VERSION ""

NS_ :

BS_:

BU_:  Battery  Charger  Host

BO_ 2566862841 BATT_diagnosticVBricksD_3: 4 Battery
 SG_ BATT_vBrick14_3 : 16|16@1+ (7.6e-05,0) [0|4.98066] "V" Host
 SG_ BATT_vBrick13_3 : 0|16@1+ (7.6e-05,0) [0|4.98066] "V" Host

BO_ 2566862842 BATT_diagnosticVBricksD_4: 4 Battery
 SG_ BATT_vBrick14_4 : 16|16@1+ (7.6e-05,0) [0|4.98066] "V" Host
 SG_ BATT_vBrick13_4 : 0|16@1+ (7.6e-05,0) [0|4.98066] "V" Host

BO_ 2566862843 BATT_diagnosticVBricksD_5: 4 Battery
 SG_ BATT_vBrick14_5 : 16|16@1+ (7.6e-05,0) [0|4.98066] "V" Host
 SG_ BATT_vBrick13_5 : 0|16@1+ (7.6e-05,0) [0|4.98066] "V" Host

BO_ 2566862844 BATT_diagnosticVBricksD_6: 4 Battery
 SG_ BATT_vBrick14_6 : 16|16@1+ (7.6e-05,0) [0|4.98066] "V" Host
 SG_ BATT_vBrick13_6 : 0|16@1+ (7.6e-05,0) [0|4.98066] "V" Host

BO_ 2566862845 BATT_diagnosticVBricksD_7: 4 Battery
 SG_ BATT_vBrick14_7 : 16|16@1+ (7.6e-05,0) [0|4.98066] "V" Host
 SG_ BATT_vBrick13_7 : 0|16@1+ (7.6e-05,0) [0|4.98066] "V" Host

BO_ 2566862846 BATT_diagnosticVBricksD_8: 4 Battery
 SG_ BATT_vBrick14_8 : 16|16@1+ (7.6e-05,0) [0|4.98066] "V" Host
 SG_ BATT_vBrick13_8 : 0|16@1+ (7.6e-05,0) [0|4.98066] "V" Host

BO_ 2566862847 BATT_diagnosticVBricksD_9: 4 Battery
 SG_ BATT_vBrick14_9 : 16|16@1+ (7.6e-05,0) [0|4.98066] "V" Host
 SG_ BATT_vBrick13_9 : 0|16@1+ (7.6e-05,0) [0|4.98066] "V" Host

BO_ 2566863094 BATT_diagnosticResBricksD_0: 4 Battery
 SG_ BATT_resBrick14_0 : 16|16@1+ (0.01,0) [0|655.35] "mOhms" Host
 SG_ BATT_resBrick13_0 : 0|16@1+ (0.01,0) [0|655.35] "mOhms" Host

BO_ 2566863095 BATT_diagnosticResBricksD_1: 4 Battery
 SG_ BATT_resBrick14_1 : 16|16@1+ (0.01,0) [0|655.35] "mOhms" Host
 SG_ BATT_resBrick13_1 : 0|16@1+ (0.01,0) [0|655.35] "mOhms" Host

BO_ 2566863096 BATT_diagnosticResBricksD_2: 4 Battery
 SG_ BATT_resBrick14_2 : 16|16@1+ (0.01,0) [0|655.35] "mOhms" Host
 SG_ BATT_resBrick13_2 : 0|16@1+ (0.01,0) [0|655.35] "mOhms" Host

BO_ 2566863097 BATT_diagnosticResBricksD_3: 4 Battery
 SG_ BATT_resBrick14_3 : 16|16@1+ (0.01,0) [0|655.35] "mOhms" Host
 SG_ BATT_resBrick13_3 : 0|16@1+ (0.01,0) [0|655.35] "mOhms" Host

BO_ 2566863098 BATT_diagnosticResBricksD_4: 4 Battery
 SG_ BATT_resBrick14_4 : 16|16@1+ (0.01,0) [0|655.35] "mOhms" Host
 SG_ BATT_resBrick13_4 : 0|16@1+ (0.01,0) [0|655.35] "mOhms" Host

BO_ 2566863099 BATT_diagnosticResBricksD_5: 4 Battery
 SG_ BATT_resBrick14_5 : 16|16@1+ (0.01,0) [0|655.35] "mOhms" Host
 SG_ BATT_resBrick13_5 : 0|16@1+ (0.01,0) [0|655.35] "mOhms" Host

BO_ 2566863100 BATT_diagnosticResBricksD_6: 4 Battery
 SG_ BATT_resBrick14_6 : 16|16@1+ (0.01,0) [0|655.35] "mOhms" Host
 SG_ BATT_resBrick13_6 : 0|16@1+ (0.01,0) [0|655.35] "mOhms" Host

BO_ 2566863101 BATT_diagnosticResBricksD_7: 4 Battery
 SG_ BATT_resBrick14_7 : 16|16@1+ (0.01,0) [0|655.35] "mOhms" Host
 SG_ BATT_resBrick13_7 : 0|16@1+ (0.01,0) [0|655.35] "mOhms" Host

BO_ 2566863102 BATT_diagnosticResBricksD_8: 4 Battery
 SG_ BATT_resBrick14_8 : 16|16@1+ (0.01,0) [0|655.35] "mOhms" Host
 SG_ BATT_resBrick13_8 : 0|16@1+ (0.01,0) [0|655.35] "mOhms" Host

BO_ 2566863103 BATT_diagnosticResBricksD_9: 4 Battery
 SG_ BATT_resBrick14_9 : 16|16@1+ (0.01,0) [0|655.35] "mOhms" Host
 SG_ BATT_resBrick13_9 : 0|16@1+ (0.01,0) [0|655.35] "mOhms" Host

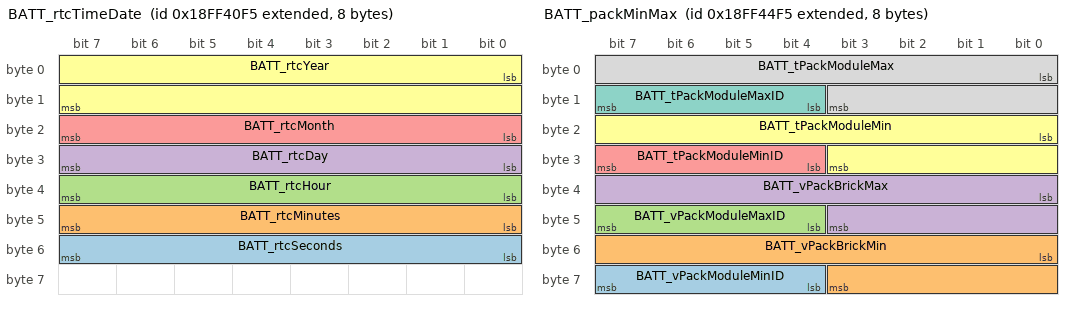
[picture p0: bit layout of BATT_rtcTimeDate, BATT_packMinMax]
BO_ 2566865141 BATT_rtcTimeDate: 8 Battery
 SG_ BATT_rtcSeconds : 48|8@1+ (1,0) [0|59] "" Host
 SG_ BATT_rtcMinutes : 40|8@1+ (1,0) [0|59] "" Host
 SG_ BATT_rtcHour : 32|8@1+ (1,0) [0|23] "" Host
 SG_ BATT_rtcDay : 24|8@1+ (1,0) [1|31] "" Host
 SG_ BATT_rtcMonth : 16|8@1+ (1,0) [1|12] "" Host
 SG_ BATT_rtcYear : 0|16@1+ (1,0) [2016|2099] "" Host

BO_ 2566865397 BATT_packHvStatus: 8 Battery
 SG_ BATT_iPackFiltered : 48|16@1- (0.05,0) [-1638.4|1638.35] "A" Host
 SG_ BATT_vPack : 32|16@1+ (0.01,0) [0|70] "V" Host
 SG_ BATT_vPackLoad : 0|16@1+ (0.01,0) [0|70] "V" Host
 SG_ BATT_iPack : 16|16@1- (0.04,0) [-1310.72|1310.68] "A" Host

BO_ 2566866165 BATT_packMinMax: 8 Battery
 SG_ BATT_vPackModuleMinID : 60|4@1+ (1,0) [0|10] "" Host
 SG_ BATT_vPackBrickMin : 48|12@1+ (0.002,0) [0|4.98066] "V" Host
 SG_ BATT_vPackModuleMaxID : 44|4@1+ (1,0) [0|10] "" Host
 SG_ BATT_vPackBrickMax : 32|12@1+ (0.002,0) [0|4.98066] "V" Host
 SG_ BATT_tPackModuleMinID : 28|4@1+ (1,0) [0|10] "" Host
 SG_ BATT_tPackModuleMin : 16|12@1- (0.1,0) [-40|125] "deg C" Host
 SG_ BATT_tPackModuleMaxID : 12|4@1+ (1,0) [0|10] "" Host
 SG_ BATT_tPackModuleMax : 0|12@1- (0.1,0) [-40|125] "deg C" Host

BO_ 2566866422 BATT_modSOC_0: 7 Battery
 SG_ BATT_sohcMod_0 : 0|16@1+ (0.01,0) [0|100] "%" Battery,Host
 SG_ BATT_socMod_0 : 16|16@1+ (0.01,0) [0|102.3] "%" Battery,Host
 SG_ BATT_socLimiting_0 : 32|16@1+ (0.01,0) [0|102.3] "%" Battery,Host
 SG_ BATT_idSOCLimiting_0 : 48|4@1+ (1,0) [0|14] "" Battery,Host

BO_ 2566866423 BATT_modSOC_1: 7 Battery
 SG_ BATT_sohcMod_1 : 0|16@1+ (0.01,0) [0|100] "%" Battery,Host
 SG_ BATT_socMod_1 : 16|16@1+ (0.01,0) [0|102.3] "%" Battery,Host
 SG_ BATT_socLimiting_1 : 32|16@1+ (0.01,0) [0|102.3] "%" Battery,Host
 SG_ BATT_idSOCLimiting_1 : 48|4@1+ (1,0) [0|14] "" Battery,Host

BO_ 2566866424 BATT_modSOC_2: 7 Battery
 SG_ BATT_sohcMod_2 : 0|16@1+ (0.01,0) [0|100] "%" Battery,Host
 SG_ BATT_socMod_2 : 16|16@1+ (0.01,0) [0|102.3] "%" Battery,Host
 SG_ BATT_socLimiting_2 : 32|16@1+ (0.01,0) [0|102.3] "%" Battery,Host
 SG_ BATT_idSOCLimiting_2 : 48|4@1+ (1,0) [0|14] "" Battery,Host

BO_ 2566866425 BATT_modSOC_3: 7 Battery
 SG_ BATT_sohcMod_3 : 0|16@1+ (0.01,0) [0|100] "%" Battery,Host
 SG_ BATT_socMod_3 : 16|16@1+ (0.01,0) [0|102.3] "%" Battery,Host
 SG_ BATT_socLimiting_3 : 32|16@1+ (0.01,0) [0|102.3] "%" Battery,Host
 SG_ BATT_idSOCLimiting_3 : 48|4@1+ (1,0) [0|14] "" Battery,Host

BO_ 2566866426 BATT_modSOC_4: 7 Battery
 SG_ BATT_sohcMod_4 : 0|16@1+ (0.01,0) [0|100] "%" Battery,Host
 SG_ BATT_socMod_4 : 16|16@1+ (0.01,0) [0|102.3] "%" Battery,Host
 SG_ BATT_socLimiting_4 : 32|16@1+ (0.01,0) [0|102.3] "%" Battery,Host
 SG_ BATT_idSOCLimiting_4 : 48|4@1+ (1,0) [0|14] "" Battery,Host

BO_ 2566866427 BATT_modSOC_5: 7 Battery
 SG_ BATT_sohcMod_5 : 0|16@1+ (0.01,0) [0|100] "%" Battery,Host
 SG_ BATT_socMod_5 : 16|16@1+ (0.01,0) [0|102.3] "%" Battery,Host
 SG_ BATT_socLimiting_5 : 32|16@1+ (0.01,0) [0|102.3] "%" Battery,Host
 SG_ BATT_idSOCLimiting_5 : 48|4@1+ (1,0) [0|14] "" Battery,Host

BO_ 2566866428 BATT_modSOC_6: 7 Battery
 SG_ BATT_sohcMod_6 : 0|16@1+ (0.01,0) [0|100] "%" Battery,Host
 SG_ BATT_socMod_6 : 16|16@1+ (0.01,0) [0|102.3] "%" Battery,Host
 SG_ BATT_socLimiting_6 : 32|16@1+ (0.01,0) [0|102.3] "%" Battery,Host
 SG_ BATT_idSOCLimiting_6 : 48|4@1+ (1,0) [0|14] "" Battery,Host

BO_ 2566866429 BATT_modSOC_7: 7 Battery
 SG_ BATT_sohcMod_7 : 0|16@1+ (0.01,0) [0|100] "%" Battery,Host
 SG_ BATT_socMod_7 : 16|16@1+ (0.01,0) [0|102.3] "%" Battery,Host
 SG_ BATT_socLimiting_7 : 32|16@1+ (0.01,0) [0|102.3] "%" Battery,Host
 SG_ BATT_idSOCLimiting_7 : 48|4@1+ (1,0) [0|14] "" Battery,Host

BO_ 2566866430 BATT_modSOC_8: 7 Battery
 SG_ BATT_sohcMod_8 : 0|16@1+ (0.01,0) [0|100] "%" Battery,Host
 SG_ BATT_socMod_8 : 16|16@1+ (0.01,0) [0|102.3] "%" Battery,Host
 SG_ BATT_socLimiting_8 : 32|16@1+ (0.01,0) [0|102.3] "%" Battery,Host
 SG_ BATT_idSOCLimiting_8 : 48|4@1+ (1,0) [0|14] "" Battery,Host

BO_ 2566866431 BATT_modSOC_9: 7 Battery
 SG_ BATT_sohcMod_9 : 0|16@1+ (0.01,0) [0|100] "%" Battery,Host
 SG_ BATT_socMod_9 : 16|16@1+ (0.01,0) [0|102.3] "%" Battery,Host
 SG_ BATT_socLimiting_9 : 32|16@1+ (0.01,0) [0|102.3] "%" Battery,Host
 SG_ BATT_idSOCLimiting_9 : 48|4@1+ (1,0) [0|14] "" Battery,Host

BO_ 2566866677 BATT_packSOC: 4 Battery
 SG_ BATT_packUserSOC : 0|16@1+ (0.1,0) [0|102.3] "%" Host
 SG_ BATT_packSOC : 16|16@1+ (0.1,0) [0|102.3] "%" Host

BO_ 2566866678 BATT_diagnosticSleepWake_0: 8 Battery
 SG_ BATT_timeSleepCycle_0 : 32|32@1+ (1,0) [0|4294967295] "seconds" Host
 SG_ BATT_timeWakeCycle_0 : 0|32@1+ (1,0) [0|4294967295] "seconds" Host

BO_ 2566866679 BATT_diagnosticSleepWake_1: 8 Battery
 SG_ BATT_timeSleepCycle_1 : 32|32@1+ (1,0) [0|4294967295] "seconds" Host
 SG_ BATT_timeWakeCycle_1 : 0|32@1+ (1,0) [0|4294967295] "seconds" Host

BO_ 2566866680 BATT_diagnosticSleepWake_2: 8 Battery
 SG_ BATT_timeSleepCycle_2 : 32|32@1+ (1,0) [0|4294967295] "seconds" Host
 SG_ BATT_timeWakeCycle_2 : 0|32@1+ (1,0) [0|4294967295] "seconds" Host

BO_ 2566866681 BATT_diagnosticSleepWake_3: 8 Battery
 SG_ BATT_timeSleepCycle_3 : 32|32@1+ (1,0) [0|4294967295] "seconds" Host
 SG_ BATT_timeWakeCycle_3 : 0|32@1+ (1,0) [0|4294967295] "seconds" Host

BO_ 2566866682 BATT_diagnosticSleepWake_4: 8 Battery
 SG_ BATT_timeSleepCycle_4 : 32|32@1+ (1,0) [0|4294967295] "seconds" Host
 SG_ BATT_timeWakeCycle_4 : 0|32@1+ (1,0) [0|4294967295] "seconds" Host

BO_ 2566866683 BATT_diagnosticSleepWake_5: 8 Battery
 SG_ BATT_timeSleepCycle_5 : 32|32@1+ (1,0) [0|4294967295] "seconds" Host
 SG_ BATT_timeWakeCycle_5 : 0|32@1+ (1,0) [0|4294967295] "seconds" Host

BO_ 2566866684 BATT_diagnosticSleepWake_6: 8 Battery
 SG_ BATT_timeSleepCycle_6 : 32|32@1+ (1,0) [0|4294967295] "seconds" Host
 SG_ BATT_timeWakeCycle_6 : 0|32@1+ (1,0) [0|4294967295] "seconds" Host

BO_ 2566866685 BATT_diagnosticSleepWake_7: 8 Battery
 SG_ BATT_timeSleepCycle_7 : 32|32@1+ (1,0) [0|4294967295] "seconds" Host
 SG_ BATT_timeWakeCycle_7 : 0|32@1+ (1,0) [0|4294967295] "seconds" Host

BO_ 2566866686 BATT_diagnosticSleepWake_8: 8 Battery
 SG_ BATT_timeSleepCycle_8 : 32|32@1+ (1,0) [0|4294967295] "seconds" Host
 SG_ BATT_timeWakeCycle_8 : 0|32@1+ (1,0) [0|4294967295] "seconds" Host

BO_ 2566866687 BATT_diagnosticSleepWake_9: 8 Battery
 SG_ BATT_timeSleepCycle_9 : 32|32@1+ (1,0) [0|4294967295] "seconds" Host
 SG_ BATT_timeWakeCycle_9 : 0|32@1+ (1,0) [0|4294967295] "seconds" Host

BO_ 2566867189 BATT_packDchLimits: 8 Battery
 SG_ BATT_vBusMin : 48|16@1+ (0.005,0) [0|70] "V" Host
 SG_ BATT_iPackDchLimit30s : 16|16@1- (0.2,0) [-6553.6|6553.4] "A" Host
 SG_ BATT_iPackDchLimit10s : 0|16@1- (0.2,0) [-6553.6|6553.4] "A" Host
 SG_ BATT_iPackDchLimitCont : 32|16@1- (0.2,0) [-6553.6|6553.4] "A" Host

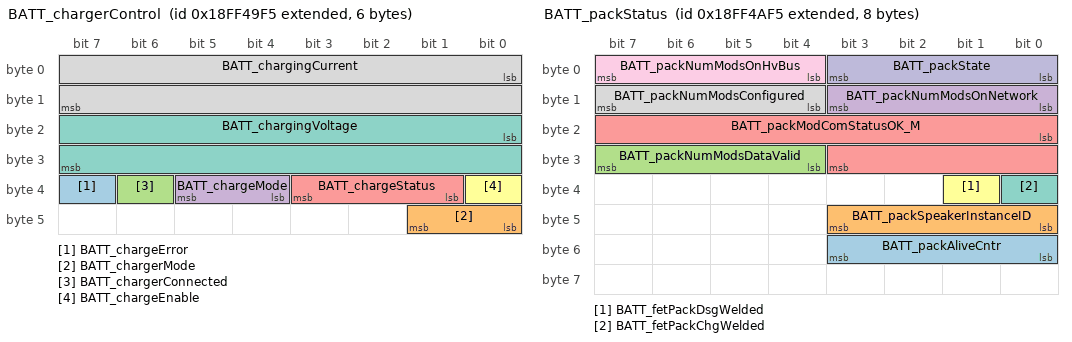
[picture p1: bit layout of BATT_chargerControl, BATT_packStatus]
BO_ 2566867445 BATT_chargerControl: 6 Battery
 SG_ BATT_chargeError : 39|1@1+ (1,0) [0|1] "" Battery,Host
 SG_ BATT_chargerMode : 40|2@1+ (1,0) [0|3] "" Host
 SG_ BATT_chargerConnected : 38|1@1+ (1,0) [0|1] "" Battery,Host
 SG_ BATT_chargeMode : 36|2@1+ (1,0) [0|3] "" Host
 SG_ BATT_chargeStatus : 33|3@1+ (1,0) [0|4] "" Charger,Host
 SG_ BATT_chargeEnable : 32|1@1+ (1,0) [0|1] "" Charger,Host
 SG_ BATT_chargingVoltage : 16|16@1+ (0.005,0) [0|70] "V" Charger,Host
 SG_ BATT_chargingCurrent : 0|16@1+ (0.01,0) [0|84] "A" Charger,Host

BO_ 2566867701 BATT_packStatus: 8 Battery
 SG_ BATT_packAliveCntr : 48|4@1+ (1,0) [0|15] "" Host
 SG_ BATT_packSpeakerInstanceID : 40|4@1+ (1,0) [0|15] "" Host
 SG_ BATT_packNumModsDataValid : 28|4@1+ (1,0) [0|15] "" Host
 SG_ BATT_packNumModsOnNetwork : 8|4@1+ (1,0) [0|15] "" Host
 SG_ BATT_packModComStatusOK_M : 16|12@1+ (1,0) [0|4095] "" Host
 SG_ BATT_fetPackDsgWelded : 33|1@1+ (1,0) [0|1] "" Host
 SG_ BATT_fetPackChgWelded : 32|1@1+ (1,0) [0|1] "" Host
 SG_ BATT_packNumModsConfigured : 12|4@1+ (1,0) [0|15] "" Host
 SG_ BATT_packNumModsOnHvBus : 4|4@1+ (1,0) [0|15] "" Host
 SG_ BATT_packState : 0|4@1+ (1,0) [0|15] "" Host

BO_ 2566869493 BATT_packDiagnosticConnectedBus: 6 Battery
 SG_ BATT_vPackConnBusBrickMin : 16|12@1+ (0.002,0) [0|4.98066] "V" Host
 SG_ BATT_vPackConnBusBrickMax : 32|12@1+ (0.002,0) [0|4.98066] "V" Host
 SG_ BATT_packConnBusSOC : 0|16@1+ (0.1,0) [0|102.3] "%" Host

BO_ 2566870005 BATT_packCapacity: 4 Battery
 SG_ BATT_packRemainingCap_Ah : 16|16@1+ (0.025,0) [0|1638.375] "Ah" Host
 SG_ BATT_packFullChargeCap_Ah : 0|16@1+ (0.025,0) [0|1638.375] "Ah" Host

BO_ 2566870517 BATT_chargingPID: 8 Battery
 SG_ dbg_vPID_out : 48|16@1+ (0.01,0) [0|100] "" Host
 SG_ dbg_vPID_ierror : 32|16@1+ (0.1,0) [0|2000] "" Host
 SG_ dbg_iPID_out : 16|16@1+ (0.01,0) [0|100] "" Host
 SG_ dbg_iPID_ierror : 0|16@1+ (0.1,0) [0|2000] "" Host

BO_ 2566870774 BATT_diagnosticVBricksA_0: 8 Battery
 SG_ BATT_vBrick02_0 : 16|16@1+ (7.6e-05,0) [0|4.98066] "V" Host
 SG_ BATT_vBrick03_0 : 32|16@1+ (7.6e-05,0) [0|4.98066] "V" Host
 SG_ BATT_vBrick01_0 : 0|16@1+ (7.6e-05,0) [0|4.98066] "V" Host
 SG_ BATT_vBrick04_0 : 48|16@1+ (7.6e-05,0) [0|4.98066] "V" Host

BO_ 2566870775 BATT_diagnosticVBricksA_1: 8 Battery
 SG_ BATT_vBrick02_1 : 16|16@1+ (7.6e-05,0) [0|4.98066] "V" Host
 SG_ BATT_vBrick03_1 : 32|16@1+ (7.6e-05,0) [0|4.98066] "V" Host
 SG_ BATT_vBrick01_1 : 0|16@1+ (7.6e-05,0) [0|4.98066] "V" Host
 SG_ BATT_vBrick04_1 : 48|16@1+ (7.6e-05,0) [0|4.98066] "V" Host

BO_ 2566870776 BATT_diagnosticVBricksA_2: 8 Battery
 SG_ BATT_vBrick02_2 : 16|16@1+ (7.6e-05,0) [0|4.98066] "V" Host
 SG_ BATT_vBrick03_2 : 32|16@1+ (7.6e-05,0) [0|4.98066] "V" Host
 SG_ BATT_vBrick01_2 : 0|16@1+ (7.6e-05,0) [0|4.98066] "V" Host
 SG_ BATT_vBrick04_2 : 48|16@1+ (7.6e-05,0) [0|4.98066] "V" Host

BO_ 2566870777 BATT_diagnosticVBricksA_3: 8 Battery
 SG_ BATT_vBrick02_3 : 16|16@1+ (7.6e-05,0) [0|4.98066] "V" Host
 SG_ BATT_vBrick03_3 : 32|16@1+ (7.6e-05,0) [0|4.98066] "V" Host
 SG_ BATT_vBrick01_3 : 0|16@1+ (7.6e-05,0) [0|4.98066] "V" Host
 SG_ BATT_vBrick04_3 : 48|16@1+ (7.6e-05,0) [0|4.98066] "V" Host

BO_ 2566870778 BATT_diagnosticVBricksA_4: 8 Battery
 SG_ BATT_vBrick02_4 : 16|16@1+ (7.6e-05,0) [0|4.98066] "V" Host
 SG_ BATT_vBrick03_4 : 32|16@1+ (7.6e-05,0) [0|4.98066] "V" Host
 SG_ BATT_vBrick01_4 : 0|16@1+ (7.6e-05,0) [0|4.98066] "V" Host
 SG_ BATT_vBrick04_4 : 48|16@1+ (7.6e-05,0) [0|4.98066] "V" Host

BO_ 2566870779 BATT_diagnosticVBricksA_5: 8 Battery
 SG_ BATT_vBrick02_5 : 16|16@1+ (7.6e-05,0) [0|4.98066] "V" Host
 SG_ BATT_vBrick03_5 : 32|16@1+ (7.6e-05,0) [0|4.98066] "V" Host
 SG_ BATT_vBrick01_5 : 0|16@1+ (7.6e-05,0) [0|4.98066] "V" Host
 SG_ BATT_vBrick04_5 : 48|16@1+ (7.6e-05,0) [0|4.98066] "V" Host

BO_ 2566870780 BATT_diagnosticVBricksA_6: 8 Battery
 SG_ BATT_vBrick02_6 : 16|16@1+ (7.6e-05,0) [0|4.98066] "V" Host
 SG_ BATT_vBrick03_6 : 32|16@1+ (7.6e-05,0) [0|4.98066] "V" Host
 SG_ BATT_vBrick01_6 : 0|16@1+ (7.6e-05,0) [0|4.98066] "V" Host
 SG_ BATT_vBrick04_6 : 48|16@1+ (7.6e-05,0) [0|4.98066] "V" Host

BO_ 2566870781 BATT_diagnosticVBricksA_7: 8 Battery
 SG_ BATT_vBrick02_7 : 16|16@1+ (7.6e-05,0) [0|4.98066] "V" Host
 SG_ BATT_vBrick03_7 : 32|16@1+ (7.6e-05,0) [0|4.98066] "V" Host
 SG_ BATT_vBrick01_7 : 0|16@1+ (7.6e-05,0) [0|4.98066] "V" Host
 SG_ BATT_vBrick04_7 : 48|16@1+ (7.6e-05,0) [0|4.98066] "V" Host

BO_ 2566870782 BATT_diagnosticVBricksA_8: 8 Battery
 SG_ BATT_vBrick02_8 : 16|16@1+ (7.6e-05,0) [0|4.98066] "V" Host
 SG_ BATT_vBrick03_8 : 32|16@1+ (7.6e-05,0) [0|4.98066] "V" Host
 SG_ BATT_vBrick01_8 : 0|16@1+ (7.6e-05,0) [0|4.98066] "V" Host
 SG_ BATT_vBrick04_8 : 48|16@1+ (7.6e-05,0) [0|4.98066] "V" Host

BO_ 2566870783 BATT_diagnosticVBricksA_9: 8 Battery
 SG_ BATT_vBrick02_9 : 16|16@1+ (7.6e-05,0) [0|4.98066] "V" Host
 SG_ BATT_vBrick03_9 : 32|16@1+ (7.6e-05,0) [0|4.98066] "V" Host
 SG_ BATT_vBrick01_9 : 0|16@1+ (7.6e-05,0) [0|4.98066] "V" Host
 SG_ BATT_vBrick04_9 : 48|16@1+ (7.6e-05,0) [0|4.98066] "V" Host

BO_ 2566871285 BATT_packPwrAvailable: 4 Battery
 SG_ BATT_pwrPackDchLimit : 16|16@1+ (0.02,0) [0|1200] "kW" Host
 SG_ BATT_pwrPackChgLimit : 0|16@1+ (0.02,0) [0|1200] "kW" Host

BO_ 2566871376 CHRG_chargingControl: 4 Charger
 SG_ CHRG_chargerEnabled : 12|1@1+ (1,0) [0|1] "" Battery
 SG_ CHRG_chargingVoltage : 16|16@1+ (0.00076,0) [0|49.8066] "V" Battery
 SG_ CHRG_chargingCurrent : 0|12@1+ (0.01,0) [0|40.95] "A" Battery

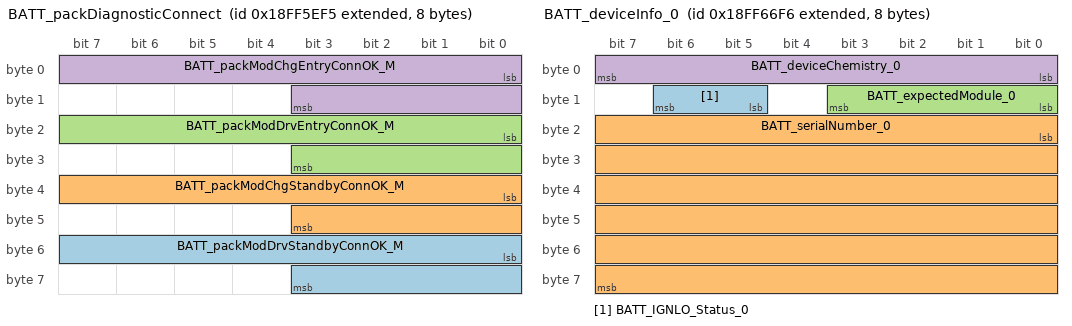
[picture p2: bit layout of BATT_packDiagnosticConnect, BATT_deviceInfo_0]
BO_ 2566872821 BATT_packDiagnosticConnect: 8 Battery
 SG_ BATT_packModDrvStandbyConnOK_M : 48|12@1+ (1,0) [0|4095] "" Host
 SG_ BATT_packModChgStandbyConnOK_M : 32|12@1+ (1,0) [0|4095] "" Host
 SG_ BATT_packModDrvEntryConnOK_M : 16|12@1+ (1,0) [0|4095] "" Host
 SG_ BATT_packModChgEntryConnOK_M : 0|12@1+ (1,0) [0|4095] "" Host

BO_ 2566873333 NODE_ID_CLAIM: 8 Battery
 SG_ NODE_ID_CLAIM_RND : 34|30@1+ (1,0) [0|4294967295] "" Battery,Host
 SG_ NODE_ID_CLAIM_SN : 0|34@1+ (1,0) [0|4294967295] "" Battery,Host

BO_ 2566874870 BATT_deviceInfo_0: 8 Battery
 SG_ BATT_IGNLO_Status_0 : 13|2@1+ (1,0) [0|3] "" Battery,Host
 SG_ BATT_serialNumber_0 : 16|48@1+ (1,0) [0|281474976710655] "" Battery,Host
 SG_ BATT_expectedModule_0 : 8|4@1+ (1,0) [0|15] "" Battery,Host
 SG_ BATT_deviceChemistry_0 : 0|8@1+ (1,0) [0|255] "" Battery,Host

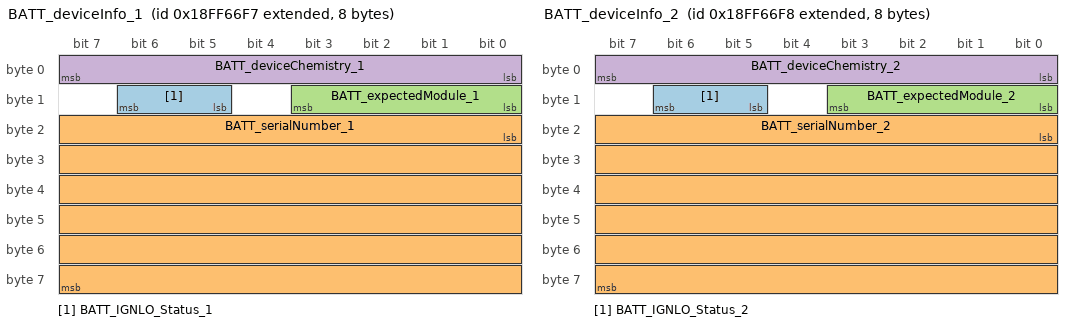
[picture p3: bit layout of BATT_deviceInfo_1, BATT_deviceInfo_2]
BO_ 2566874871 BATT_deviceInfo_1: 8 Battery
 SG_ BATT_IGNLO_Status_1 : 13|2@1+ (1,0) [0|3] "" Battery,Host
 SG_ BATT_serialNumber_1 : 16|48@1+ (1,0) [0|281474976710655] "" Battery,Host
 SG_ BATT_expectedModule_1 : 8|4@1+ (1,0) [0|15] "" Battery,Host
 SG_ BATT_deviceChemistry_1 : 0|8@1+ (1,0) [0|255] "" Battery,Host

BO_ 2566874872 BATT_deviceInfo_2: 8 Battery
 SG_ BATT_IGNLO_Status_2 : 13|2@1+ (1,0) [0|3] "" Battery,Host
 SG_ BATT_serialNumber_2 : 16|48@1+ (1,0) [0|281474976710655] "" Battery,Host
 SG_ BATT_expectedModule_2 : 8|4@1+ (1,0) [0|15] "" Battery,Host
 SG_ BATT_deviceChemistry_2 : 0|8@1+ (1,0) [0|255] "" Battery,Host

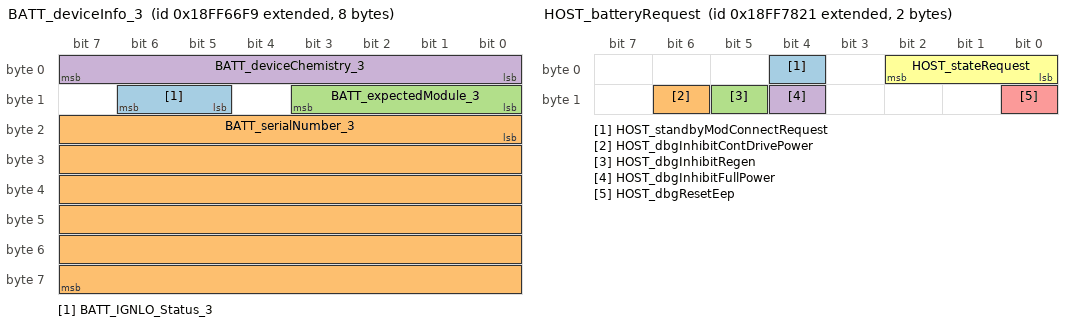
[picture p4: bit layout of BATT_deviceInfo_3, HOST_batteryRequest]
BO_ 2566874873 BATT_deviceInfo_3: 8 Battery
 SG_ BATT_IGNLO_Status_3 : 13|2@1+ (1,0) [0|3] "" Battery,Host
 SG_ BATT_serialNumber_3 : 16|48@1+ (1,0) [0|281474976710655] "" Battery,Host
 SG_ BATT_expectedModule_3 : 8|4@1+ (1,0) [0|15] "" Battery,Host
 SG_ BATT_deviceChemistry_3 : 0|8@1+ (1,0) [0|255] "" Battery,Host

BO_ 2566874874 BATT_deviceInfo_4: 8 Battery
 SG_ BATT_IGNLO_Status_4 : 13|2@1+ (1,0) [0|3] "" Battery,Host
 SG_ BATT_serialNumber_4 : 16|48@1+ (1,0) [0|281474976710655] "" Battery,Host
 SG_ BATT_expectedModule_4 : 8|4@1+ (1,0) [0|15] "" Battery,Host
 SG_ BATT_deviceChemistry_4 : 0|8@1+ (1,0) [0|255] "" Battery,Host

BO_ 2566874875 BATT_deviceInfo_5: 8 Battery
 SG_ BATT_IGNLO_Status_5 : 13|2@1+ (1,0) [0|3] "" Battery,Host
 SG_ BATT_serialNumber_5 : 16|48@1+ (1,0) [0|281474976710655] "" Battery,Host
 SG_ BATT_expectedModule_5 : 8|4@1+ (1,0) [0|15] "" Battery,Host
 SG_ BATT_deviceChemistry_5 : 0|8@1+ (1,0) [0|255] "" Battery,Host

BO_ 2566874876 BATT_deviceInfo_6: 8 Battery
 SG_ BATT_IGNLO_Status_6 : 13|2@1+ (1,0) [0|3] "" Battery,Host
 SG_ BATT_serialNumber_6 : 16|48@1+ (1,0) [0|281474976710655] "" Battery,Host
 SG_ BATT_expectedModule_6 : 8|4@1+ (1,0) [0|15] "" Battery,Host
 SG_ BATT_deviceChemistry_6 : 0|8@1+ (1,0) [0|255] "" Battery,Host

BO_ 2566874877 BATT_deviceInfo_7: 8 Battery
 SG_ BATT_IGNLO_Status_7 : 13|2@1+ (1,0) [0|3] "" Battery,Host
 SG_ BATT_serialNumber_7 : 16|48@1+ (1,0) [0|281474976710655] "" Battery,Host
 SG_ BATT_expectedModule_7 : 8|4@1+ (1,0) [0|15] "" Battery,Host
 SG_ BATT_deviceChemistry_7 : 0|8@1+ (1,0) [0|255] "" Battery,Host

BO_ 2566874878 BATT_deviceInfo_8: 8 Battery
 SG_ BATT_IGNLO_Status_8 : 13|2@1+ (1,0) [0|3] "" Battery,Host
 SG_ BATT_serialNumber_8 : 16|48@1+ (1,0) [0|281474976710655] "" Battery,Host
 SG_ BATT_expectedModule_8 : 8|4@1+ (1,0) [0|15] "" Battery,Host
 SG_ BATT_deviceChemistry_8 : 0|8@1+ (1,0) [0|255] "" Battery,Host

BO_ 2566874879 BATT_deviceInfo_9: 8 Battery
 SG_ BATT_IGNLO_Status_9 : 13|2@1+ (1,0) [0|3] "" Battery,Host
 SG_ BATT_serialNumber_9 : 16|48@1+ (1,0) [0|281474976710655] "" Battery,Host
 SG_ BATT_expectedModule_9 : 8|4@1+ (1,0) [0|15] "" Battery,Host
 SG_ BATT_deviceChemistry_9 : 0|8@1+ (1,0) [0|255] "" Battery,Host

BO_ 2566878966 BATT_diagnosticAhTotal_0: 8 Battery
 SG_ BATT_ahDchTotal_0 : 32|32@1+ (0.1,0) [0|500000] "Ah" Host
 SG_ BATT_ahChgTotal_0 : 0|32@1+ (0.1,0) [0|500000] "Ah" Host

BO_ 2566878967 BATT_diagnosticAhTotal_1: 8 Battery
 SG_ BATT_ahDchTotal_1 : 32|32@1+ (0.1,0) [0|500000] "Ah" Host
 SG_ BATT_ahChgTotal_1 : 0|32@1+ (0.1,0) [0|500000] "Ah" Host

BO_ 2566878968 BATT_diagnosticAhTotal_2: 8 Battery
 SG_ BATT_ahDchTotal_2 : 32|32@1+ (0.1,0) [0|500000] "Ah" Host
 SG_ BATT_ahChgTotal_2 : 0|32@1+ (0.1,0) [0|500000] "Ah" Host

BO_ 2566878969 BATT_diagnosticAhTotal_3: 8 Battery
 SG_ BATT_ahDchTotal_3 : 32|32@1+ (0.1,0) [0|500000] "Ah" Host
 SG_ BATT_ahChgTotal_3 : 0|32@1+ (0.1,0) [0|500000] "Ah" Host

BO_ 2566878970 BATT_diagnosticAhTotal_4: 8 Battery
 SG_ BATT_ahDchTotal_4 : 32|32@1+ (0.1,0) [0|500000] "Ah" Host
 SG_ BATT_ahChgTotal_4 : 0|32@1+ (0.1,0) [0|500000] "Ah" Host

BO_ 2566878971 BATT_diagnosticAhTotal_5: 8 Battery
 SG_ BATT_ahDchTotal_5 : 32|32@1+ (0.1,0) [0|500000] "Ah" Host
 SG_ BATT_ahChgTotal_5 : 0|32@1+ (0.1,0) [0|500000] "Ah" Host

BO_ 2566878972 BATT_diagnosticAhTotal_6: 8 Battery
 SG_ BATT_ahDchTotal_6 : 32|32@1+ (0.1,0) [0|500000] "Ah" Host
 SG_ BATT_ahChgTotal_6 : 0|32@1+ (0.1,0) [0|500000] "Ah" Host

BO_ 2566878973 BATT_diagnosticAhTotal_7: 8 Battery
 SG_ BATT_ahDchTotal_7 : 32|32@1+ (0.1,0) [0|500000] "Ah" Host
 SG_ BATT_ahChgTotal_7 : 0|32@1+ (0.1,0) [0|500000] "Ah" Host

BO_ 2566878974 BATT_diagnosticAhTotal_8: 8 Battery
 SG_ BATT_ahDchTotal_8 : 32|32@1+ (0.1,0) [0|500000] "Ah" Host
 SG_ BATT_ahChgTotal_8 : 0|32@1+ (0.1,0) [0|500000] "Ah" Host

BO_ 2566878975 BATT_diagnosticAhTotal_9: 8 Battery
 SG_ BATT_ahDchTotal_9 : 32|32@1+ (0.1,0) [0|500000] "Ah" Host
 SG_ BATT_ahChgTotal_9 : 0|32@1+ (0.1,0) [0|500000] "Ah" Host

BO_ 2566879265 HOST_batteryRequest: 2 Host
 SG_ HOST_standbyModConnectRequest : 4|1@1+ (1,0) [0|1] "" Battery
 SG_ HOST_dbgInhibitContDrivePower : 14|1@1+ (1,0) [0|1] "" Battery
 SG_ HOST_dbgInhibitRegen : 13|1@1+ (1,0) [0|1] "" Battery
 SG_ HOST_dbgInhibitFullPower : 12|1@1+ (1,0) [0|1] "" Battery
 SG_ HOST_dbgResetEep : 8|1@1+ (1,0) [0|1] "" Battery
 SG_ HOST_stateRequest : 0|3@1+ (1,0) [0|4] "" Battery

BO_ 2566881313 HOST_nodeRequest: 8 Host
 SG_ HOST_securityKey : 16|48@1+ (1,0) [0|281474976710655] "" Battery
 SG_ HOST_startNodeId : 0|1@1+ (1,0) [0|1] "" Battery

BO_ 2566881525 BATT_packChgLimits: 8 Battery
 SG_ BATT_vBusMax : 48|16@1+ (0.005,0) [0|70] "V" Host
 SG_ BATT_iPackChgLimit30s : 16|16@1+ (0.2,0) [0|13107] "A" Host
 SG_ BATT_iPackChgLimit10s : 0|16@1+ (0.2,0) [0|13107] "A" Host
 SG_ BATT_iPackChgLimitCont : 32|16@1+ (0.2,0) [0|13107] "A" Host

BO_ 2566883062 BATT_diagnosticCapBricksA_0: 8 Battery
 SG_ BATT_capBrick04_0 : 48|16@1+ (0.0025,0) [0|163.8375] "Ah" Host
 SG_ BATT_capBrick03_0 : 32|16@1+ (0.0025,0) [0|163.8375] "Ah" Host
 SG_ BATT_capBrick02_0 : 16|16@1+ (0.0025,0) [0|163.8375] "Ah" Host
 SG_ BATT_capBrick01_0 : 0|16@1+ (0.0025,0) [0|163.8375] "Ah" Host

BO_ 2566883063 BATT_diagnosticCapBricksA_1: 8 Battery
 SG_ BATT_capBrick04_1 : 48|16@1+ (0.0025,0) [0|163.8375] "Ah" Host
 SG_ BATT_capBrick03_1 : 32|16@1+ (0.0025,0) [0|163.8375] "Ah" Host
 SG_ BATT_capBrick02_1 : 16|16@1+ (0.0025,0) [0|163.8375] "Ah" Host
 SG_ BATT_capBrick01_1 : 0|16@1+ (0.0025,0) [0|163.8375] "Ah" Host

BO_ 2566883064 BATT_diagnosticCapBricksA_2: 8 Battery
 SG_ BATT_capBrick04_2 : 48|16@1+ (0.0025,0) [0|163.8375] "Ah" Host
 SG_ BATT_capBrick03_2 : 32|16@1+ (0.0025,0) [0|163.8375] "Ah" Host
 SG_ BATT_capBrick02_2 : 16|16@1+ (0.0025,0) [0|163.8375] "Ah" Host
 SG_ BATT_capBrick01_2 : 0|16@1+ (0.0025,0) [0|163.8375] "Ah" Host

BO_ 2566883065 BATT_diagnosticCapBricksA_3: 8 Battery
 SG_ BATT_capBrick04_3 : 48|16@1+ (0.0025,0) [0|163.8375] "Ah" Host
 SG_ BATT_capBrick03_3 : 32|16@1+ (0.0025,0) [0|163.8375] "Ah" Host
 SG_ BATT_capBrick02_3 : 16|16@1+ (0.0025,0) [0|163.8375] "Ah" Host
 SG_ BATT_capBrick01_3 : 0|16@1+ (0.0025,0) [0|163.8375] "Ah" Host

BO_ 2566883066 BATT_diagnosticCapBricksA_4: 8 Battery
 SG_ BATT_capBrick04_4 : 48|16@1+ (0.0025,0) [0|163.8375] "Ah" Host
 SG_ BATT_capBrick03_4 : 32|16@1+ (0.0025,0) [0|163.8375] "Ah" Host
 SG_ BATT_capBrick02_4 : 16|16@1+ (0.0025,0) [0|163.8375] "Ah" Host
 SG_ BATT_capBrick01_4 : 0|16@1+ (0.0025,0) [0|163.8375] "Ah" Host

BO_ 2566883067 BATT_diagnosticCapBricksA_5: 8 Battery
 SG_ BATT_capBrick04_5 : 48|16@1+ (0.0025,0) [0|163.8375] "Ah" Host
 SG_ BATT_capBrick03_5 : 32|16@1+ (0.0025,0) [0|163.8375] "Ah" Host
 SG_ BATT_capBrick02_5 : 16|16@1+ (0.0025,0) [0|163.8375] "Ah" Host
 SG_ BATT_capBrick01_5 : 0|16@1+ (0.0025,0) [0|163.8375] "Ah" Host

BO_ 2566883068 BATT_diagnosticCapBricksA_6: 8 Battery
 SG_ BATT_capBrick04_6 : 48|16@1+ (0.0025,0) [0|163.8375] "Ah" Host
 SG_ BATT_capBrick03_6 : 32|16@1+ (0.0025,0) [0|163.8375] "Ah" Host
 SG_ BATT_capBrick02_6 : 16|16@1+ (0.0025,0) [0|163.8375] "Ah" Host
 SG_ BATT_capBrick01_6 : 0|16@1+ (0.0025,0) [0|163.8375] "Ah" Host

BO_ 2566883069 BATT_diagnosticCapBricksA_7: 8 Battery
 SG_ BATT_capBrick04_7 : 48|16@1+ (0.0025,0) [0|163.8375] "Ah" Host
 SG_ BATT_capBrick03_7 : 32|16@1+ (0.0025,0) [0|163.8375] "Ah" Host
 SG_ BATT_capBrick02_7 : 16|16@1+ (0.0025,0) [0|163.8375] "Ah" Host
 SG_ BATT_capBrick01_7 : 0|16@1+ (0.0025,0) [0|163.8375] "Ah" Host

BO_ 2566883070 BATT_diagnosticCapBricksA_8: 8 Battery
 SG_ BATT_capBrick04_8 : 48|16@1+ (0.0025,0) [0|163.8375] "Ah" Host
 SG_ BATT_capBrick03_8 : 32|16@1+ (0.0025,0) [0|163.8375] "Ah" Host
 SG_ BATT_capBrick02_8 : 16|16@1+ (0.0025,0) [0|163.8375] "Ah" Host
 SG_ BATT_capBrick01_8 : 0|16@1+ (0.0025,0) [0|163.8375] "Ah" Host

BO_ 2566883071 BATT_diagnosticCapBricksA_9: 8 Battery
 SG_ BATT_capBrick04_9 : 48|16@1+ (0.0025,0) [0|163.8375] "Ah" Host
 SG_ BATT_capBrick03_9 : 32|16@1+ (0.0025,0) [0|163.8375] "Ah" Host
 SG_ BATT_capBrick02_9 : 16|16@1+ (0.0025,0) [0|163.8375] "Ah" Host
 SG_ BATT_capBrick01_9 : 0|16@1+ (0.0025,0) [0|163.8375] "Ah" Host

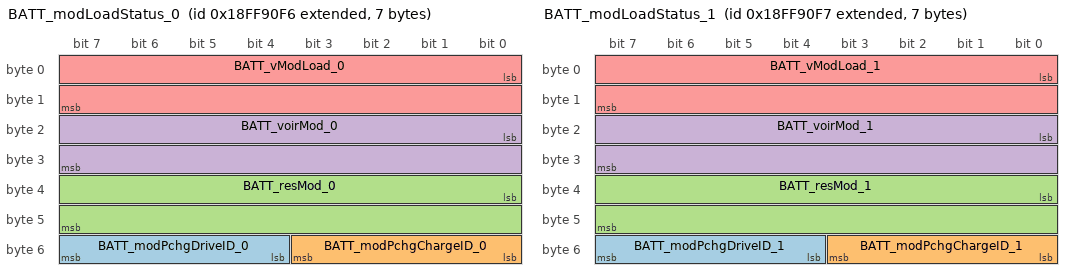
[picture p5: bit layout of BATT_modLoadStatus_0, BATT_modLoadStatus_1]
BO_ 2566885622 BATT_modLoadStatus_0: 7 Battery
 SG_ BATT_modPchgDriveID_0 : 52|4@1+ (1,0) [0|15] "" Host,Battery
 SG_ BATT_modPchgChargeID_0 : 48|4@1+ (1,0) [0|15] "" Host,Battery
 SG_ BATT_resMod_0 : 32|16@1+ (0.01,0) [0|655.35] "mOhms" Host
 SG_ BATT_voirMod_0 : 16|16@1+ (0.01,0) [0|70] "V" Host
 SG_ BATT_vModLoad_0 : 0|16@1+ (0.01,0) [0|70] "V" Battery,Host

BO_ 2566885623 BATT_modLoadStatus_1: 7 Battery
 SG_ BATT_modPchgDriveID_1 : 52|4@1+ (1,0) [0|15] "" Host,Battery
 SG_ BATT_modPchgChargeID_1 : 48|4@1+ (1,0) [0|15] "" Host,Battery
 SG_ BATT_resMod_1 : 32|16@1+ (0.01,0) [0|655.35] "mOhms" Host
 SG_ BATT_voirMod_1 : 16|16@1+ (0.01,0) [0|70] "V" Host
 SG_ BATT_vModLoad_1 : 0|16@1+ (0.01,0) [0|70] "V" Battery,Host

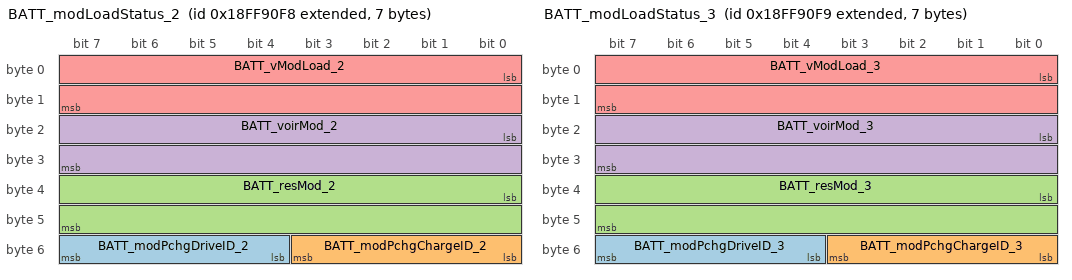
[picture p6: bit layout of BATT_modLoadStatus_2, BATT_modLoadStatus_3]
BO_ 2566885624 BATT_modLoadStatus_2: 7 Battery
 SG_ BATT_modPchgDriveID_2 : 52|4@1+ (1,0) [0|15] "" Host,Battery
 SG_ BATT_modPchgChargeID_2 : 48|4@1+ (1,0) [0|15] "" Host,Battery
 SG_ BATT_resMod_2 : 32|16@1+ (0.01,0) [0|655.35] "mOhms" Host
 SG_ BATT_voirMod_2 : 16|16@1+ (0.01,0) [0|70] "V" Host
 SG_ BATT_vModLoad_2 : 0|16@1+ (0.01,0) [0|70] "V" Battery,Host

BO_ 2566885625 BATT_modLoadStatus_3: 7 Battery
 SG_ BATT_modPchgDriveID_3 : 52|4@1+ (1,0) [0|15] "" Host,Battery
 SG_ BATT_modPchgChargeID_3 : 48|4@1+ (1,0) [0|15] "" Host,Battery
 SG_ BATT_resMod_3 : 32|16@1+ (0.01,0) [0|655.35] "mOhms" Host
 SG_ BATT_voirMod_3 : 16|16@1+ (0.01,0) [0|70] "V" Host
 SG_ BATT_vModLoad_3 : 0|16@1+ (0.01,0) [0|70] "V" Battery,Host

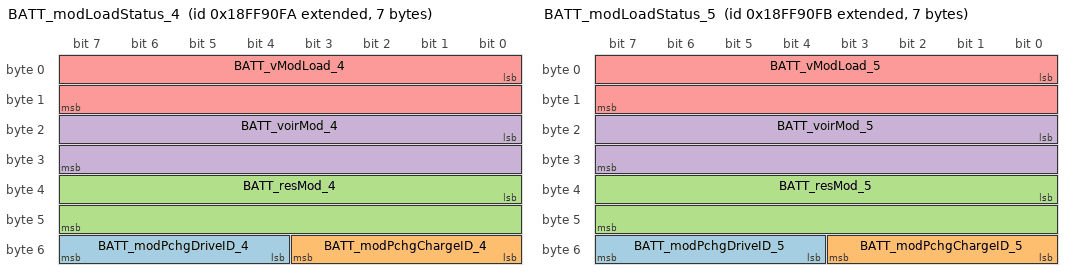
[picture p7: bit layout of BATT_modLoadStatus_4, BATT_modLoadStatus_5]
BO_ 2566885626 BATT_modLoadStatus_4: 7 Battery
 SG_ BATT_modPchgDriveID_4 : 52|4@1+ (1,0) [0|15] "" Host,Battery
 SG_ BATT_modPchgChargeID_4 : 48|4@1+ (1,0) [0|15] "" Host,Battery
 SG_ BATT_resMod_4 : 32|16@1+ (0.01,0) [0|655.35] "mOhms" Host
 SG_ BATT_voirMod_4 : 16|16@1+ (0.01,0) [0|70] "V" Host
 SG_ BATT_vModLoad_4 : 0|16@1+ (0.01,0) [0|70] "V" Battery,Host

BO_ 2566885627 BATT_modLoadStatus_5: 7 Battery
 SG_ BATT_modPchgDriveID_5 : 52|4@1+ (1,0) [0|15] "" Host,Battery
 SG_ BATT_modPchgChargeID_5 : 48|4@1+ (1,0) [0|15] "" Host,Battery
 SG_ BATT_resMod_5 : 32|16@1+ (0.01,0) [0|655.35] "mOhms" Host
 SG_ BATT_voirMod_5 : 16|16@1+ (0.01,0) [0|70] "V" Host
 SG_ BATT_vModLoad_5 : 0|16@1+ (0.01,0) [0|70] "V" Battery,Host

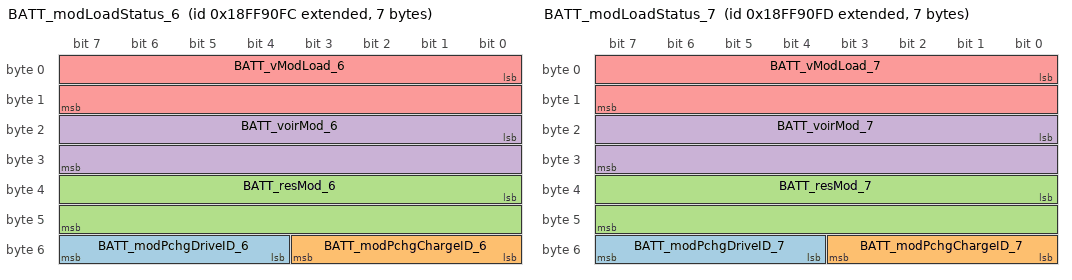
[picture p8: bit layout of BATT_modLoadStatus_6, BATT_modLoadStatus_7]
BO_ 2566885628 BATT_modLoadStatus_6: 7 Battery
 SG_ BATT_modPchgDriveID_6 : 52|4@1+ (1,0) [0|15] "" Host,Battery
 SG_ BATT_modPchgChargeID_6 : 48|4@1+ (1,0) [0|15] "" Host,Battery
 SG_ BATT_resMod_6 : 32|16@1+ (0.01,0) [0|655.35] "mOhms" Host
 SG_ BATT_voirMod_6 : 16|16@1+ (0.01,0) [0|70] "V" Host
 SG_ BATT_vModLoad_6 : 0|16@1+ (0.01,0) [0|70] "V" Battery,Host

BO_ 2566885629 BATT_modLoadStatus_7: 7 Battery
 SG_ BATT_modPchgDriveID_7 : 52|4@1+ (1,0) [0|15] "" Host,Battery
 SG_ BATT_modPchgChargeID_7 : 48|4@1+ (1,0) [0|15] "" Host,Battery
 SG_ BATT_resMod_7 : 32|16@1+ (0.01,0) [0|655.35] "mOhms" Host
 SG_ BATT_voirMod_7 : 16|16@1+ (0.01,0) [0|70] "V" Host
 SG_ BATT_vModLoad_7 : 0|16@1+ (0.01,0) [0|70] "V" Battery,Host

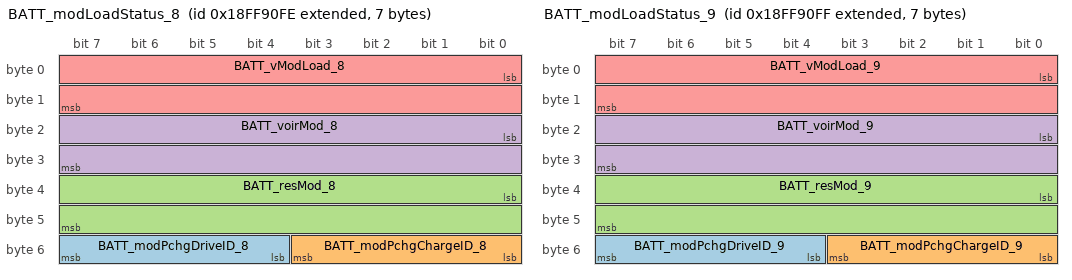
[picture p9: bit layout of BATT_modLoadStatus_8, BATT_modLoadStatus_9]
BO_ 2566885630 BATT_modLoadStatus_8: 7 Battery
 SG_ BATT_modPchgDriveID_8 : 52|4@1+ (1,0) [0|15] "" Host,Battery
 SG_ BATT_modPchgChargeID_8 : 48|4@1+ (1,0) [0|15] "" Host,Battery
 SG_ BATT_resMod_8 : 32|16@1+ (0.01,0) [0|655.35] "mOhms" Host
 SG_ BATT_voirMod_8 : 16|16@1+ (0.01,0) [0|70] "V" Host
 SG_ BATT_vModLoad_8 : 0|16@1+ (0.01,0) [0|70] "V" Battery,Host

BO_ 2566885631 BATT_modLoadStatus_9: 7 Battery
 SG_ BATT_modPchgDriveID_9 : 52|4@1+ (1,0) [0|15] "" Host,Battery
 SG_ BATT_modPchgChargeID_9 : 48|4@1+ (1,0) [0|15] "" Host,Battery
 SG_ BATT_resMod_9 : 32|16@1+ (0.01,0) [0|655.35] "mOhms" Host
 SG_ BATT_voirMod_9 : 16|16@1+ (0.01,0) [0|70] "V" Host
 SG_ BATT_vModLoad_9 : 0|16@1+ (0.01,0) [0|70] "V" Battery,Host

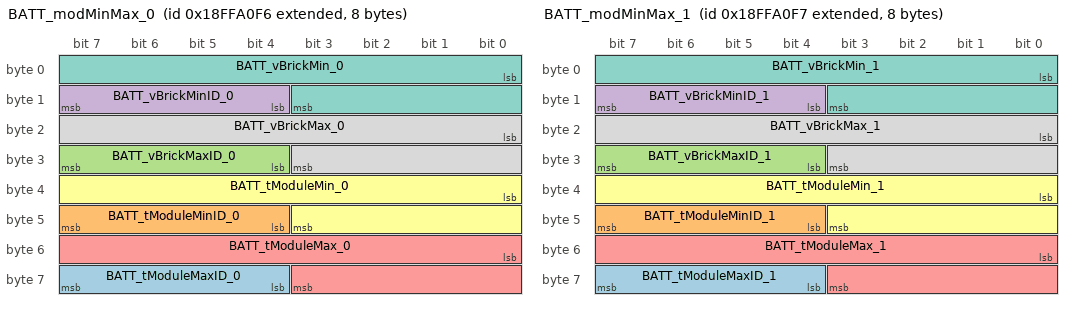
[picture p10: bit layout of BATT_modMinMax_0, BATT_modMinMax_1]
BO_ 2566889718 BATT_modMinMax_0: 8 Battery
 SG_ BATT_tModuleMaxID_0 : 60|4@1+ (1,0) [0|14] "" Battery,Host
 SG_ BATT_tModuleMinID_0 : 44|4@1+ (1,0) [0|14] "" Battery,Host
 SG_ BATT_vBrickMaxID_0 : 28|4@1+ (1,0) [0|14] "" Battery,Host
 SG_ BATT_vBrickMinID_0 : 12|4@1+ (1,0) [0|14] "" Battery,Host
 SG_ BATT_tModuleMax_0 : 48|12@1- (0.1,0) [-40|125] "deg C" Battery,Host
 SG_ BATT_tModuleMin_0 : 32|12@1- (0.1,0) [-40|125] "deg C" Battery,Host
 SG_ BATT_vBrickMin_0 : 0|12@1+ (0.002,0) [0|4.98066] "V" Battery,Host
 SG_ BATT_vBrickMax_0 : 16|12@1+ (0.002,0) [0|4.98066] "V" Battery,Host

BO_ 2566889719 BATT_modMinMax_1: 8 Battery
 SG_ BATT_tModuleMaxID_1 : 60|4@1+ (1,0) [0|14] "" Battery,Host
 SG_ BATT_tModuleMinID_1 : 44|4@1+ (1,0) [0|14] "" Battery,Host
 SG_ BATT_vBrickMaxID_1 : 28|4@1+ (1,0) [0|14] "" Battery,Host
 SG_ BATT_vBrickMinID_1 : 12|4@1+ (1,0) [0|14] "" Battery,Host
 SG_ BATT_tModuleMax_1 : 48|12@1- (0.1,0) [-40|125] "deg C" Battery,Host
 SG_ BATT_tModuleMin_1 : 32|12@1- (0.1,0) [-40|125] "deg C" Battery,Host
 SG_ BATT_vBrickMin_1 : 0|12@1+ (0.002,0) [0|4.98066] "V" Battery,Host
 SG_ BATT_vBrickMax_1 : 16|12@1+ (0.002,0) [0|4.98066] "V" Battery,Host

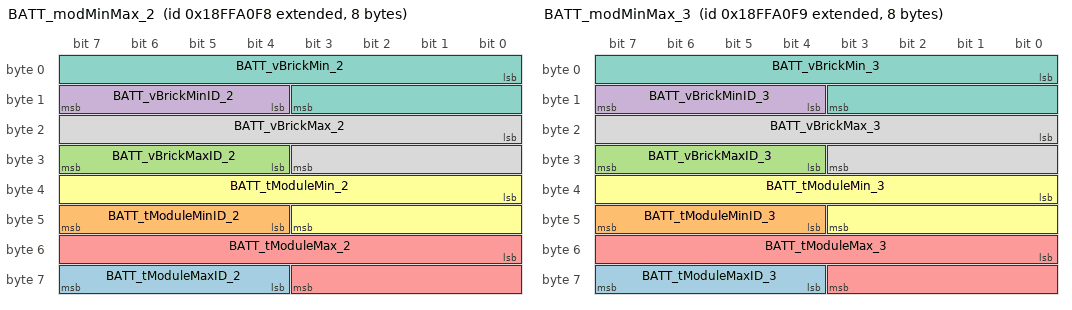
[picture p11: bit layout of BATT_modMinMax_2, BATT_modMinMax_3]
BO_ 2566889720 BATT_modMinMax_2: 8 Battery
 SG_ BATT_tModuleMaxID_2 : 60|4@1+ (1,0) [0|14] "" Battery,Host
 SG_ BATT_tModuleMinID_2 : 44|4@1+ (1,0) [0|14] "" Battery,Host
 SG_ BATT_vBrickMaxID_2 : 28|4@1+ (1,0) [0|14] "" Battery,Host
 SG_ BATT_vBrickMinID_2 : 12|4@1+ (1,0) [0|14] "" Battery,Host
 SG_ BATT_tModuleMax_2 : 48|12@1- (0.1,0) [-40|125] "deg C" Battery,Host
 SG_ BATT_tModuleMin_2 : 32|12@1- (0.1,0) [-40|125] "deg C" Battery,Host
 SG_ BATT_vBrickMin_2 : 0|12@1+ (0.002,0) [0|4.98066] "V" Battery,Host
 SG_ BATT_vBrickMax_2 : 16|12@1+ (0.002,0) [0|4.98066] "V" Battery,Host

BO_ 2566889721 BATT_modMinMax_3: 8 Battery
 SG_ BATT_tModuleMaxID_3 : 60|4@1+ (1,0) [0|14] "" Battery,Host
 SG_ BATT_tModuleMinID_3 : 44|4@1+ (1,0) [0|14] "" Battery,Host
 SG_ BATT_vBrickMaxID_3 : 28|4@1+ (1,0) [0|14] "" Battery,Host
 SG_ BATT_vBrickMinID_3 : 12|4@1+ (1,0) [0|14] "" Battery,Host
 SG_ BATT_tModuleMax_3 : 48|12@1- (0.1,0) [-40|125] "deg C" Battery,Host
 SG_ BATT_tModuleMin_3 : 32|12@1- (0.1,0) [-40|125] "deg C" Battery,Host
 SG_ BATT_vBrickMin_3 : 0|12@1+ (0.002,0) [0|4.98066] "V" Battery,Host
 SG_ BATT_vBrickMax_3 : 16|12@1+ (0.002,0) [0|4.98066] "V" Battery,Host

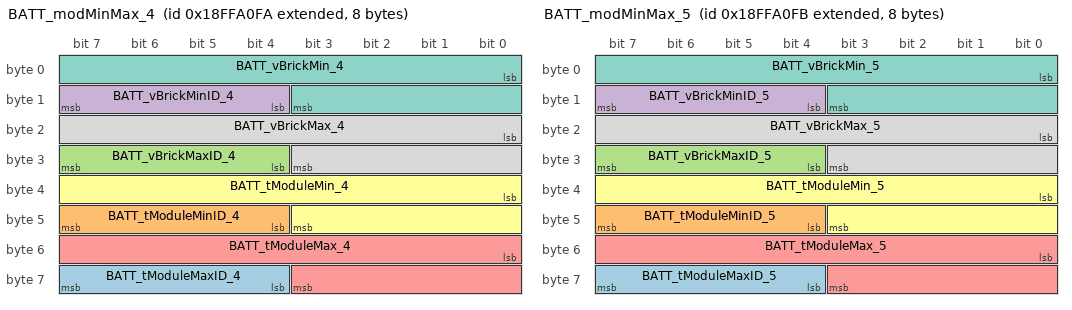
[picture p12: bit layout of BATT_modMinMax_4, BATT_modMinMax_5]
BO_ 2566889722 BATT_modMinMax_4: 8 Battery
 SG_ BATT_tModuleMaxID_4 : 60|4@1+ (1,0) [0|14] "" Battery,Host
 SG_ BATT_tModuleMinID_4 : 44|4@1+ (1,0) [0|14] "" Battery,Host
 SG_ BATT_vBrickMaxID_4 : 28|4@1+ (1,0) [0|14] "" Battery,Host
 SG_ BATT_vBrickMinID_4 : 12|4@1+ (1,0) [0|14] "" Battery,Host
 SG_ BATT_tModuleMax_4 : 48|12@1- (0.1,0) [-40|125] "deg C" Battery,Host
 SG_ BATT_tModuleMin_4 : 32|12@1- (0.1,0) [-40|125] "deg C" Battery,Host
 SG_ BATT_vBrickMin_4 : 0|12@1+ (0.002,0) [0|4.98066] "V" Battery,Host
 SG_ BATT_vBrickMax_4 : 16|12@1+ (0.002,0) [0|4.98066] "V" Battery,Host

BO_ 2566889723 BATT_modMinMax_5: 8 Battery
 SG_ BATT_tModuleMaxID_5 : 60|4@1+ (1,0) [0|14] "" Battery,Host
 SG_ BATT_tModuleMinID_5 : 44|4@1+ (1,0) [0|14] "" Battery,Host
 SG_ BATT_vBrickMaxID_5 : 28|4@1+ (1,0) [0|14] "" Battery,Host
 SG_ BATT_vBrickMinID_5 : 12|4@1+ (1,0) [0|14] "" Battery,Host
 SG_ BATT_tModuleMax_5 : 48|12@1- (0.1,0) [-40|125] "deg C" Battery,Host
 SG_ BATT_tModuleMin_5 : 32|12@1- (0.1,0) [-40|125] "deg C" Battery,Host
 SG_ BATT_vBrickMin_5 : 0|12@1+ (0.002,0) [0|4.98066] "V" Battery,Host
 SG_ BATT_vBrickMax_5 : 16|12@1+ (0.002,0) [0|4.98066] "V" Battery,Host

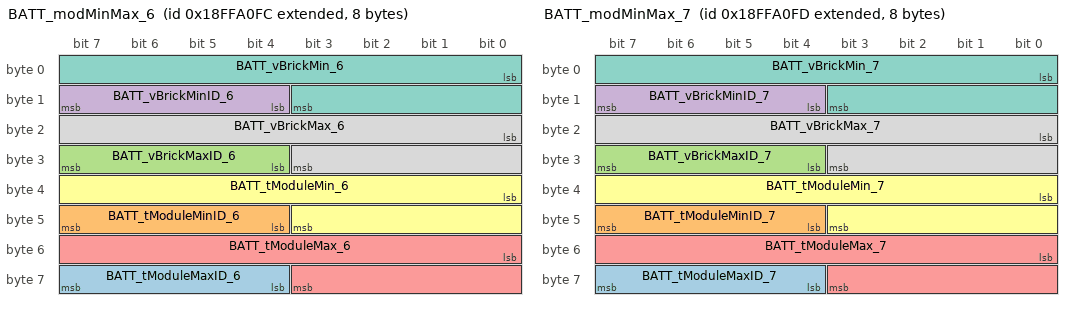
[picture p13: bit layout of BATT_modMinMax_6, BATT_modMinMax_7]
BO_ 2566889724 BATT_modMinMax_6: 8 Battery
 SG_ BATT_tModuleMaxID_6 : 60|4@1+ (1,0) [0|14] "" Battery,Host
 SG_ BATT_tModuleMinID_6 : 44|4@1+ (1,0) [0|14] "" Battery,Host
 SG_ BATT_vBrickMaxID_6 : 28|4@1+ (1,0) [0|14] "" Battery,Host
 SG_ BATT_vBrickMinID_6 : 12|4@1+ (1,0) [0|14] "" Battery,Host
 SG_ BATT_tModuleMax_6 : 48|12@1- (0.1,0) [-40|125] "deg C" Battery,Host
 SG_ BATT_tModuleMin_6 : 32|12@1- (0.1,0) [-40|125] "deg C" Battery,Host
 SG_ BATT_vBrickMin_6 : 0|12@1+ (0.002,0) [0|4.98066] "V" Battery,Host
 SG_ BATT_vBrickMax_6 : 16|12@1+ (0.002,0) [0|4.98066] "V" Battery,Host

BO_ 2566889725 BATT_modMinMax_7: 8 Battery
 SG_ BATT_tModuleMaxID_7 : 60|4@1+ (1,0) [0|14] "" Battery,Host
 SG_ BATT_tModuleMinID_7 : 44|4@1+ (1,0) [0|14] "" Battery,Host
 SG_ BATT_vBrickMaxID_7 : 28|4@1+ (1,0) [0|14] "" Battery,Host
 SG_ BATT_vBrickMinID_7 : 12|4@1+ (1,0) [0|14] "" Battery,Host
 SG_ BATT_tModuleMax_7 : 48|12@1- (0.1,0) [-40|125] "deg C" Battery,Host
 SG_ BATT_tModuleMin_7 : 32|12@1- (0.1,0) [-40|125] "deg C" Battery,Host
 SG_ BATT_vBrickMin_7 : 0|12@1+ (0.002,0) [0|4.98066] "V" Battery,Host
 SG_ BATT_vBrickMax_7 : 16|12@1+ (0.002,0) [0|4.98066] "V" Battery,Host

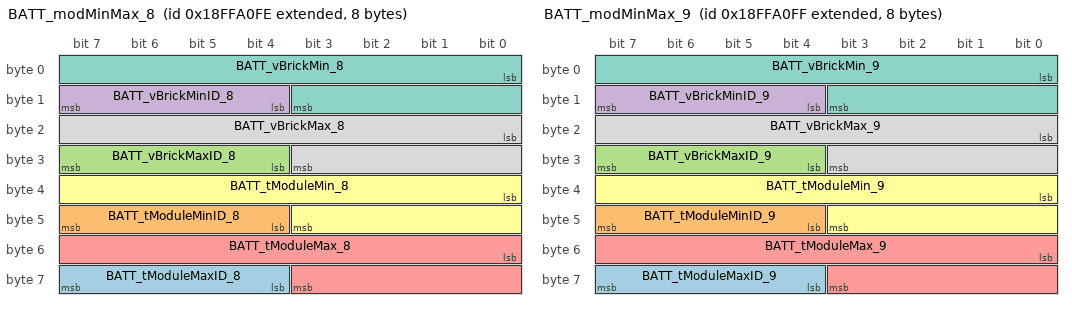
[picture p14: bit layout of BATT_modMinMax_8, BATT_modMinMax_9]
BO_ 2566889726 BATT_modMinMax_8: 8 Battery
 SG_ BATT_tModuleMaxID_8 : 60|4@1+ (1,0) [0|14] "" Battery,Host
 SG_ BATT_tModuleMinID_8 : 44|4@1+ (1,0) [0|14] "" Battery,Host
 SG_ BATT_vBrickMaxID_8 : 28|4@1+ (1,0) [0|14] "" Battery,Host
 SG_ BATT_vBrickMinID_8 : 12|4@1+ (1,0) [0|14] "" Battery,Host
 SG_ BATT_tModuleMax_8 : 48|12@1- (0.1,0) [-40|125] "deg C" Battery,Host
 SG_ BATT_tModuleMin_8 : 32|12@1- (0.1,0) [-40|125] "deg C" Battery,Host
 SG_ BATT_vBrickMin_8 : 0|12@1+ (0.002,0) [0|4.98066] "V" Battery,Host
 SG_ BATT_vBrickMax_8 : 16|12@1+ (0.002,0) [0|4.98066] "V" Battery,Host

BO_ 2566889727 BATT_modMinMax_9: 8 Battery
 SG_ BATT_tModuleMaxID_9 : 60|4@1+ (1,0) [0|14] "" Battery,Host
 SG_ BATT_tModuleMinID_9 : 44|4@1+ (1,0) [0|14] "" Battery,Host
 SG_ BATT_vBrickMaxID_9 : 28|4@1+ (1,0) [0|14] "" Battery,Host
 SG_ BATT_vBrickMinID_9 : 12|4@1+ (1,0) [0|14] "" Battery,Host
 SG_ BATT_tModuleMax_9 : 48|12@1- (0.1,0) [-40|125] "deg C" Battery,Host
 SG_ BATT_tModuleMin_9 : 32|12@1- (0.1,0) [-40|125] "deg C" Battery,Host
 SG_ BATT_vBrickMin_9 : 0|12@1+ (0.002,0) [0|4.98066] "V" Battery,Host
 SG_ BATT_vBrickMax_9 : 16|12@1+ (0.002,0) [0|4.98066] "V" Battery,Host

BO_ 2566893814 BATT_modPwrAvailable_0: 4 Battery
 SG_ BATT_pwrModDchLimit_0 : 16|16@1+ (0.01,0) [0|655.35] "kW" Host,Battery
 SG_ BATT_pwrModChgLimit_0 : 0|16@1+ (0.01,0) [0|655.35] "kW" Host,Battery

BO_ 2566893815 BATT_modPwrAvailable_1: 4 Battery
 SG_ BATT_pwrModDchLimit_1 : 16|16@1+ (0.01,0) [0|655.35] "kW" Host,Battery
 SG_ BATT_pwrModChgLimit_1 : 0|16@1+ (0.01,0) [0|655.35] "kW" Host,Battery

BO_ 2566893816 BATT_modPwrAvailable_2: 4 Battery
 SG_ BATT_pwrModDchLimit_2 : 16|16@1+ (0.01,0) [0|655.35] "kW" Host,Battery
 SG_ BATT_pwrModChgLimit_2 : 0|16@1+ (0.01,0) [0|655.35] "kW" Host,Battery

BO_ 2566893817 BATT_modPwrAvailable_3: 4 Battery
 SG_ BATT_pwrModDchLimit_3 : 16|16@1+ (0.01,0) [0|655.35] "kW" Host,Battery
 SG_ BATT_pwrModChgLimit_3 : 0|16@1+ (0.01,0) [0|655.35] "kW" Host,Battery

BO_ 2566893818 BATT_modPwrAvailable_4: 4 Battery
 SG_ BATT_pwrModDchLimit_4 : 16|16@1+ (0.01,0) [0|655.35] "kW" Host,Battery
 SG_ BATT_pwrModChgLimit_4 : 0|16@1+ (0.01,0) [0|655.35] "kW" Host,Battery

BO_ 2566893819 BATT_modPwrAvailable_5: 4 Battery
 SG_ BATT_pwrModDchLimit_5 : 16|16@1+ (0.01,0) [0|655.35] "kW" Host,Battery
 SG_ BATT_pwrModChgLimit_5 : 0|16@1+ (0.01,0) [0|655.35] "kW" Host,Battery

BO_ 2566893820 BATT_modPwrAvailable_6: 4 Battery
 SG_ BATT_pwrModDchLimit_6 : 16|16@1+ (0.01,0) [0|655.35] "kW" Host,Battery
 SG_ BATT_pwrModChgLimit_6 : 0|16@1+ (0.01,0) [0|655.35] "kW" Host,Battery

BO_ 2566893821 BATT_modPwrAvailable_7: 4 Battery
 SG_ BATT_pwrModDchLimit_7 : 16|16@1+ (0.01,0) [0|655.35] "kW" Host,Battery
 SG_ BATT_pwrModChgLimit_7 : 0|16@1+ (0.01,0) [0|655.35] "kW" Host,Battery

BO_ 2566893822 BATT_modPwrAvailable_8: 4 Battery
 SG_ BATT_pwrModDchLimit_8 : 16|16@1+ (0.01,0) [0|655.35] "kW" Host,Battery
 SG_ BATT_pwrModChgLimit_8 : 0|16@1+ (0.01,0) [0|655.35] "kW" Host,Battery

BO_ 2566893823 BATT_modPwrAvailable_9: 4 Battery
 SG_ BATT_pwrModDchLimit_9 : 16|16@1+ (0.01,0) [0|655.35] "kW" Host,Battery
 SG_ BATT_pwrModChgLimit_9 : 0|16@1+ (0.01,0) [0|655.35] "kW" Host,Battery

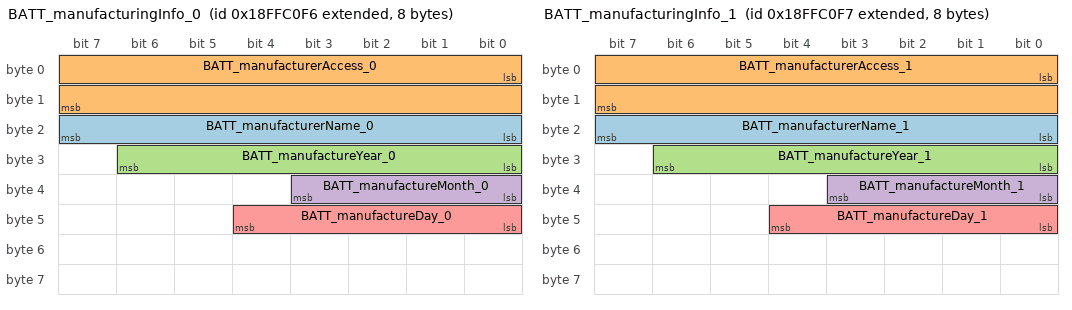
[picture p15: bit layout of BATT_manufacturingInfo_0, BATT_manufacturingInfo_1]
BO_ 2566897910 BATT_manufacturingInfo_0: 8 Battery
 SG_ BATT_manufacturerName_0 : 16|8@1+ (1,0) [0|255] "STRING" Host
 SG_ BATT_manufacturerAccess_0 : 0|16@1+ (1,0) [0|65535] "" Host
 SG_ BATT_manufactureYear_0 : 24|7@1+ (1,0) [0|127] "" Host
 SG_ BATT_manufactureMonth_0 : 32|4@1+ (1,0) [1|12] "" Host
 SG_ BATT_manufactureDay_0 : 40|5@1+ (1,0) [1|31] "" Host

BO_ 2566897911 BATT_manufacturingInfo_1: 8 Battery
 SG_ BATT_manufacturerName_1 : 16|8@1+ (1,0) [0|255] "STRING" Host
 SG_ BATT_manufacturerAccess_1 : 0|16@1+ (1,0) [0|65535] "" Host
 SG_ BATT_manufactureYear_1 : 24|7@1+ (1,0) [0|127] "" Host
 SG_ BATT_manufactureMonth_1 : 32|4@1+ (1,0) [1|12] "" Host
 SG_ BATT_manufactureDay_1 : 40|5@1+ (1,0) [1|31] "" Host

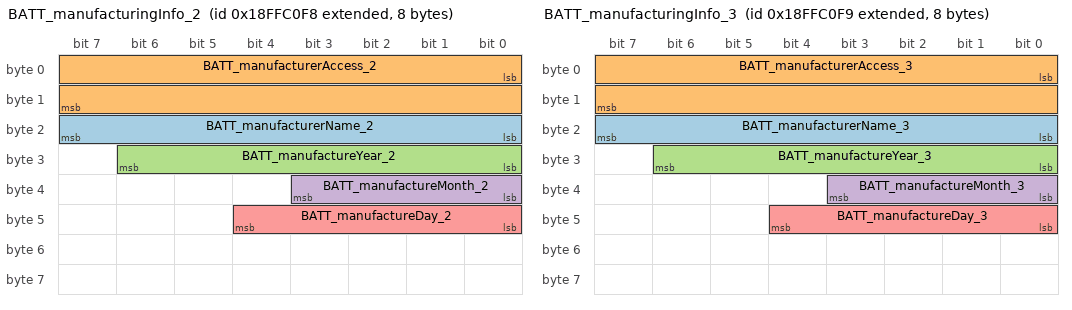
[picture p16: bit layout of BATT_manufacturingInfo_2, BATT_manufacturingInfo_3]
BO_ 2566897912 BATT_manufacturingInfo_2: 8 Battery
 SG_ BATT_manufacturerName_2 : 16|8@1+ (1,0) [0|255] "STRING" Host
 SG_ BATT_manufacturerAccess_2 : 0|16@1+ (1,0) [0|65535] "" Host
 SG_ BATT_manufactureYear_2 : 24|7@1+ (1,0) [0|127] "" Host
 SG_ BATT_manufactureMonth_2 : 32|4@1+ (1,0) [1|12] "" Host
 SG_ BATT_manufactureDay_2 : 40|5@1+ (1,0) [1|31] "" Host

BO_ 2566897913 BATT_manufacturingInfo_3: 8 Battery
 SG_ BATT_manufacturerName_3 : 16|8@1+ (1,0) [0|255] "STRING" Host
 SG_ BATT_manufacturerAccess_3 : 0|16@1+ (1,0) [0|65535] "" Host
 SG_ BATT_manufactureYear_3 : 24|7@1+ (1,0) [0|127] "" Host
 SG_ BATT_manufactureMonth_3 : 32|4@1+ (1,0) [1|12] "" Host
 SG_ BATT_manufactureDay_3 : 40|5@1+ (1,0) [1|31] "" Host

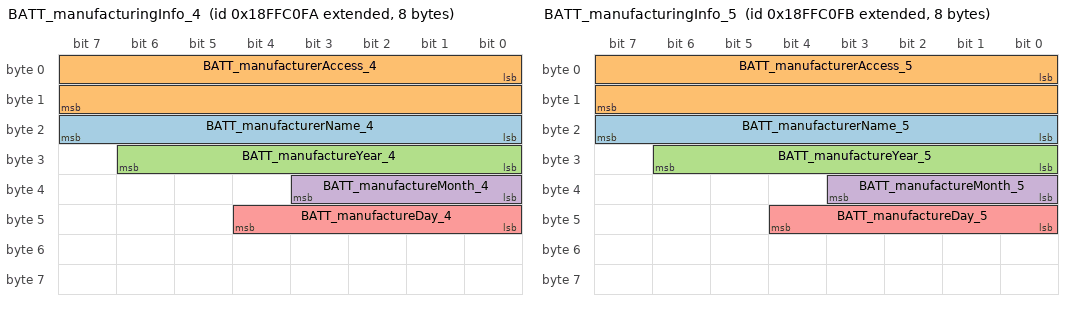
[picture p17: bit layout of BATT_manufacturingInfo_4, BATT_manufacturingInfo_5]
BO_ 2566897914 BATT_manufacturingInfo_4: 8 Battery
 SG_ BATT_manufacturerName_4 : 16|8@1+ (1,0) [0|255] "STRING" Host
 SG_ BATT_manufacturerAccess_4 : 0|16@1+ (1,0) [0|65535] "" Host
 SG_ BATT_manufactureYear_4 : 24|7@1+ (1,0) [0|127] "" Host
 SG_ BATT_manufactureMonth_4 : 32|4@1+ (1,0) [1|12] "" Host
 SG_ BATT_manufactureDay_4 : 40|5@1+ (1,0) [1|31] "" Host

BO_ 2566897915 BATT_manufacturingInfo_5: 8 Battery
 SG_ BATT_manufacturerName_5 : 16|8@1+ (1,0) [0|255] "STRING" Host
 SG_ BATT_manufacturerAccess_5 : 0|16@1+ (1,0) [0|65535] "" Host
 SG_ BATT_manufactureYear_5 : 24|7@1+ (1,0) [0|127] "" Host
 SG_ BATT_manufactureMonth_5 : 32|4@1+ (1,0) [1|12] "" Host
 SG_ BATT_manufactureDay_5 : 40|5@1+ (1,0) [1|31] "" Host

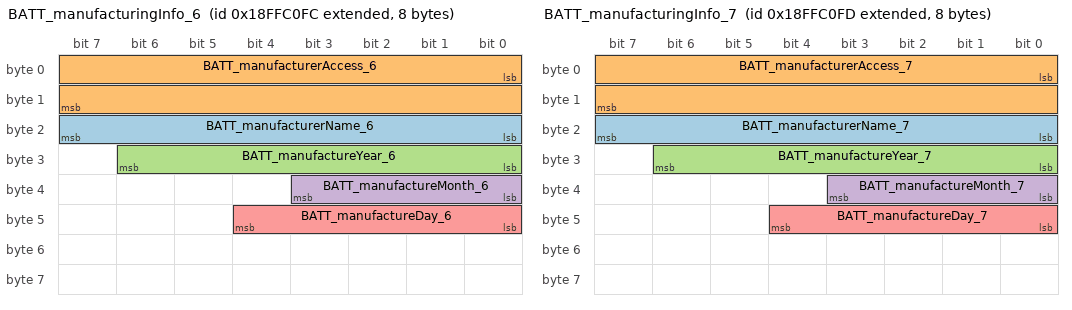
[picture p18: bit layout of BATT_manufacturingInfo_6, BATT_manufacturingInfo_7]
BO_ 2566897916 BATT_manufacturingInfo_6: 8 Battery
 SG_ BATT_manufacturerName_6 : 16|8@1+ (1,0) [0|255] "STRING" Host
 SG_ BATT_manufacturerAccess_6 : 0|16@1+ (1,0) [0|65535] "" Host
 SG_ BATT_manufactureYear_6 : 24|7@1+ (1,0) [0|127] "" Host
 SG_ BATT_manufactureMonth_6 : 32|4@1+ (1,0) [1|12] "" Host
 SG_ BATT_manufactureDay_6 : 40|5@1+ (1,0) [1|31] "" Host

BO_ 2566897917 BATT_manufacturingInfo_7: 8 Battery
 SG_ BATT_manufacturerName_7 : 16|8@1+ (1,0) [0|255] "STRING" Host
 SG_ BATT_manufacturerAccess_7 : 0|16@1+ (1,0) [0|65535] "" Host
 SG_ BATT_manufactureYear_7 : 24|7@1+ (1,0) [0|127] "" Host
 SG_ BATT_manufactureMonth_7 : 32|4@1+ (1,0) [1|12] "" Host
 SG_ BATT_manufactureDay_7 : 40|5@1+ (1,0) [1|31] "" Host

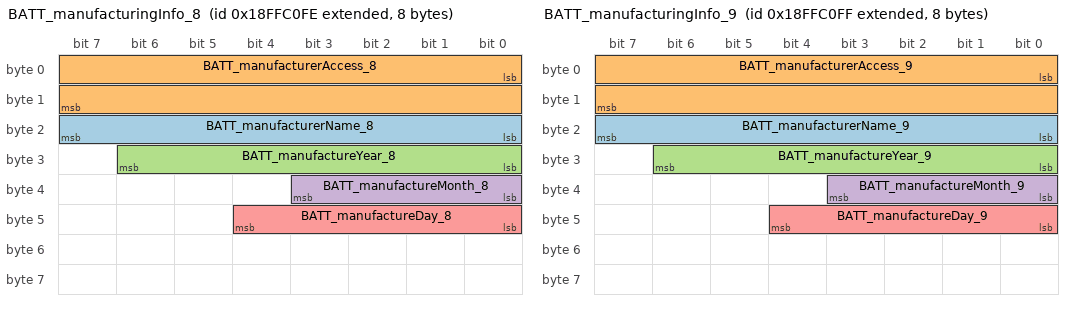
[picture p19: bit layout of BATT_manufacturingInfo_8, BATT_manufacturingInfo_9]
BO_ 2566897918 BATT_manufacturingInfo_8: 8 Battery
 SG_ BATT_manufacturerName_8 : 16|8@1+ (1,0) [0|255] "STRING" Host
 SG_ BATT_manufacturerAccess_8 : 0|16@1+ (1,0) [0|65535] "" Host
 SG_ BATT_manufactureYear_8 : 24|7@1+ (1,0) [0|127] "" Host
 SG_ BATT_manufactureMonth_8 : 32|4@1+ (1,0) [1|12] "" Host
 SG_ BATT_manufactureDay_8 : 40|5@1+ (1,0) [1|31] "" Host

BO_ 2566897919 BATT_manufacturingInfo_9: 8 Battery
 SG_ BATT_manufacturerName_9 : 16|8@1+ (1,0) [0|255] "STRING" Host
 SG_ BATT_manufacturerAccess_9 : 0|16@1+ (1,0) [0|65535] "" Host
 SG_ BATT_manufactureYear_9 : 24|7@1+ (1,0) [0|127] "" Host
 SG_ BATT_manufactureMonth_9 : 32|4@1+ (1,0) [1|12] "" Host
 SG_ BATT_manufactureDay_9 : 40|5@1+ (1,0) [1|31] "" Host

BO_ 2566902006 BATT_modCapacity_0: 8 Battery
 SG_ BATT_modFullChargeCap_Ah_0 : 16|16@1+ (0.005,0) [0|327.675] "Ah" Battery,Host
 SG_ BATT_modRemainingCap_Ah_0 : 0|16@1+ (0.005,0) [0|327.675] "Ah" Battery,Host

BO_ 2566902007 BATT_modCapacity_1: 8 Battery
 SG_ BATT_modFullChargeCap_Ah_1 : 16|16@1+ (0.005,0) [0|327.675] "Ah" Battery,Host
 SG_ BATT_modRemainingCap_Ah_1 : 0|16@1+ (0.005,0) [0|327.675] "Ah" Battery,Host

BO_ 2566902008 BATT_modCapacity_2: 8 Battery
 SG_ BATT_modFullChargeCap_Ah_2 : 16|16@1+ (0.005,0) [0|327.675] "Ah" Battery,Host
 SG_ BATT_modRemainingCap_Ah_2 : 0|16@1+ (0.005,0) [0|327.675] "Ah" Battery,Host

BO_ 2566902009 BATT_modCapacity_3: 8 Battery
 SG_ BATT_modFullChargeCap_Ah_3 : 16|16@1+ (0.005,0) [0|327.675] "Ah" Battery,Host
 SG_ BATT_modRemainingCap_Ah_3 : 0|16@1+ (0.005,0) [0|327.675] "Ah" Battery,Host

BO_ 2566902010 BATT_modCapacity_4: 8 Battery
 SG_ BATT_modFullChargeCap_Ah_4 : 16|16@1+ (0.005,0) [0|327.675] "Ah" Battery,Host
 SG_ BATT_modRemainingCap_Ah_4 : 0|16@1+ (0.005,0) [0|327.675] "Ah" Battery,Host

BO_ 2566902011 BATT_modCapacity_5: 8 Battery
 SG_ BATT_modFullChargeCap_Ah_5 : 16|16@1+ (0.005,0) [0|327.675] "Ah" Battery,Host
 SG_ BATT_modRemainingCap_Ah_5 : 0|16@1+ (0.005,0) [0|327.675] "Ah" Battery,Host

BO_ 2566902012 BATT_modCapacity_6: 8 Battery
 SG_ BATT_modFullChargeCap_Ah_6 : 16|16@1+ (0.005,0) [0|327.675] "Ah" Battery,Host
 SG_ BATT_modRemainingCap_Ah_6 : 0|16@1+ (0.005,0) [0|327.675] "Ah" Battery,Host

BO_ 2566902013 BATT_modCapacity_7: 8 Battery
 SG_ BATT_modFullChargeCap_Ah_7 : 16|16@1+ (0.005,0) [0|327.675] "Ah" Battery,Host
 SG_ BATT_modRemainingCap_Ah_7 : 0|16@1+ (0.005,0) [0|327.675] "Ah" Battery,Host

BO_ 2566902014 BATT_modCapacity_8: 8 Battery
 SG_ BATT_modFullChargeCap_Ah_8 : 16|16@1+ (0.005,0) [0|327.675] "Ah" Battery,Host
 SG_ BATT_modRemainingCap_Ah_8 : 0|16@1+ (0.005,0) [0|327.675] "Ah" Battery,Host

BO_ 2566902015 BATT_modCapacity_9: 8 Battery
 SG_ BATT_modFullChargeCap_Ah_9 : 16|16@1+ (0.005,0) [0|327.675] "Ah" Battery,Host
 SG_ BATT_modRemainingCap_Ah_9 : 0|16@1+ (0.005,0) [0|327.675] "Ah" Battery,Host

BO_ 2566906102 BATT_modChgLimits_0: 8 Battery
 SG_ BATT_vModChgLimit_0 : 48|16@1+ (0.005,0) [0|70] "V" Host,Battery
 SG_ BATT_iModChgLimit30s_0 : 32|16@1+ (0.02,0) [0|1310.7] "A" Host,Battery
 SG_ BATT_iModChgLimit10s_0 : 0|16@1+ (0.02,0) [0|1310.7] "A" Host,Battery
 SG_ BATT_iModChgLimitCont_0 : 16|16@1+ (0.02,0) [0|1310.7] "A" Battery,Host

BO_ 2566906103 BATT_modChgLimits_1: 8 Battery
 SG_ BATT_vModChgLimit_1 : 48|16@1+ (0.005,0) [0|70] "V" Host,Battery
 SG_ BATT_iModChgLimit30s_1 : 32|16@1+ (0.02,0) [0|1310.7] "A" Host,Battery
 SG_ BATT_iModChgLimit10s_1 : 0|16@1+ (0.02,0) [0|1310.7] "A" Host,Battery
 SG_ BATT_iModChgLimitCont_1 : 16|16@1+ (0.02,0) [0|1310.7] "A" Battery,Host

BO_ 2566906104 BATT_modChgLimits_2: 8 Battery
 SG_ BATT_vModChgLimit_2 : 48|16@1+ (0.005,0) [0|70] "V" Host,Battery
 SG_ BATT_iModChgLimit30s_2 : 32|16@1+ (0.02,0) [0|1310.7] "A" Host,Battery
 SG_ BATT_iModChgLimit10s_2 : 0|16@1+ (0.02,0) [0|1310.7] "A" Host,Battery
 SG_ BATT_iModChgLimitCont_2 : 16|16@1+ (0.02,0) [0|1310.7] "A" Battery,Host

BO_ 2566906105 BATT_modChgLimits_3: 8 Battery
 SG_ BATT_vModChgLimit_3 : 48|16@1+ (0.005,0) [0|70] "V" Host,Battery
 SG_ BATT_iModChgLimit30s_3 : 32|16@1+ (0.02,0) [0|1310.7] "A" Host,Battery
 SG_ BATT_iModChgLimit10s_3 : 0|16@1+ (0.02,0) [0|1310.7] "A" Host,Battery
 SG_ BATT_iModChgLimitCont_3 : 16|16@1+ (0.02,0) [0|1310.7] "A" Battery,Host

BO_ 2566906106 BATT_modChgLimits_4: 8 Battery
 SG_ BATT_vModChgLimit_4 : 48|16@1+ (0.005,0) [0|70] "V" Host,Battery
 SG_ BATT_iModChgLimit30s_4 : 32|16@1+ (0.02,0) [0|1310.7] "A" Host,Battery
 SG_ BATT_iModChgLimit10s_4 : 0|16@1+ (0.02,0) [0|1310.7] "A" Host,Battery
 SG_ BATT_iModChgLimitCont_4 : 16|16@1+ (0.02,0) [0|1310.7] "A" Battery,Host

BO_ 2566906107 BATT_modChgLimits_5: 8 Battery
 SG_ BATT_vModChgLimit_5 : 48|16@1+ (0.005,0) [0|70] "V" Host,Battery
 SG_ BATT_iModChgLimit30s_5 : 32|16@1+ (0.02,0) [0|1310.7] "A" Host,Battery
 SG_ BATT_iModChgLimit10s_5 : 0|16@1+ (0.02,0) [0|1310.7] "A" Host,Battery
 SG_ BATT_iModChgLimitCont_5 : 16|16@1+ (0.02,0) [0|1310.7] "A" Battery,Host

BO_ 2566906108 BATT_modChgLimits_6: 8 Battery
 SG_ BATT_vModChgLimit_6 : 48|16@1+ (0.005,0) [0|70] "V" Host,Battery
 SG_ BATT_iModChgLimit30s_6 : 32|16@1+ (0.02,0) [0|1310.7] "A" Host,Battery
 SG_ BATT_iModChgLimit10s_6 : 0|16@1+ (0.02,0) [0|1310.7] "A" Host,Battery
 SG_ BATT_iModChgLimitCont_6 : 16|16@1+ (0.02,0) [0|1310.7] "A" Battery,Host

BO_ 2566906109 BATT_modChgLimits_7: 8 Battery
 SG_ BATT_vModChgLimit_7 : 48|16@1+ (0.005,0) [0|70] "V" Host,Battery
 SG_ BATT_iModChgLimit30s_7 : 32|16@1+ (0.02,0) [0|1310.7] "A" Host,Battery
 SG_ BATT_iModChgLimit10s_7 : 0|16@1+ (0.02,0) [0|1310.7] "A" Host,Battery
 SG_ BATT_iModChgLimitCont_7 : 16|16@1+ (0.02,0) [0|1310.7] "A" Battery,Host

BO_ 2566906110 BATT_modChgLimits_8: 8 Battery
 SG_ BATT_vModChgLimit_8 : 48|16@1+ (0.005,0) [0|70] "V" Host,Battery
 SG_ BATT_iModChgLimit30s_8 : 32|16@1+ (0.02,0) [0|1310.7] "A" Host,Battery
 SG_ BATT_iModChgLimit10s_8 : 0|16@1+ (0.02,0) [0|1310.7] "A" Host,Battery
 SG_ BATT_iModChgLimitCont_8 : 16|16@1+ (0.02,0) [0|1310.7] "A" Battery,Host

BO_ 2566906111 BATT_modChgLimits_9: 8 Battery
 SG_ BATT_vModChgLimit_9 : 48|16@1+ (0.005,0) [0|70] "V" Host,Battery
 SG_ BATT_iModChgLimit30s_9 : 32|16@1+ (0.02,0) [0|1310.7] "A" Host,Battery
 SG_ BATT_iModChgLimit10s_9 : 0|16@1+ (0.02,0) [0|1310.7] "A" Host,Battery
 SG_ BATT_iModChgLimitCont_9 : 16|16@1+ (0.02,0) [0|1310.7] "A" Battery,Host

CM_ BO_ 2566862841 "Voltages of bricks 13-14";
CM_ SG_ 2566862841 BATT_vBrick14_3 "Voltage of brick 14";
CM_ SG_ 2566862841 BATT_vBrick13_3 "Voltage of brick 13";
CM_ BO_ 2566862842 "Voltages of bricks 13-14";
CM_ SG_ 2566862842 BATT_vBrick14_4 "Voltage of brick 14";
CM_ SG_ 2566862842 BATT_vBrick13_4 "Voltage of brick 13";
CM_ BO_ 2566862843 "Voltages of bricks 13-14";
CM_ SG_ 2566862843 BATT_vBrick14_5 "Voltage of brick 14";
CM_ SG_ 2566862843 BATT_vBrick13_5 "Voltage of brick 13";
CM_ BO_ 2566862844 "Voltages of bricks 13-14";
CM_ SG_ 2566862844 BATT_vBrick14_6 "Voltage of brick 14";
CM_ SG_ 2566862844 BATT_vBrick13_6 "Voltage of brick 13";
CM_ BO_ 2566862845 "Voltages of bricks 13-14";
CM_ SG_ 2566862845 BATT_vBrick14_7 "Voltage of brick 14";
CM_ SG_ 2566862845 BATT_vBrick13_7 "Voltage of brick 13";
CM_ BO_ 2566862846 "Voltages of bricks 13-14";
CM_ SG_ 2566862846 BATT_vBrick14_8 "Voltage of brick 14";
CM_ SG_ 2566862846 BATT_vBrick13_8 "Voltage of brick 13";
CM_ BO_ 2566862847 "Voltages of bricks 13-14";
CM_ SG_ 2566862847 BATT_vBrick14_9 "Voltage of brick 14";
CM_ SG_ 2566862847 BATT_vBrick13_9 "Voltage of brick 13";
CM_ SG_ 2566865397 BATT_iPackFiltered "Filtered charge/discharge rate in ampere - positive for charge, negative for discharge.";
CM_ SG_ 2566865397 BATT_vPack "Voltage of the pack";
CM_ SG_ 2566865397 BATT_vPackLoad "Voltage measured across load";
CM_ SG_ 2566865397 BATT_iPack "Pack current - combined current of all modules";
CM_ BO_ 2566866165 "Battery min-max data";
CM_ SG_ 2566866165 BATT_vPackModuleMinID "ID of minimum brick voltage ";
CM_ SG_ 2566866165 BATT_vPackBrickMin "Minimum brick voltage ";
CM_ SG_ 2566866165 BATT_vPackModuleMaxID "ID of maximum brick voltage ";
CM_ SG_ 2566866165 BATT_vPackBrickMax "Maximum brick voltage ";
CM_ SG_ 2566866165 BATT_tPackModuleMinID "ID of minimum Battery temperature ";
CM_ SG_ 2566866165 BATT_tPackModuleMin "Minimum Battery temperature";
CM_ SG_ 2566866165 BATT_tPackModuleMaxID "ID of maximum Battery temperature ";
CM_ SG_ 2566866165 BATT_tPackModuleMax "Maximum Battery temperature";
CM_ BO_ 2566866422 "Battery SOC";
CM_ SG_ 2566866422 BATT_sohcMod_0 "State of Charge for the battery pack";
CM_ SG_ 2566866422 BATT_socMod_0 "State of Charge for the battery pack";
CM_ SG_ 2566866422 BATT_socLimiting_0 "State of charge of battery brick which is the limiting";
CM_ SG_ 2566866422 BATT_idSOCLimiting_0 "ID of limiting brick";
CM_ BO_ 2566866423 "Battery SOC";
CM_ SG_ 2566866423 BATT_sohcMod_1 "State of Charge for the battery pack";
CM_ SG_ 2566866423 BATT_socMod_1 "State of Charge for the battery pack";
CM_ SG_ 2566866423 BATT_socLimiting_1 "State of charge of battery brick which is the limiting";
CM_ SG_ 2566866423 BATT_idSOCLimiting_1 "ID of limiting brick";
CM_ BO_ 2566866424 "Battery SOC";
CM_ SG_ 2566866424 BATT_sohcMod_2 "State of Charge for the battery pack";
CM_ SG_ 2566866424 BATT_socMod_2 "State of Charge for the battery pack";
CM_ SG_ 2566866424 BATT_socLimiting_2 "State of charge of battery brick which is the limiting";
CM_ SG_ 2566866424 BATT_idSOCLimiting_2 "ID of limiting brick";
CM_ BO_ 2566866425 "Battery SOC";
CM_ SG_ 2566866425 BATT_sohcMod_3 "State of Charge for the battery pack";
CM_ SG_ 2566866425 BATT_socMod_3 "State of Charge for the battery pack";
CM_ SG_ 2566866425 BATT_socLimiting_3 "State of charge of battery brick which is the limiting";
CM_ SG_ 2566866425 BATT_idSOCLimiting_3 "ID of limiting brick";
CM_ BO_ 2566866426 "Battery SOC";
CM_ SG_ 2566866426 BATT_sohcMod_4 "State of Charge for the battery pack";
CM_ SG_ 2566866426 BATT_socMod_4 "State of Charge for the battery pack";
CM_ SG_ 2566866426 BATT_socLimiting_4 "State of charge of battery brick which is the limiting";
CM_ SG_ 2566866426 BATT_idSOCLimiting_4 "ID of limiting brick";
CM_ BO_ 2566866427 "Battery SOC";
CM_ SG_ 2566866427 BATT_sohcMod_5 "State of Charge for the battery pack";
CM_ SG_ 2566866427 BATT_socMod_5 "State of Charge for the battery pack";
CM_ SG_ 2566866427 BATT_socLimiting_5 "State of charge of battery brick which is the limiting";
CM_ SG_ 2566866427 BATT_idSOCLimiting_5 "ID of limiting brick";
CM_ BO_ 2566866428 "Battery SOC";
CM_ SG_ 2566866428 BATT_sohcMod_6 "State of Charge for the battery pack";
CM_ SG_ 2566866428 BATT_socMod_6 "State of Charge for the battery pack";
CM_ SG_ 2566866428 BATT_socLimiting_6 "State of charge of battery brick which is the limiting";
CM_ SG_ 2566866428 BATT_idSOCLimiting_6 "ID of limiting brick";
CM_ BO_ 2566866429 "Battery SOC";
CM_ SG_ 2566866429 BATT_sohcMod_7 "State of Charge for the battery pack";
CM_ SG_ 2566866429 BATT_socMod_7 "State of Charge for the battery pack";
CM_ SG_ 2566866429 BATT_socLimiting_7 "State of charge of battery brick which is the limiting";
CM_ SG_ 2566866429 BATT_idSOCLimiting_7 "ID of limiting brick";
CM_ BO_ 2566866430 "Battery SOC";
CM_ SG_ 2566866430 BATT_sohcMod_8 "State of Charge for the battery pack";
CM_ SG_ 2566866430 BATT_socMod_8 "State of Charge for the battery pack";
CM_ SG_ 2566866430 BATT_socLimiting_8 "State of charge of battery brick which is the limiting";
CM_ SG_ 2566866430 BATT_idSOCLimiting_8 "ID of limiting brick";
CM_ BO_ 2566866431 "Battery SOC";
CM_ SG_ 2566866431 BATT_sohcMod_9 "State of Charge for the battery pack";
CM_ SG_ 2566866431 BATT_socMod_9 "State of Charge for the battery pack";
CM_ SG_ 2566866431 BATT_socLimiting_9 "State of charge of battery brick which is the limiting";
CM_ SG_ 2566866431 BATT_idSOCLimiting_9 "ID of limiting brick";
CM_ SG_ 2566866677 BATT_packUserSOC "User state of charge for the battery pack";
CM_ SG_ 2566866677 BATT_packSOC "State of Charge for the battery pack";
CM_ BO_ 2566867189 "Battery limits";
CM_ SG_ 2566867189 BATT_vBusMin "Minimum voltage limit sent to inverter";
CM_ SG_ 2566867189 BATT_iPackDchLimit10s "Current discharge limit in A";
CM_ SG_ 2566867189 BATT_iPackDchLimitCont "Current discharge limit in A";
CM_ SG_ 2566867445 BATT_chargeError "0 - NO Charge Error
1 - Charge Error";
CM_ SG_ 2566867445 BATT_chargerMode "Charge Mode (CC-CV)";
CM_ SG_ 2566867445 BATT_chargerConnected "Charger connected status";
CM_ SG_ 2566867445 BATT_chargeMode "Charge Mode (CC-CV)";
CM_ SG_ 2566867445 BATT_chargeStatus "Charge Status";
CM_ SG_ 2566867445 BATT_chargeEnable "0 - Request to disable charger if enabled
1 - Request to enable charger if disabled";
CM_ SG_ 2566867445 BATT_chargingVoltage "Charger output voltage as measured by battery";
CM_ SG_ 2566867445 BATT_chargingCurrent "Maximum charger output current as requested by battery";
CM_ SG_ 2566867701 BATT_packAliveCntr "Battery Pack Alive Counter";
CM_ SG_ 2566867701 BATT_packSpeakerInstanceID "Battery Pack Master Module Instance ID";
CM_ SG_ 2566867701 BATT_packNumModsDataValid "Number of parallel modules with valid data";
CM_ SG_ 2566867701 BATT_packNumModsOnNetwork "Number of modules on the network";
CM_ SG_ 2566867701 BATT_packModComStatusOK_M "Bit mask for module communications status (1 = OK)";
CM_ SG_ 2566867701 BATT_fetPackDsgWelded "Pack DSG FETs welded status";
CM_ SG_ 2566867701 BATT_fetPackChgWelded "Pack CHG FETs welded status";
CM_ SG_ 2566867701 BATT_packNumModsConfigured "Number of parallel modules configured for the pack";
CM_ SG_ 2566867701 BATT_packNumModsOnHvBus "Number of modules on the HV bus";
CM_ SG_ 2566867701 BATT_packState "Reports the current state of the battery";
CM_ BO_ 2566870005 "Pack capacity";
CM_ SG_ 2566870005 BATT_packRemainingCap_Ah "Remaining charge";
CM_ SG_ 2566870005 BATT_packFullChargeCap_Ah "Estimated full charge capacity";
CM_ BO_ 2566870774 "Voltages of bricks 1-4";
CM_ SG_ 2566870774 BATT_vBrick02_0 "Voltage of brick 2";
CM_ SG_ 2566870774 BATT_vBrick03_0 "Voltage of brick 3";
CM_ SG_ 2566870774 BATT_vBrick01_0 "Voltage of brick 1";
CM_ SG_ 2566870774 BATT_vBrick04_0 "Voltage of brick 4";
CM_ BO_ 2566870775 "Voltages of bricks 1-4";
CM_ SG_ 2566870775 BATT_vBrick02_1 "Voltage of brick 2";
CM_ SG_ 2566870775 BATT_vBrick03_1 "Voltage of brick 3";
CM_ SG_ 2566870775 BATT_vBrick01_1 "Voltage of brick 1";
CM_ SG_ 2566870775 BATT_vBrick04_1 "Voltage of brick 4";
CM_ BO_ 2566870776 "Voltages of bricks 1-4";
CM_ SG_ 2566870776 BATT_vBrick02_2 "Voltage of brick 2";
CM_ SG_ 2566870776 BATT_vBrick03_2 "Voltage of brick 3";
CM_ SG_ 2566870776 BATT_vBrick01_2 "Voltage of brick 1";
CM_ SG_ 2566870776 BATT_vBrick04_2 "Voltage of brick 4";
CM_ BO_ 2566870777 "Voltages of bricks 1-4";
CM_ SG_ 2566870777 BATT_vBrick02_3 "Voltage of brick 2";
CM_ SG_ 2566870777 BATT_vBrick03_3 "Voltage of brick 3";
CM_ SG_ 2566870777 BATT_vBrick01_3 "Voltage of brick 1";
CM_ SG_ 2566870777 BATT_vBrick04_3 "Voltage of brick 4";
CM_ BO_ 2566870778 "Voltages of bricks 1-4";
CM_ SG_ 2566870778 BATT_vBrick02_4 "Voltage of brick 2";
CM_ SG_ 2566870778 BATT_vBrick03_4 "Voltage of brick 3";
CM_ SG_ 2566870778 BATT_vBrick01_4 "Voltage of brick 1";
CM_ SG_ 2566870778 BATT_vBrick04_4 "Voltage of brick 4";
CM_ BO_ 2566870779 "Voltages of bricks 1-4";
CM_ SG_ 2566870779 BATT_vBrick02_5 "Voltage of brick 2";
CM_ SG_ 2566870779 BATT_vBrick03_5 "Voltage of brick 3";
CM_ SG_ 2566870779 BATT_vBrick01_5 "Voltage of brick 1";
CM_ SG_ 2566870779 BATT_vBrick04_5 "Voltage of brick 4";
CM_ BO_ 2566870780 "Voltages of bricks 1-4";
CM_ SG_ 2566870780 BATT_vBrick02_6 "Voltage of brick 2";
CM_ SG_ 2566870780 BATT_vBrick03_6 "Voltage of brick 3";
CM_ SG_ 2566870780 BATT_vBrick01_6 "Voltage of brick 1";
CM_ SG_ 2566870780 BATT_vBrick04_6 "Voltage of brick 4";
CM_ BO_ 2566870781 "Voltages of bricks 1-4";
CM_ SG_ 2566870781 BATT_vBrick02_7 "Voltage of brick 2";
CM_ SG_ 2566870781 BATT_vBrick03_7 "Voltage of brick 3";
CM_ SG_ 2566870781 BATT_vBrick01_7 "Voltage of brick 1";
CM_ SG_ 2566870781 BATT_vBrick04_7 "Voltage of brick 4";
CM_ BO_ 2566870782 "Voltages of bricks 1-4";
CM_ SG_ 2566870782 BATT_vBrick02_8 "Voltage of brick 2";
CM_ SG_ 2566870782 BATT_vBrick03_8 "Voltage of brick 3";
CM_ SG_ 2566870782 BATT_vBrick01_8 "Voltage of brick 1";
CM_ SG_ 2566870782 BATT_vBrick04_8 "Voltage of brick 4";
CM_ BO_ 2566870783 "Voltages of bricks 1-4";
CM_ SG_ 2566870783 BATT_vBrick02_9 "Voltage of brick 2";
CM_ SG_ 2566870783 BATT_vBrick03_9 "Voltage of brick 3";
CM_ SG_ 2566870783 BATT_vBrick01_9 "Voltage of brick 1";
CM_ SG_ 2566870783 BATT_vBrick04_9 "Voltage of brick 4";
CM_ SG_ 2566871376 CHRG_chargerEnabled "0 - Charger is disabled
1 - Charger is enabled";
CM_ SG_ 2566871376 CHRG_chargingVoltage "Output voltage from charger";
CM_ SG_ 2566871376 CHRG_chargingCurrent "Output current from charger";
CM_ SG_ 2566873333 NODE_ID_CLAIM_RND "Node ID Claim Number RND";
CM_ SG_ 2566873333 NODE_ID_CLAIM_SN "Node ID Claim Number SN";
CM_ SG_ 2566874870 BATT_IGNLO_Status_0 "0 - Unkown
1 - Standby
2 - Drive
3 - Arbitration
";
CM_ SG_ 2566874870 BATT_serialNumber_0 "Unique serial number";
CM_ SG_ 2566874870 BATT_expectedModule_0 "Expected number of modules";
CM_ SG_ 2566874870 BATT_deviceChemistry_0 "Device chemistry.  Note strict SMBus handles this with a character string";
CM_ SG_ 2566874871 BATT_IGNLO_Status_1 "0 - Unkown
1 - Standby
2 - Drive
3 - Arbitration
";
CM_ SG_ 2566874871 BATT_serialNumber_1 "Unique serial number";
CM_ SG_ 2566874871 BATT_expectedModule_1 "Expected number of modules";
CM_ SG_ 2566874871 BATT_deviceChemistry_1 "Device chemistry.  Note strict SMBus handles this with a character string";
CM_ SG_ 2566874872 BATT_IGNLO_Status_2 "0 - Unkown
1 - Standby
2 - Drive
3 - Arbitration
";
CM_ SG_ 2566874872 BATT_serialNumber_2 "Unique serial number";
CM_ SG_ 2566874872 BATT_expectedModule_2 "Expected number of modules";
CM_ SG_ 2566874872 BATT_deviceChemistry_2 "Device chemistry.  Note strict SMBus handles this with a character string";
CM_ SG_ 2566874873 BATT_IGNLO_Status_3 "0 - Unkown
1 - Standby
2 - Drive
3 - Arbitration
";
CM_ SG_ 2566874873 BATT_serialNumber_3 "Unique serial number";
CM_ SG_ 2566874873 BATT_expectedModule_3 "Expected number of modules";
CM_ SG_ 2566874873 BATT_deviceChemistry_3 "Device chemistry.  Note strict SMBus handles this with a character string";
CM_ SG_ 2566874874 BATT_IGNLO_Status_4 "0 - Unkown
1 - Standby
2 - Drive
3 - Arbitration
";
CM_ SG_ 2566874874 BATT_serialNumber_4 "Unique serial number";
CM_ SG_ 2566874874 BATT_expectedModule_4 "Expected number of modules";
CM_ SG_ 2566874874 BATT_deviceChemistry_4 "Device chemistry.  Note strict SMBus handles this with a character string";
CM_ SG_ 2566874875 BATT_IGNLO_Status_5 "0 - Unkown
1 - Standby
2 - Drive
3 - Arbitration
";
CM_ SG_ 2566874875 BATT_serialNumber_5 "Unique serial number";
CM_ SG_ 2566874875 BATT_expectedModule_5 "Expected number of modules";
CM_ SG_ 2566874875 BATT_deviceChemistry_5 "Device chemistry.  Note strict SMBus handles this with a character string";
CM_ SG_ 2566874876 BATT_IGNLO_Status_6 "0 - Unkown
1 - Standby
2 - Drive
3 - Arbitration
";
CM_ SG_ 2566874876 BATT_serialNumber_6 "Unique serial number";
CM_ SG_ 2566874876 BATT_expectedModule_6 "Expected number of modules";
CM_ SG_ 2566874876 BATT_deviceChemistry_6 "Device chemistry.  Note strict SMBus handles this with a character string";
CM_ SG_ 2566874877 BATT_IGNLO_Status_7 "0 - Unkown
1 - Standby
2 - Drive
3 - Arbitration
";
CM_ SG_ 2566874877 BATT_serialNumber_7 "Unique serial number";
CM_ SG_ 2566874877 BATT_expectedModule_7 "Expected number of modules";
CM_ SG_ 2566874877 BATT_deviceChemistry_7 "Device chemistry.  Note strict SMBus handles this with a character string";
CM_ SG_ 2566874878 BATT_IGNLO_Status_8 "0 - Unkown
1 - Standby
2 - Drive
3 - Arbitration
";
CM_ SG_ 2566874878 BATT_serialNumber_8 "Unique serial number";
CM_ SG_ 2566874878 BATT_expectedModule_8 "Expected number of modules";
CM_ SG_ 2566874878 BATT_deviceChemistry_8 "Device chemistry.  Note strict SMBus handles this with a character string";
CM_ SG_ 2566874879 BATT_IGNLO_Status_9 "0 - Unkown
1 - Standby
2 - Drive
3 - Arbitration
";
CM_ SG_ 2566874879 BATT_serialNumber_9 "Unique serial number";
CM_ SG_ 2566874879 BATT_expectedModule_9 "Expected number of modules";
CM_ SG_ 2566874879 BATT_deviceChemistry_9 "Device chemistry.  Note strict SMBus handles this with a character string";
CM_ BO_ 2566878966 "Total Ah charged and discharged counters";
CM_ SG_ 2566878966 BATT_ahDchTotal_0 "Total Ah discharged";
CM_ SG_ 2566878966 BATT_ahChgTotal_0 "Total Ah charged";
CM_ BO_ 2566878967 "Total Ah charged and discharged counters";
CM_ SG_ 2566878967 BATT_ahDchTotal_1 "Total Ah discharged";
CM_ SG_ 2566878967 BATT_ahChgTotal_1 "Total Ah charged";
CM_ BO_ 2566878968 "Total Ah charged and discharged counters";
CM_ SG_ 2566878968 BATT_ahDchTotal_2 "Total Ah discharged";
CM_ SG_ 2566878968 BATT_ahChgTotal_2 "Total Ah charged";
CM_ BO_ 2566878969 "Total Ah charged and discharged counters";
CM_ SG_ 2566878969 BATT_ahDchTotal_3 "Total Ah discharged";
CM_ SG_ 2566878969 BATT_ahChgTotal_3 "Total Ah charged";
CM_ BO_ 2566878970 "Total Ah charged and discharged counters";
CM_ SG_ 2566878970 BATT_ahDchTotal_4 "Total Ah discharged";
CM_ SG_ 2566878970 BATT_ahChgTotal_4 "Total Ah charged";
CM_ BO_ 2566878971 "Total Ah charged and discharged counters";
CM_ SG_ 2566878971 BATT_ahDchTotal_5 "Total Ah discharged";
CM_ SG_ 2566878971 BATT_ahChgTotal_5 "Total Ah charged";
CM_ BO_ 2566878972 "Total Ah charged and discharged counters";
CM_ SG_ 2566878972 BATT_ahDchTotal_6 "Total Ah discharged";
CM_ SG_ 2566878972 BATT_ahChgTotal_6 "Total Ah charged";
CM_ BO_ 2566878973 "Total Ah charged and discharged counters";
CM_ SG_ 2566878973 BATT_ahDchTotal_7 "Total Ah discharged";
CM_ SG_ 2566878973 BATT_ahChgTotal_7 "Total Ah charged";
CM_ BO_ 2566878974 "Total Ah charged and discharged counters";
CM_ SG_ 2566878974 BATT_ahDchTotal_8 "Total Ah discharged";
CM_ SG_ 2566878974 BATT_ahChgTotal_8 "Total Ah charged";
CM_ BO_ 2566878975 "Total Ah charged and discharged counters";
CM_ SG_ 2566878975 BATT_ahDchTotal_9 "Total Ah discharged";
CM_ SG_ 2566878975 BATT_ahChgTotal_9 "Total Ah charged";
CM_ BO_ 2566879265 "HOST battery request";
CM_ SG_ 2566879265 HOST_standbyModConnectRequest "Multi-module request standby module to join bus";
CM_ SG_ 2566879265 HOST_dbgInhibitContDrivePower "Debug Force Inhibit Allow Continuous Drive Power";
CM_ SG_ 2566879265 HOST_dbgInhibitRegen "Debug Force Inhibit Allow Regen";
CM_ SG_ 2566879265 HOST_dbgInhibitFullPower "Debug Force Inhibit Allow Full Power";
CM_ SG_ 2566879265 HOST_dbgResetEep "Debug reset EEPROM (1 = reset)";
CM_ SG_ 2566879265 HOST_stateRequest "State to be requested from battery by host";
CM_ BO_ 2566881313 "HOST node request";
CM_ SG_ 2566881313 HOST_securityKey "Security Key";
CM_ SG_ 2566881313 HOST_startNodeId "Start node ID claim flag";
CM_ BO_ 2566881525 "Battery limits";
CM_ SG_ 2566881525 BATT_vBusMax "Maximum voltage limit sent to inverter";
CM_ SG_ 2566881525 BATT_iPackChgLimit10s "Current recharge limit in A";
CM_ SG_ 2566881525 BATT_iPackChgLimitCont "Current recharge limit in A";
CM_ BO_ 2566883062 "Capacity of bricks 1-4";
CM_ SG_ 2566883062 BATT_capBrick04_0 "Capacity of brick 4";
CM_ SG_ 2566883062 BATT_capBrick03_0 "Capacity of brick 3";
CM_ SG_ 2566883062 BATT_capBrick02_0 "Capacity of brick 2";
CM_ SG_ 2566883062 BATT_capBrick01_0 "Capacity of brick 1";
CM_ BO_ 2566883063 "Capacity of bricks 1-4";
CM_ SG_ 2566883063 BATT_capBrick04_1 "Capacity of brick 4";
CM_ SG_ 2566883063 BATT_capBrick03_1 "Capacity of brick 3";
CM_ SG_ 2566883063 BATT_capBrick02_1 "Capacity of brick 2";
CM_ SG_ 2566883063 BATT_capBrick01_1 "Capacity of brick 1";
CM_ BO_ 2566883064 "Capacity of bricks 1-4";
CM_ SG_ 2566883064 BATT_capBrick04_2 "Capacity of brick 4";
CM_ SG_ 2566883064 BATT_capBrick03_2 "Capacity of brick 3";
CM_ SG_ 2566883064 BATT_capBrick02_2 "Capacity of brick 2";
CM_ SG_ 2566883064 BATT_capBrick01_2 "Capacity of brick 1";
CM_ BO_ 2566883065 "Capacity of bricks 1-4";
CM_ SG_ 2566883065 BATT_capBrick04_3 "Capacity of brick 4";
CM_ SG_ 2566883065 BATT_capBrick03_3 "Capacity of brick 3";
CM_ SG_ 2566883065 BATT_capBrick02_3 "Capacity of brick 2";
CM_ SG_ 2566883065 BATT_capBrick01_3 "Capacity of brick 1";
CM_ BO_ 2566883066 "Capacity of bricks 1-4";
CM_ SG_ 2566883066 BATT_capBrick04_4 "Capacity of brick 4";
CM_ SG_ 2566883066 BATT_capBrick03_4 "Capacity of brick 3";
CM_ SG_ 2566883066 BATT_capBrick02_4 "Capacity of brick 2";
CM_ SG_ 2566883066 BATT_capBrick01_4 "Capacity of brick 1";
CM_ BO_ 2566883067 "Capacity of bricks 1-4";
CM_ SG_ 2566883067 BATT_capBrick04_5 "Capacity of brick 4";
CM_ SG_ 2566883067 BATT_capBrick03_5 "Capacity of brick 3";
CM_ SG_ 2566883067 BATT_capBrick02_5 "Capacity of brick 2";
CM_ SG_ 2566883067 BATT_capBrick01_5 "Capacity of brick 1";
CM_ BO_ 2566883068 "Capacity of bricks 1-4";
CM_ SG_ 2566883068 BATT_capBrick04_6 "Capacity of brick 4";
CM_ SG_ 2566883068 BATT_capBrick03_6 "Capacity of brick 3";
CM_ SG_ 2566883068 BATT_capBrick02_6 "Capacity of brick 2";
CM_ SG_ 2566883068 BATT_capBrick01_6 "Capacity of brick 1";
CM_ BO_ 2566883069 "Capacity of bricks 1-4";
CM_ SG_ 2566883069 BATT_capBrick04_7 "Capacity of brick 4";
CM_ SG_ 2566883069 BATT_capBrick03_7 "Capacity of brick 3";
CM_ SG_ 2566883069 BATT_capBrick02_7 "Capacity of brick 2";
CM_ SG_ 2566883069 BATT_capBrick01_7 "Capacity of brick 1";
CM_ BO_ 2566883070 "Capacity of bricks 1-4";
CM_ SG_ 2566883070 BATT_capBrick04_8 "Capacity of brick 4";
CM_ SG_ 2566883070 BATT_capBrick03_8 "Capacity of brick 3";
CM_ SG_ 2566883070 BATT_capBrick02_8 "Capacity of brick 2";
CM_ SG_ 2566883070 BATT_capBrick01_8 "Capacity of brick 1";
CM_ BO_ 2566883071 "Capacity of bricks 1-4";
CM_ SG_ 2566883071 BATT_capBrick04_9 "Capacity of brick 4";
CM_ SG_ 2566883071 BATT_capBrick03_9 "Capacity of brick 3";
CM_ SG_ 2566883071 BATT_capBrick02_9 "Capacity of brick 2";
CM_ SG_ 2566883071 BATT_capBrick01_9 "Capacity of brick 1";
CM_ BO_ 2566885622 "Battery load status";
CM_ SG_ 2566885622 BATT_modPchgDriveID_0 "ID of module calculated to do pre-charge";
CM_ SG_ 2566885622 BATT_modPchgChargeID_0 "ID of module calculated to do pre-charge";
CM_ SG_ 2566885622 BATT_resMod_0 "Impedance of module";
CM_ SG_ 2566885622 BATT_voirMod_0 "Battery Voir Voltage";
CM_ SG_ 2566885622 BATT_vModLoad_0 "Voltage measured across load";
CM_ BO_ 2566885623 "Battery load status";
CM_ SG_ 2566885623 BATT_modPchgDriveID_1 "ID of module calculated to do pre-charge";
CM_ SG_ 2566885623 BATT_modPchgChargeID_1 "ID of module calculated to do pre-charge";
CM_ SG_ 2566885623 BATT_resMod_1 "Impedance of module";
CM_ SG_ 2566885623 BATT_voirMod_1 "Battery Voir Voltage";
CM_ SG_ 2566885623 BATT_vModLoad_1 "Voltage measured across load";
CM_ BO_ 2566885624 "Battery load status";
CM_ SG_ 2566885624 BATT_modPchgDriveID_2 "ID of module calculated to do pre-charge";
CM_ SG_ 2566885624 BATT_modPchgChargeID_2 "ID of module calculated to do pre-charge";
CM_ SG_ 2566885624 BATT_resMod_2 "Impedance of module";
CM_ SG_ 2566885624 BATT_voirMod_2 "Battery Voir Voltage";
CM_ SG_ 2566885624 BATT_vModLoad_2 "Voltage measured across load";
CM_ BO_ 2566885625 "Battery load status";
CM_ SG_ 2566885625 BATT_modPchgDriveID_3 "ID of module calculated to do pre-charge";
CM_ SG_ 2566885625 BATT_modPchgChargeID_3 "ID of module calculated to do pre-charge";
CM_ SG_ 2566885625 BATT_resMod_3 "Impedance of module";
CM_ SG_ 2566885625 BATT_voirMod_3 "Battery Voir Voltage";
CM_ SG_ 2566885625 BATT_vModLoad_3 "Voltage measured across load";
CM_ BO_ 2566885626 "Battery load status";
CM_ SG_ 2566885626 BATT_modPchgDriveID_4 "ID of module calculated to do pre-charge";
CM_ SG_ 2566885626 BATT_modPchgChargeID_4 "ID of module calculated to do pre-charge";
CM_ SG_ 2566885626 BATT_resMod_4 "Impedance of module";
CM_ SG_ 2566885626 BATT_voirMod_4 "Battery Voir Voltage";
CM_ SG_ 2566885626 BATT_vModLoad_4 "Voltage measured across load";
CM_ BO_ 2566885627 "Battery load status";
CM_ SG_ 2566885627 BATT_modPchgDriveID_5 "ID of module calculated to do pre-charge";
CM_ SG_ 2566885627 BATT_modPchgChargeID_5 "ID of module calculated to do pre-charge";
CM_ SG_ 2566885627 BATT_resMod_5 "Impedance of module";
CM_ SG_ 2566885627 BATT_voirMod_5 "Battery Voir Voltage";
CM_ SG_ 2566885627 BATT_vModLoad_5 "Voltage measured across load";
CM_ BO_ 2566885628 "Battery load status";
CM_ SG_ 2566885628 BATT_modPchgDriveID_6 "ID of module calculated to do pre-charge";
CM_ SG_ 2566885628 BATT_modPchgChargeID_6 "ID of module calculated to do pre-charge";
CM_ SG_ 2566885628 BATT_resMod_6 "Impedance of module";
CM_ SG_ 2566885628 BATT_voirMod_6 "Battery Voir Voltage";
CM_ SG_ 2566885628 BATT_vModLoad_6 "Voltage measured across load";
CM_ BO_ 2566885629 "Battery load status";
CM_ SG_ 2566885629 BATT_modPchgDriveID_7 "ID of module calculated to do pre-charge";
CM_ SG_ 2566885629 BATT_modPchgChargeID_7 "ID of module calculated to do pre-charge";
CM_ SG_ 2566885629 BATT_resMod_7 "Impedance of module";
CM_ SG_ 2566885629 BATT_voirMod_7 "Battery Voir Voltage";
CM_ SG_ 2566885629 BATT_vModLoad_7 "Voltage measured across load";
CM_ BO_ 2566885630 "Battery load status";
CM_ SG_ 2566885630 BATT_modPchgDriveID_8 "ID of module calculated to do pre-charge";
CM_ SG_ 2566885630 BATT_modPchgChargeID_8 "ID of module calculated to do pre-charge";
CM_ SG_ 2566885630 BATT_resMod_8 "Impedance of module";
CM_ SG_ 2566885630 BATT_voirMod_8 "Battery Voir Voltage";
CM_ SG_ 2566885630 BATT_vModLoad_8 "Voltage measured across load";
CM_ BO_ 2566885631 "Battery load status";
CM_ SG_ 2566885631 BATT_modPchgDriveID_9 "ID of module calculated to do pre-charge";
CM_ SG_ 2566885631 BATT_modPchgChargeID_9 "ID of module calculated to do pre-charge";
CM_ SG_ 2566885631 BATT_resMod_9 "Impedance of module";
CM_ SG_ 2566885631 BATT_voirMod_9 "Battery Voir Voltage";
CM_ SG_ 2566885631 BATT_vModLoad_9 "Voltage measured across load";
CM_ BO_ 2566889718 "Battery min-max data";
CM_ SG_ 2566889718 BATT_tModuleMaxID_0 "ID of maximum Battery temperature ";
CM_ SG_ 2566889718 BATT_tModuleMinID_0 "ID of minimum Battery temperature ";
CM_ SG_ 2566889718 BATT_vBrickMaxID_0 "ID of maximum brick voltage ";
CM_ SG_ 2566889718 BATT_vBrickMinID_0 "ID of minimum brick voltage ";
CM_ SG_ 2566889718 BATT_tModuleMax_0 "Maximum Battery temperature";
CM_ SG_ 2566889718 BATT_tModuleMin_0 "Minimum Battery temperature";
CM_ SG_ 2566889718 BATT_vBrickMin_0 "Minimum brick voltage ";
CM_ SG_ 2566889718 BATT_vBrickMax_0 "Maximum brick voltage ";
CM_ BO_ 2566889719 "Battery min-max data";
CM_ SG_ 2566889719 BATT_tModuleMaxID_1 "ID of maximum Battery temperature ";
CM_ SG_ 2566889719 BATT_tModuleMinID_1 "ID of minimum Battery temperature ";
CM_ SG_ 2566889719 BATT_vBrickMaxID_1 "ID of maximum brick voltage ";
CM_ SG_ 2566889719 BATT_vBrickMinID_1 "ID of minimum brick voltage ";
CM_ SG_ 2566889719 BATT_tModuleMax_1 "Maximum Battery temperature";
CM_ SG_ 2566889719 BATT_tModuleMin_1 "Minimum Battery temperature";
CM_ SG_ 2566889719 BATT_vBrickMin_1 "Minimum brick voltage ";
CM_ SG_ 2566889719 BATT_vBrickMax_1 "Maximum brick voltage ";
CM_ BO_ 2566889720 "Battery min-max data";
CM_ SG_ 2566889720 BATT_tModuleMaxID_2 "ID of maximum Battery temperature ";
CM_ SG_ 2566889720 BATT_tModuleMinID_2 "ID of minimum Battery temperature ";
CM_ SG_ 2566889720 BATT_vBrickMaxID_2 "ID of maximum brick voltage ";
CM_ SG_ 2566889720 BATT_vBrickMinID_2 "ID of minimum brick voltage ";
CM_ SG_ 2566889720 BATT_tModuleMax_2 "Maximum Battery temperature";
CM_ SG_ 2566889720 BATT_tModuleMin_2 "Minimum Battery temperature";
CM_ SG_ 2566889720 BATT_vBrickMin_2 "Minimum brick voltage ";
CM_ SG_ 2566889720 BATT_vBrickMax_2 "Maximum brick voltage ";
CM_ BO_ 2566889721 "Battery min-max data";
CM_ SG_ 2566889721 BATT_tModuleMaxID_3 "ID of maximum Battery temperature ";
CM_ SG_ 2566889721 BATT_tModuleMinID_3 "ID of minimum Battery temperature ";
CM_ SG_ 2566889721 BATT_vBrickMaxID_3 "ID of maximum brick voltage ";
CM_ SG_ 2566889721 BATT_vBrickMinID_3 "ID of minimum brick voltage ";
CM_ SG_ 2566889721 BATT_tModuleMax_3 "Maximum Battery temperature";
CM_ SG_ 2566889721 BATT_tModuleMin_3 "Minimum Battery temperature";
CM_ SG_ 2566889721 BATT_vBrickMin_3 "Minimum brick voltage ";
CM_ SG_ 2566889721 BATT_vBrickMax_3 "Maximum brick voltage ";
CM_ BO_ 2566889722 "Battery min-max data";
CM_ SG_ 2566889722 BATT_tModuleMaxID_4 "ID of maximum Battery temperature ";
CM_ SG_ 2566889722 BATT_tModuleMinID_4 "ID of minimum Battery temperature ";
CM_ SG_ 2566889722 BATT_vBrickMaxID_4 "ID of maximum brick voltage ";
CM_ SG_ 2566889722 BATT_vBrickMinID_4 "ID of minimum brick voltage ";
CM_ SG_ 2566889722 BATT_tModuleMax_4 "Maximum Battery temperature";
CM_ SG_ 2566889722 BATT_tModuleMin_4 "Minimum Battery temperature";
CM_ SG_ 2566889722 BATT_vBrickMin_4 "Minimum brick voltage ";
CM_ SG_ 2566889722 BATT_vBrickMax_4 "Maximum brick voltage ";
CM_ BO_ 2566889723 "Battery min-max data";
CM_ SG_ 2566889723 BATT_tModuleMaxID_5 "ID of maximum Battery temperature ";
CM_ SG_ 2566889723 BATT_tModuleMinID_5 "ID of minimum Battery temperature ";
CM_ SG_ 2566889723 BATT_vBrickMaxID_5 "ID of maximum brick voltage ";
CM_ SG_ 2566889723 BATT_vBrickMinID_5 "ID of minimum brick voltage ";
CM_ SG_ 2566889723 BATT_tModuleMax_5 "Maximum Battery temperature";
CM_ SG_ 2566889723 BATT_tModuleMin_5 "Minimum Battery temperature";
CM_ SG_ 2566889723 BATT_vBrickMin_5 "Minimum brick voltage ";
CM_ SG_ 2566889723 BATT_vBrickMax_5 "Maximum brick voltage ";
CM_ BO_ 2566889724 "Battery min-max data";
CM_ SG_ 2566889724 BATT_tModuleMaxID_6 "ID of maximum Battery temperature ";
CM_ SG_ 2566889724 BATT_tModuleMinID_6 "ID of minimum Battery temperature ";
CM_ SG_ 2566889724 BATT_vBrickMaxID_6 "ID of maximum brick voltage ";
CM_ SG_ 2566889724 BATT_vBrickMinID_6 "ID of minimum brick voltage ";
CM_ SG_ 2566889724 BATT_tModuleMax_6 "Maximum Battery temperature";
CM_ SG_ 2566889724 BATT_tModuleMin_6 "Minimum Battery temperature";
CM_ SG_ 2566889724 BATT_vBrickMin_6 "Minimum brick voltage ";
CM_ SG_ 2566889724 BATT_vBrickMax_6 "Maximum brick voltage ";
CM_ BO_ 2566889725 "Battery min-max data";
CM_ SG_ 2566889725 BATT_tModuleMaxID_7 "ID of maximum Battery temperature ";
CM_ SG_ 2566889725 BATT_tModuleMinID_7 "ID of minimum Battery temperature ";
CM_ SG_ 2566889725 BATT_vBrickMaxID_7 "ID of maximum brick voltage ";
CM_ SG_ 2566889725 BATT_vBrickMinID_7 "ID of minimum brick voltage ";
CM_ SG_ 2566889725 BATT_tModuleMax_7 "Maximum Battery temperature";
CM_ SG_ 2566889725 BATT_tModuleMin_7 "Minimum Battery temperature";
CM_ SG_ 2566889725 BATT_vBrickMin_7 "Minimum brick voltage ";
CM_ SG_ 2566889725 BATT_vBrickMax_7 "Maximum brick voltage ";
CM_ BO_ 2566889726 "Battery min-max data";
CM_ SG_ 2566889726 BATT_tModuleMaxID_8 "ID of maximum Battery temperature ";
CM_ SG_ 2566889726 BATT_tModuleMinID_8 "ID of minimum Battery temperature ";
CM_ SG_ 2566889726 BATT_vBrickMaxID_8 "ID of maximum brick voltage ";
CM_ SG_ 2566889726 BATT_vBrickMinID_8 "ID of minimum brick voltage ";
CM_ SG_ 2566889726 BATT_tModuleMax_8 "Maximum Battery temperature";
CM_ SG_ 2566889726 BATT_tModuleMin_8 "Minimum Battery temperature";
CM_ SG_ 2566889726 BATT_vBrickMin_8 "Minimum brick voltage ";
CM_ SG_ 2566889726 BATT_vBrickMax_8 "Maximum brick voltage ";
CM_ BO_ 2566889727 "Battery min-max data";
CM_ SG_ 2566889727 BATT_tModuleMaxID_9 "ID of maximum Battery temperature ";
CM_ SG_ 2566889727 BATT_tModuleMinID_9 "ID of minimum Battery temperature ";
CM_ SG_ 2566889727 BATT_vBrickMaxID_9 "ID of maximum brick voltage ";
CM_ SG_ 2566889727 BATT_vBrickMinID_9 "ID of minimum brick voltage ";
CM_ SG_ 2566889727 BATT_tModuleMax_9 "Maximum Battery temperature";
CM_ SG_ 2566889727 BATT_tModuleMin_9 "Minimum Battery temperature";
CM_ SG_ 2566889727 BATT_vBrickMin_9 "Minimum brick voltage ";
CM_ SG_ 2566889727 BATT_vBrickMax_9 "Maximum brick voltage ";
CM_ BO_ 2566893814 "Module power available";
CM_ SG_ 2566893814 BATT_pwrModDchLimit_0 "Module discharge power available in kW";
CM_ SG_ 2566893814 BATT_pwrModChgLimit_0 "Module charge power available in kW";
CM_ BO_ 2566893815 "Module power available";
CM_ SG_ 2566893815 BATT_pwrModDchLimit_1 "Module discharge power available in kW";
CM_ SG_ 2566893815 BATT_pwrModChgLimit_1 "Module charge power available in kW";
CM_ BO_ 2566893816 "Module power available";
CM_ SG_ 2566893816 BATT_pwrModDchLimit_2 "Module discharge power available in kW";
CM_ SG_ 2566893816 BATT_pwrModChgLimit_2 "Module charge power available in kW";
CM_ BO_ 2566893817 "Module power available";
CM_ SG_ 2566893817 BATT_pwrModDchLimit_3 "Module discharge power available in kW";
CM_ SG_ 2566893817 BATT_pwrModChgLimit_3 "Module charge power available in kW";
CM_ BO_ 2566893818 "Module power available";
CM_ SG_ 2566893818 BATT_pwrModDchLimit_4 "Module discharge power available in kW";
CM_ SG_ 2566893818 BATT_pwrModChgLimit_4 "Module charge power available in kW";
CM_ BO_ 2566893819 "Module power available";
CM_ SG_ 2566893819 BATT_pwrModDchLimit_5 "Module discharge power available in kW";
CM_ SG_ 2566893819 BATT_pwrModChgLimit_5 "Module charge power available in kW";
CM_ BO_ 2566893820 "Module power available";
CM_ SG_ 2566893820 BATT_pwrModDchLimit_6 "Module discharge power available in kW";
CM_ SG_ 2566893820 BATT_pwrModChgLimit_6 "Module charge power available in kW";
CM_ BO_ 2566893821 "Module power available";
CM_ SG_ 2566893821 BATT_pwrModDchLimit_7 "Module discharge power available in kW";
CM_ SG_ 2566893821 BATT_pwrModChgLimit_7 "Module charge power available in kW";
CM_ BO_ 2566893822 "Module power available";
CM_ SG_ 2566893822 BATT_pwrModDchLimit_8 "Module discharge power available in kW";
CM_ SG_ 2566893822 BATT_pwrModChgLimit_8 "Module charge power available in kW";
CM_ BO_ 2566893823 "Module power available";
CM_ SG_ 2566893823 BATT_pwrModDchLimit_9 "Module discharge power available in kW";
CM_ SG_ 2566893823 BATT_pwrModChgLimit_9 "Module charge power available in kW";
CM_ SG_ 2566897910 BATT_manufacturerName_0 "Manufacturer name string. Length prefixed strings will work for strict SMBus and SPI, how to handle for CAN?";
CM_ SG_ 2566897910 BATT_manufacturerAccess_0 "Content determined by the Smart Battery's manufacturer";
CM_ SG_ 2566897910 BATT_manufactureYear_0 "Manufacture year biased by 1980";
CM_ SG_ 2566897910 BATT_manufactureMonth_0 "Manufacture month";
CM_ SG_ 2566897910 BATT_manufactureDay_0 "Manufacture day";
CM_ SG_ 2566897911 BATT_manufacturerName_1 "Manufacturer name string. Length prefixed strings will work for strict SMBus and SPI, how to handle for CAN?";
CM_ SG_ 2566897911 BATT_manufacturerAccess_1 "Content determined by the Smart Battery's manufacturer";
CM_ SG_ 2566897911 BATT_manufactureYear_1 "Manufacture year biased by 1980";
CM_ SG_ 2566897911 BATT_manufactureMonth_1 "Manufacture month";
CM_ SG_ 2566897911 BATT_manufactureDay_1 "Manufacture day";
CM_ SG_ 2566897912 BATT_manufacturerName_2 "Manufacturer name string. Length prefixed strings will work for strict SMBus and SPI, how to handle for CAN?";
CM_ SG_ 2566897912 BATT_manufacturerAccess_2 "Content determined by the Smart Battery's manufacturer";
CM_ SG_ 2566897912 BATT_manufactureYear_2 "Manufacture year biased by 1980";
CM_ SG_ 2566897912 BATT_manufactureMonth_2 "Manufacture month";
CM_ SG_ 2566897912 BATT_manufactureDay_2 "Manufacture day";
CM_ SG_ 2566897913 BATT_manufacturerName_3 "Manufacturer name string. Length prefixed strings will work for strict SMBus and SPI, how to handle for CAN?";
CM_ SG_ 2566897913 BATT_manufacturerAccess_3 "Content determined by the Smart Battery's manufacturer";
CM_ SG_ 2566897913 BATT_manufactureYear_3 "Manufacture year biased by 1980";
CM_ SG_ 2566897913 BATT_manufactureMonth_3 "Manufacture month";
CM_ SG_ 2566897913 BATT_manufactureDay_3 "Manufacture day";
CM_ SG_ 2566897914 BATT_manufacturerName_4 "Manufacturer name string. Length prefixed strings will work for strict SMBus and SPI, how to handle for CAN?";
CM_ SG_ 2566897914 BATT_manufacturerAccess_4 "Content determined by the Smart Battery's manufacturer";
CM_ SG_ 2566897914 BATT_manufactureYear_4 "Manufacture year biased by 1980";
CM_ SG_ 2566897914 BATT_manufactureMonth_4 "Manufacture month";
CM_ SG_ 2566897914 BATT_manufactureDay_4 "Manufacture day";
CM_ SG_ 2566897915 BATT_manufacturerName_5 "Manufacturer name string. Length prefixed strings will work for strict SMBus and SPI, how to handle for CAN?";
CM_ SG_ 2566897915 BATT_manufacturerAccess_5 "Content determined by the Smart Battery's manufacturer";
CM_ SG_ 2566897915 BATT_manufactureYear_5 "Manufacture year biased by 1980";
CM_ SG_ 2566897915 BATT_manufactureMonth_5 "Manufacture month";
CM_ SG_ 2566897915 BATT_manufactureDay_5 "Manufacture day";
CM_ SG_ 2566897916 BATT_manufacturerName_6 "Manufacturer name string. Length prefixed strings will work for strict SMBus and SPI, how to handle for CAN?";
CM_ SG_ 2566897916 BATT_manufacturerAccess_6 "Content determined by the Smart Battery's manufacturer";
CM_ SG_ 2566897916 BATT_manufactureYear_6 "Manufacture year biased by 1980";
CM_ SG_ 2566897916 BATT_manufactureMonth_6 "Manufacture month";
CM_ SG_ 2566897916 BATT_manufactureDay_6 "Manufacture day";
CM_ SG_ 2566897917 BATT_manufacturerName_7 "Manufacturer name string. Length prefixed strings will work for strict SMBus and SPI, how to handle for CAN?";
CM_ SG_ 2566897917 BATT_manufacturerAccess_7 "Content determined by the Smart Battery's manufacturer";
CM_ SG_ 2566897917 BATT_manufactureYear_7 "Manufacture year biased by 1980";
CM_ SG_ 2566897917 BATT_manufactureMonth_7 "Manufacture month";
CM_ SG_ 2566897917 BATT_manufactureDay_7 "Manufacture day";
CM_ SG_ 2566897918 BATT_manufacturerName_8 "Manufacturer name string. Length prefixed strings will work for strict SMBus and SPI, how to handle for CAN?";
CM_ SG_ 2566897918 BATT_manufacturerAccess_8 "Content determined by the Smart Battery's manufacturer";
CM_ SG_ 2566897918 BATT_manufactureYear_8 "Manufacture year biased by 1980";
CM_ SG_ 2566897918 BATT_manufactureMonth_8 "Manufacture month";
CM_ SG_ 2566897918 BATT_manufactureDay_8 "Manufacture day";
CM_ SG_ 2566897919 BATT_manufacturerName_9 "Manufacturer name string. Length prefixed strings will work for strict SMBus and SPI, how to handle for CAN?";
CM_ SG_ 2566897919 BATT_manufacturerAccess_9 "Content determined by the Smart Battery's manufacturer";
CM_ SG_ 2566897919 BATT_manufactureYear_9 "Manufacture year biased by 1980";
CM_ SG_ 2566897919 BATT_manufactureMonth_9 "Manufacture month";
CM_ SG_ 2566897919 BATT_manufactureDay_9 "Manufacture day";
CM_ BO_ 2566902006 "Battery capacity";
CM_ SG_ 2566902006 BATT_modFullChargeCap_Ah_0 "Estimated full charge capacity";
CM_ SG_ 2566902006 BATT_modRemainingCap_Ah_0 "Remaining charge";
CM_ BO_ 2566902007 "Battery capacity";
CM_ SG_ 2566902007 BATT_modFullChargeCap_Ah_1 "Estimated full charge capacity";
CM_ SG_ 2566902007 BATT_modRemainingCap_Ah_1 "Remaining charge";
CM_ BO_ 2566902008 "Battery capacity";
CM_ SG_ 2566902008 BATT_modFullChargeCap_Ah_2 "Estimated full charge capacity";
CM_ SG_ 2566902008 BATT_modRemainingCap_Ah_2 "Remaining charge";
CM_ BO_ 2566902009 "Battery capacity";
CM_ SG_ 2566902009 BATT_modFullChargeCap_Ah_3 "Estimated full charge capacity";
CM_ SG_ 2566902009 BATT_modRemainingCap_Ah_3 "Remaining charge";
CM_ BO_ 2566902010 "Battery capacity";
CM_ SG_ 2566902010 BATT_modFullChargeCap_Ah_4 "Estimated full charge capacity";
CM_ SG_ 2566902010 BATT_modRemainingCap_Ah_4 "Remaining charge";
CM_ BO_ 2566902011 "Battery capacity";
CM_ SG_ 2566902011 BATT_modFullChargeCap_Ah_5 "Estimated full charge capacity";
CM_ SG_ 2566902011 BATT_modRemainingCap_Ah_5 "Remaining charge";
CM_ BO_ 2566902012 "Battery capacity";
CM_ SG_ 2566902012 BATT_modFullChargeCap_Ah_6 "Estimated full charge capacity";
CM_ SG_ 2566902012 BATT_modRemainingCap_Ah_6 "Remaining charge";
CM_ BO_ 2566902013 "Battery capacity";
CM_ SG_ 2566902013 BATT_modFullChargeCap_Ah_7 "Estimated full charge capacity";
CM_ SG_ 2566902013 BATT_modRemainingCap_Ah_7 "Remaining charge";
CM_ BO_ 2566902014 "Battery capacity";
CM_ SG_ 2566902014 BATT_modFullChargeCap_Ah_8 "Estimated full charge capacity";
CM_ SG_ 2566902014 BATT_modRemainingCap_Ah_8 "Remaining charge";
CM_ BO_ 2566902015 "Battery capacity";
CM_ SG_ 2566902015 BATT_modFullChargeCap_Ah_9 "Estimated full charge capacity";
CM_ SG_ 2566902015 BATT_modRemainingCap_Ah_9 "Remaining charge";
CM_ BO_ 2566906102 "Battery limits";
CM_ SG_ 2566906102 BATT_vModChgLimit_0 "Voltage recharge limit sent to inverter";
CM_ SG_ 2566906102 BATT_iModChgLimit30s_0 "Current recharge limit in A";
CM_ SG_ 2566906102 BATT_iModChgLimit10s_0 "Current recharge limit in A";
CM_ SG_ 2566906102 BATT_iModChgLimitCont_0 "Current recharge limit in A";
CM_ BO_ 2566906103 "Battery limits";
CM_ SG_ 2566906103 BATT_vModChgLimit_1 "Voltage recharge limit sent to inverter";
CM_ SG_ 2566906103 BATT_iModChgLimit30s_1 "Current recharge limit in A";
CM_ SG_ 2566906103 BATT_iModChgLimit10s_1 "Current recharge limit in A";
CM_ SG_ 2566906103 BATT_iModChgLimitCont_1 "Current recharge limit in A";
CM_ BO_ 2566906104 "Battery limits";
CM_ SG_ 2566906104 BATT_vModChgLimit_2 "Voltage recharge limit sent to inverter";
CM_ SG_ 2566906104 BATT_iModChgLimit30s_2 "Current recharge limit in A";
CM_ SG_ 2566906104 BATT_iModChgLimit10s_2 "Current recharge limit in A";
CM_ SG_ 2566906104 BATT_iModChgLimitCont_2 "Current recharge limit in A";
CM_ BO_ 2566906105 "Battery limits";
CM_ SG_ 2566906105 BATT_vModChgLimit_3 "Voltage recharge limit sent to inverter";
CM_ SG_ 2566906105 BATT_iModChgLimit30s_3 "Current recharge limit in A";
CM_ SG_ 2566906105 BATT_iModChgLimit10s_3 "Current recharge limit in A";
CM_ SG_ 2566906105 BATT_iModChgLimitCont_3 "Current recharge limit in A";
CM_ BO_ 2566906106 "Battery limits";
CM_ SG_ 2566906106 BATT_vModChgLimit_4 "Voltage recharge limit sent to inverter";
CM_ SG_ 2566906106 BATT_iModChgLimit30s_4 "Current recharge limit in A";
CM_ SG_ 2566906106 BATT_iModChgLimit10s_4 "Current recharge limit in A";
CM_ SG_ 2566906106 BATT_iModChgLimitCont_4 "Current recharge limit in A";
CM_ BO_ 2566906107 "Battery limits";
CM_ SG_ 2566906107 BATT_vModChgLimit_5 "Voltage recharge limit sent to inverter";
CM_ SG_ 2566906107 BATT_iModChgLimit30s_5 "Current recharge limit in A";
CM_ SG_ 2566906107 BATT_iModChgLimit10s_5 "Current recharge limit in A";
CM_ SG_ 2566906107 BATT_iModChgLimitCont_5 "Current recharge limit in A";
CM_ BO_ 2566906108 "Battery limits";
CM_ SG_ 2566906108 BATT_vModChgLimit_6 "Voltage recharge limit sent to inverter";
CM_ SG_ 2566906108 BATT_iModChgLimit30s_6 "Current recharge limit in A";
CM_ SG_ 2566906108 BATT_iModChgLimit10s_6 "Current recharge limit in A";
CM_ SG_ 2566906108 BATT_iModChgLimitCont_6 "Current recharge limit in A";
CM_ BO_ 2566906109 "Battery limits";
CM_ SG_ 2566906109 BATT_vModChgLimit_7 "Voltage recharge limit sent to inverter";
CM_ SG_ 2566906109 BATT_iModChgLimit30s_7 "Current recharge limit in A";
CM_ SG_ 2566906109 BATT_iModChgLimit10s_7 "Current recharge limit in A";
CM_ SG_ 2566906109 BATT_iModChgLimitCont_7 "Current recharge limit in A";
CM_ BO_ 2566906110 "Battery limits";
CM_ SG_ 2566906110 BATT_vModChgLimit_8 "Voltage recharge limit sent to inverter";
CM_ SG_ 2566906110 BATT_iModChgLimit30s_8 "Current recharge limit in A";
CM_ SG_ 2566906110 BATT_iModChgLimit10s_8 "Current recharge limit in A";
CM_ SG_ 2566906110 BATT_iModChgLimitCont_8 "Current recharge limit in A";
CM_ BO_ 2566906111 "Battery limits";
CM_ SG_ 2566906111 BATT_vModChgLimit_9 "Voltage recharge limit sent to inverter";
CM_ SG_ 2566906111 BATT_iModChgLimit30s_9 "Current recharge limit in A";
CM_ SG_ 2566906111 BATT_iModChgLimit10s_9 "Current recharge limit in A";
CM_ SG_ 2566906111 BATT_iModChgLimitCont_9 "Current recharge limit in A";
BA_DEF_ SG_  "SigType" ENUM "Default","Range","RangeSigned","ASCII","Discrete","Control","ReferencePGN","DTC","StringDelimiter","StringLength","StringLengthControl","MessageCounter","MessageChecksum";
BA_DEF_ SG_  "GenSigSendType" ENUM "Cyclic","OnWrite","OnWriteWithRepetition","OnChange","OnChangeWithRepetition","IfActive","IfActiveWithRepetition","NoSigSendType";
BA_DEF_ BO_  "GenMsgDiag" ENUM "No","Yes";
BA_DEF_ BO_  "GenMsgInstanced" STRING ;
BA_DEF_ SG_  "GenSigType" ENUM "Extended","Diagnostic","Standard","Modified";
BA_DEF_ BO_  "GenMsgCycleTime" INT 0 0;
BA_DEF_ SG_  "GenSigSNA" INT 0 65535;
BA_DEF_ SG_  "Access" ENUM "r","rw";
BA_DEF_ BO_  "VFrameFormat" ENUM "StandardCAN","ExtendedCAN","reserved","J1939PG";
BA_DEF_DEF_  "SigType" "Default";
BA_DEF_DEF_  "GenSigSendType" "Cyclic";
BA_DEF_DEF_  "GenMsgDiag" "No";
BA_DEF_DEF_  "GenMsgInstanced" "No";
BA_DEF_DEF_  "GenSigType" "Standard";
BA_DEF_DEF_  "GenMsgCycleTime" 0;
BA_DEF_DEF_  "GenSigSNA" 0;
BA_DEF_DEF_  "Access" "r";
BA_DEF_DEF_  "VFrameFormat" "J1939PG";
BA_ "GenMsgDiag" BO_ 2566862841 1;
BA_ "GenMsgDiag" BO_ 2566862842 1;
BA_ "GenMsgDiag" BO_ 2566862843 1;
BA_ "GenMsgDiag" BO_ 2566862844 1;
BA_ "GenMsgDiag" BO_ 2566862845 1;
BA_ "GenMsgDiag" BO_ 2566862846 1;
BA_ "GenMsgDiag" BO_ 2566862847 1;
BA_ "GenMsgDiag" BO_ 2566866678 1;
BA_ "GenMsgDiag" BO_ 2566866679 1;
BA_ "GenMsgDiag" BO_ 2566866680 1;
BA_ "GenMsgDiag" BO_ 2566866681 1;
BA_ "GenMsgDiag" BO_ 2566866682 1;
BA_ "GenMsgDiag" BO_ 2566866683 1;
BA_ "GenMsgDiag" BO_ 2566866684 1;
BA_ "GenMsgDiag" BO_ 2566866685 1;
BA_ "GenMsgDiag" BO_ 2566866686 1;
BA_ "GenMsgDiag" BO_ 2566866687 1;
BA_ "GenMsgDiag" BO_ 2566867445 1;
BA_ "GenMsgDiag" BO_ 2566870517 1;
BA_ "GenMsgDiag" BO_ 2566870774 1;
BA_ "GenMsgDiag" BO_ 2566870775 1;
BA_ "GenMsgDiag" BO_ 2566870776 1;
BA_ "GenMsgDiag" BO_ 2566870777 1;
BA_ "GenMsgDiag" BO_ 2566870778 1;
BA_ "GenMsgDiag" BO_ 2566870779 1;
BA_ "GenMsgDiag" BO_ 2566870780 1;
BA_ "GenMsgDiag" BO_ 2566870781 1;
BA_ "GenMsgDiag" BO_ 2566870782 1;
BA_ "GenMsgDiag" BO_ 2566870783 1;
BA_ "GenMsgDiag" BO_ 2566873333 1;
BA_ "GenMsgDiag" BO_ 2566878966 1;
BA_ "GenMsgDiag" BO_ 2566878967 1;
BA_ "GenMsgDiag" BO_ 2566878968 1;
BA_ "GenMsgDiag" BO_ 2566878969 1;
BA_ "GenMsgDiag" BO_ 2566878970 1;
BA_ "GenMsgDiag" BO_ 2566878971 1;
BA_ "GenMsgDiag" BO_ 2566878972 1;
BA_ "GenMsgDiag" BO_ 2566878973 1;
BA_ "GenMsgDiag" BO_ 2566878974 1;
BA_ "GenMsgDiag" BO_ 2566878975 1;
BA_ "GenMsgDiag" BO_ 2566883062 1;
BA_ "GenMsgDiag" BO_ 2566883063 1;
BA_ "GenMsgDiag" BO_ 2566883064 1;
BA_ "GenMsgDiag" BO_ 2566883065 1;
BA_ "GenMsgDiag" BO_ 2566883066 1;
BA_ "GenMsgDiag" BO_ 2566883067 1;
BA_ "GenMsgDiag" BO_ 2566883068 1;
BA_ "GenMsgDiag" BO_ 2566883069 1;
BA_ "GenMsgDiag" BO_ 2566883070 1;
BA_ "GenMsgDiag" BO_ 2566883071 1;
BA_ "GenMsgDiag" BO_ 2566897910 1;
BA_ "GenMsgDiag" BO_ 2566897911 1;
BA_ "GenMsgDiag" BO_ 2566897912 1;
BA_ "GenMsgDiag" BO_ 2566897913 1;
BA_ "GenMsgDiag" BO_ 2566897914 1;
BA_ "GenMsgDiag" BO_ 2566897915 1;
BA_ "GenMsgDiag" BO_ 2566897916 1;
BA_ "GenMsgDiag" BO_ 2566897917 1;
BA_ "GenMsgDiag" BO_ 2566897918 1;
BA_ "GenMsgDiag" BO_ 2566897919 1;
BA_ "GenMsgInstanced" BO_ 2566862841 "False";
BA_ "GenMsgInstanced" BO_ 2566862842 "False";
BA_ "GenMsgInstanced" BO_ 2566862843 "False";
BA_ "GenMsgInstanced" BO_ 2566862844 "False";
BA_ "GenMsgInstanced" BO_ 2566862845 "False";
BA_ "GenMsgInstanced" BO_ 2566862846 "False";
BA_ "GenMsgInstanced" BO_ 2566862847 "False";
BA_ "GenMsgInstanced" BO_ 2566863094 "False";
BA_ "GenMsgInstanced" BO_ 2566863095 "False";
BA_ "GenMsgInstanced" BO_ 2566863096 "False";
BA_ "GenMsgInstanced" BO_ 2566863097 "False";
BA_ "GenMsgInstanced" BO_ 2566863098 "False";
BA_ "GenMsgInstanced" BO_ 2566863099 "False";
BA_ "GenMsgInstanced" BO_ 2566863100 "False";
BA_ "GenMsgInstanced" BO_ 2566863101 "False";
BA_ "GenMsgInstanced" BO_ 2566863102 "False";
BA_ "GenMsgInstanced" BO_ 2566863103 "False";
BA_ "GenMsgInstanced" BO_ 2566865141 "False";
BA_ "GenMsgInstanced" BO_ 2566865397 "False";
BA_ "GenMsgInstanced" BO_ 2566866165 "False";
BA_ "GenMsgInstanced" BO_ 2566866422 "False";
BA_ "GenMsgInstanced" BO_ 2566866423 "False";
BA_ "GenMsgInstanced" BO_ 2566866424 "False";
BA_ "GenMsgInstanced" BO_ 2566866425 "False";
BA_ "GenMsgInstanced" BO_ 2566866426 "False";
BA_ "GenMsgInstanced" BO_ 2566866427 "False";
BA_ "GenMsgInstanced" BO_ 2566866428 "False";
BA_ "GenMsgInstanced" BO_ 2566866429 "False";
BA_ "GenMsgInstanced" BO_ 2566866430 "False";
BA_ "GenMsgInstanced" BO_ 2566866431 "False";
BA_ "GenMsgInstanced" BO_ 2566866677 "False";
BA_ "GenMsgInstanced" BO_ 2566866678 "False";
BA_ "GenMsgInstanced" BO_ 2566866679 "False";
BA_ "GenMsgInstanced" BO_ 2566866680 "False";
BA_ "GenMsgInstanced" BO_ 2566866681 "False";
BA_ "GenMsgInstanced" BO_ 2566866682 "False";
BA_ "GenMsgInstanced" BO_ 2566866683 "False";
BA_ "GenMsgInstanced" BO_ 2566866684 "False";
BA_ "GenMsgInstanced" BO_ 2566866685 "False";
BA_ "GenMsgInstanced" BO_ 2566866686 "False";
BA_ "GenMsgInstanced" BO_ 2566866687 "False";
BA_ "GenMsgInstanced" BO_ 2566867189 "False";
BA_ "GenMsgInstanced" BO_ 2566867445 "False";
BA_ "GenMsgInstanced" BO_ 2566867701 "False";
BA_ "GenMsgInstanced" BO_ 2566869493 "False";
BA_ "GenMsgInstanced" BO_ 2566870005 "False";
BA_ "GenMsgInstanced" BO_ 2566870517 "False";
BA_ "GenMsgInstanced" BO_ 2566870774 "False";
BA_ "GenMsgInstanced" BO_ 2566870775 "False";
BA_ "GenMsgInstanced" BO_ 2566870776 "False";
BA_ "GenMsgInstanced" BO_ 2566870777 "False";
BA_ "GenMsgInstanced" BO_ 2566870778 "False";
BA_ "GenMsgInstanced" BO_ 2566870779 "False";
BA_ "GenMsgInstanced" BO_ 2566870780 "False";
BA_ "GenMsgInstanced" BO_ 2566870781 "False";
BA_ "GenMsgInstanced" BO_ 2566870782 "False";
BA_ "GenMsgInstanced" BO_ 2566870783 "False";
BA_ "GenMsgInstanced" BO_ 2566871285 "False";
BA_ "GenMsgInstanced" BO_ 2566871376 "False";
BA_ "GenMsgInstanced" BO_ 2566872821 "False";
BA_ "GenMsgInstanced" BO_ 2566873333 "False";
BA_ "GenMsgInstanced" BO_ 2566874870 "False";
BA_ "GenMsgInstanced" BO_ 2566874871 "False";
BA_ "GenMsgInstanced" BO_ 2566874872 "False";
BA_ "GenMsgInstanced" BO_ 2566874873 "False";
BA_ "GenMsgInstanced" BO_ 2566874874 "False";
BA_ "GenMsgInstanced" BO_ 2566874875 "False";
BA_ "GenMsgInstanced" BO_ 2566874876 "False";
BA_ "GenMsgInstanced" BO_ 2566874877 "False";
BA_ "GenMsgInstanced" BO_ 2566874878 "False";
BA_ "GenMsgInstanced" BO_ 2566874879 "False";
BA_ "GenMsgInstanced" BO_ 2566878966 "False";
BA_ "GenMsgInstanced" BO_ 2566878967 "False";
BA_ "GenMsgInstanced" BO_ 2566878968 "False";
BA_ "GenMsgInstanced" BO_ 2566878969 "False";
BA_ "GenMsgInstanced" BO_ 2566878970 "False";
BA_ "GenMsgInstanced" BO_ 2566878971 "False";
BA_ "GenMsgInstanced" BO_ 2566878972 "False";
BA_ "GenMsgInstanced" BO_ 2566878973 "False";
BA_ "GenMsgInstanced" BO_ 2566878974 "False";
BA_ "GenMsgInstanced" BO_ 2566878975 "False";
BA_ "GenMsgInstanced" BO_ 2566879265 "False";
BA_ "GenMsgInstanced" BO_ 2566881313 "False";
BA_ "GenMsgInstanced" BO_ 2566881525 "False";
BA_ "GenMsgInstanced" BO_ 2566883062 "False";
BA_ "GenMsgInstanced" BO_ 2566883063 "False";
BA_ "GenMsgInstanced" BO_ 2566883064 "False";
BA_ "GenMsgInstanced" BO_ 2566883065 "False";
BA_ "GenMsgInstanced" BO_ 2566883066 "False";
BA_ "GenMsgInstanced" BO_ 2566883067 "False";
BA_ "GenMsgInstanced" BO_ 2566883068 "False";
BA_ "GenMsgInstanced" BO_ 2566883069 "False";
BA_ "GenMsgInstanced" BO_ 2566883070 "False";
BA_ "GenMsgInstanced" BO_ 2566883071 "False";
BA_ "GenMsgInstanced" BO_ 2566885622 "False";
BA_ "GenMsgInstanced" BO_ 2566885623 "False";
BA_ "GenMsgInstanced" BO_ 2566885624 "False";
BA_ "GenMsgInstanced" BO_ 2566885625 "False";
BA_ "GenMsgInstanced" BO_ 2566885626 "False";
BA_ "GenMsgInstanced" BO_ 2566885627 "False";
BA_ "GenMsgInstanced" BO_ 2566885628 "False";
BA_ "GenMsgInstanced" BO_ 2566885629 "False";
BA_ "GenMsgInstanced" BO_ 2566885630 "False";
BA_ "GenMsgInstanced" BO_ 2566885631 "False";
BA_ "GenMsgInstanced" BO_ 2566889718 "False";
BA_ "GenMsgInstanced" BO_ 2566889719 "False";
BA_ "GenMsgInstanced" BO_ 2566889720 "False";
BA_ "GenMsgInstanced" BO_ 2566889721 "False";
BA_ "GenMsgInstanced" BO_ 2566889722 "False";
BA_ "GenMsgInstanced" BO_ 2566889723 "False";
BA_ "GenMsgInstanced" BO_ 2566889724 "False";
BA_ "GenMsgInstanced" BO_ 2566889725 "False";
BA_ "GenMsgInstanced" BO_ 2566889726 "False";
BA_ "GenMsgInstanced" BO_ 2566889727 "False";
BA_ "GenMsgInstanced" BO_ 2566893814 "False";
BA_ "GenMsgInstanced" BO_ 2566893815 "False";
BA_ "GenMsgInstanced" BO_ 2566893816 "False";
BA_ "GenMsgInstanced" BO_ 2566893817 "False";
BA_ "GenMsgInstanced" BO_ 2566893818 "False";
BA_ "GenMsgInstanced" BO_ 2566893819 "False";
BA_ "GenMsgInstanced" BO_ 2566893820 "False";
BA_ "GenMsgInstanced" BO_ 2566893821 "False";
BA_ "GenMsgInstanced" BO_ 2566893822 "False";
BA_ "GenMsgInstanced" BO_ 2566893823 "False";
BA_ "GenMsgInstanced" BO_ 2566897910 "False";
BA_ "GenMsgInstanced" BO_ 2566897911 "False";
BA_ "GenMsgInstanced" BO_ 2566897912 "False";
BA_ "GenMsgInstanced" BO_ 2566897913 "False";
BA_ "GenMsgInstanced" BO_ 2566897914 "False";
BA_ "GenMsgInstanced" BO_ 2566897915 "False";
BA_ "GenMsgInstanced" BO_ 2566897916 "False";
BA_ "GenMsgInstanced" BO_ 2566897917 "False";
BA_ "GenMsgInstanced" BO_ 2566897918 "False";
BA_ "GenMsgInstanced" BO_ 2566897919 "False";
BA_ "GenMsgInstanced" BO_ 2566902006 "False";
BA_ "GenMsgInstanced" BO_ 2566902007 "False";
BA_ "GenMsgInstanced" BO_ 2566902008 "False";
BA_ "GenMsgInstanced" BO_ 2566902009 "False";
BA_ "GenMsgInstanced" BO_ 2566902010 "False";
BA_ "GenMsgInstanced" BO_ 2566902011 "False";
BA_ "GenMsgInstanced" BO_ 2566902012 "False";
BA_ "GenMsgInstanced" BO_ 2566902013 "False";
BA_ "GenMsgInstanced" BO_ 2566902014 "False";
BA_ "GenMsgInstanced" BO_ 2566902015 "False";
BA_ "GenMsgInstanced" BO_ 2566906102 "False";
BA_ "GenMsgInstanced" BO_ 2566906103 "False";
BA_ "GenMsgInstanced" BO_ 2566906104 "False";
BA_ "GenMsgInstanced" BO_ 2566906105 "False";
BA_ "GenMsgInstanced" BO_ 2566906106 "False";
BA_ "GenMsgInstanced" BO_ 2566906107 "False";
BA_ "GenMsgInstanced" BO_ 2566906108 "False";
BA_ "GenMsgInstanced" BO_ 2566906109 "False";
BA_ "GenMsgInstanced" BO_ 2566906110 "False";
BA_ "GenMsgInstanced" BO_ 2566906111 "False";
BA_ "GenMsgCycleTime" BO_ 2566866422 100;
BA_ "GenMsgCycleTime" BO_ 2566866423 100;
BA_ "GenMsgCycleTime" BO_ 2566866424 100;
BA_ "GenMsgCycleTime" BO_ 2566866425 100;
BA_ "GenMsgCycleTime" BO_ 2566866426 100;
BA_ "GenMsgCycleTime" BO_ 2566866427 100;
BA_ "GenMsgCycleTime" BO_ 2566866428 100;
BA_ "GenMsgCycleTime" BO_ 2566866429 100;
BA_ "GenMsgCycleTime" BO_ 2566866430 100;
BA_ "GenMsgCycleTime" BO_ 2566866431 100;
BA_ "GenMsgCycleTime" BO_ 2566871376 1000;
BA_ "GenMsgCycleTime" BO_ 2566874870 100;
BA_ "GenMsgCycleTime" BO_ 2566874871 100;
BA_ "GenMsgCycleTime" BO_ 2566874872 100;
BA_ "GenMsgCycleTime" BO_ 2566874873 100;
BA_ "GenMsgCycleTime" BO_ 2566874874 100;
BA_ "GenMsgCycleTime" BO_ 2566874875 100;
BA_ "GenMsgCycleTime" BO_ 2566874876 100;
BA_ "GenMsgCycleTime" BO_ 2566874877 100;
BA_ "GenMsgCycleTime" BO_ 2566874878 100;
BA_ "GenMsgCycleTime" BO_ 2566874879 100;
BA_ "GenMsgCycleTime" BO_ 2566879265 1000;
BA_ "GenMsgCycleTime" BO_ 2566885622 100;
BA_ "GenMsgCycleTime" BO_ 2566885623 100;
BA_ "GenMsgCycleTime" BO_ 2566885624 100;
BA_ "GenMsgCycleTime" BO_ 2566885625 100;
BA_ "GenMsgCycleTime" BO_ 2566885626 100;
BA_ "GenMsgCycleTime" BO_ 2566885627 100;
BA_ "GenMsgCycleTime" BO_ 2566885628 100;
BA_ "GenMsgCycleTime" BO_ 2566885629 100;
BA_ "GenMsgCycleTime" BO_ 2566885630 100;
BA_ "GenMsgCycleTime" BO_ 2566885631 100;
BA_ "GenMsgCycleTime" BO_ 2566889718 100;
BA_ "GenMsgCycleTime" BO_ 2566889719 100;
BA_ "GenMsgCycleTime" BO_ 2566889720 100;
BA_ "GenMsgCycleTime" BO_ 2566889721 100;
BA_ "GenMsgCycleTime" BO_ 2566889722 100;
BA_ "GenMsgCycleTime" BO_ 2566889723 100;
BA_ "GenMsgCycleTime" BO_ 2566889724 100;
BA_ "GenMsgCycleTime" BO_ 2566889725 100;
BA_ "GenMsgCycleTime" BO_ 2566889726 100;
BA_ "GenMsgCycleTime" BO_ 2566889727 100;
BA_ "GenMsgCycleTime" BO_ 2566893814 100;
BA_ "GenMsgCycleTime" BO_ 2566893815 100;
BA_ "GenMsgCycleTime" BO_ 2566893816 100;
BA_ "GenMsgCycleTime" BO_ 2566893817 100;
BA_ "GenMsgCycleTime" BO_ 2566893818 100;
BA_ "GenMsgCycleTime" BO_ 2566893819 100;
BA_ "GenMsgCycleTime" BO_ 2566893820 100;
BA_ "GenMsgCycleTime" BO_ 2566893821 100;
BA_ "GenMsgCycleTime" BO_ 2566893822 100;
BA_ "GenMsgCycleTime" BO_ 2566893823 100;
BA_ "GenMsgCycleTime" BO_ 2566902006 1000;
BA_ "GenMsgCycleTime" BO_ 2566902007 1000;
BA_ "GenMsgCycleTime" BO_ 2566902008 1000;
BA_ "GenMsgCycleTime" BO_ 2566902009 1000;
BA_ "GenMsgCycleTime" BO_ 2566902010 1000;
BA_ "GenMsgCycleTime" BO_ 2566902011 1000;
BA_ "GenMsgCycleTime" BO_ 2566902012 1000;
BA_ "GenMsgCycleTime" BO_ 2566902013 1000;
BA_ "GenMsgCycleTime" BO_ 2566902014 1000;
BA_ "GenMsgCycleTime" BO_ 2566902015 1000;
BA_ "GenMsgCycleTime" BO_ 2566906102 100;
BA_ "GenMsgCycleTime" BO_ 2566906103 100;
BA_ "GenMsgCycleTime" BO_ 2566906104 100;
BA_ "GenMsgCycleTime" BO_ 2566906105 100;
BA_ "GenMsgCycleTime" BO_ 2566906106 100;
BA_ "GenMsgCycleTime" BO_ 2566906107 100;
BA_ "GenMsgCycleTime" BO_ 2566906108 100;
BA_ "GenMsgCycleTime" BO_ 2566906109 100;
BA_ "GenMsgCycleTime" BO_ 2566906110 100;
BA_ "GenMsgCycleTime" BO_ 2566906111 100;
BA_ "GenSigType" SG_ 2566862841 BATT_vBrick14_3 1;
BA_ "GenSigType" SG_ 2566862841 BATT_vBrick13_3 1;
BA_ "GenSigType" SG_ 2566862842 BATT_vBrick13_4 1;
BA_ "GenSigType" SG_ 2566862842 BATT_vBrick14_4 1;
BA_ "GenSigType" SG_ 2566862843 BATT_vBrick14_5 1;
BA_ "GenSigType" SG_ 2566862843 BATT_vBrick13_5 1;
BA_ "GenSigType" SG_ 2566862844 BATT_vBrick14_6 1;
BA_ "GenSigType" SG_ 2566862844 BATT_vBrick13_6 1;
BA_ "GenSigType" SG_ 2566862845 BATT_vBrick13_7 1;
BA_ "GenSigType" SG_ 2566862845 BATT_vBrick14_7 1;
BA_ "GenSigType" SG_ 2566862846 BATT_vBrick13_8 1;
BA_ "GenSigType" SG_ 2566862846 BATT_vBrick14_8 1;
BA_ "GenSigType" SG_ 2566862847 BATT_vBrick14_9 1;
BA_ "GenSigType" SG_ 2566862847 BATT_vBrick13_9 1;
BA_ "GenSigType" SG_ 2566865397 BATT_iPackFiltered 0;
BA_ "GenSigType" SG_ 2566865397 BATT_vPackLoad 0;
BA_ "GenSigType" SG_ 2566866165 BATT_tPackModuleMin 1;
BA_ "GenSigType" SG_ 2566866165 BATT_tPackModuleMax 1;
BA_ "GenSigType" SG_ 2566866422 BATT_sohcMod_0 0;
BA_ "GenSigType" SG_ 2566866422 BATT_socMod_0 0;
BA_ "GenSigType" SG_ 2566866422 BATT_socLimiting_0 0;
BA_ "GenSigType" SG_ 2566866422 BATT_idSOCLimiting_0 0;
BA_ "GenSigType" SG_ 2566866423 BATT_sohcMod_1 0;
BA_ "GenSigType" SG_ 2566866423 BATT_socMod_1 0;
BA_ "GenSigType" SG_ 2566866423 BATT_socLimiting_1 0;
BA_ "GenSigType" SG_ 2566866423 BATT_idSOCLimiting_1 0;
BA_ "GenSigType" SG_ 2566866424 BATT_sohcMod_2 0;
BA_ "GenSigType" SG_ 2566866424 BATT_socMod_2 0;
BA_ "GenSigType" SG_ 2566866424 BATT_socLimiting_2 0;
BA_ "GenSigType" SG_ 2566866424 BATT_idSOCLimiting_2 0;
BA_ "GenSigType" SG_ 2566866425 BATT_sohcMod_3 0;
BA_ "GenSigType" SG_ 2566866425 BATT_socMod_3 0;
BA_ "GenSigType" SG_ 2566866425 BATT_socLimiting_3 0;
BA_ "GenSigType" SG_ 2566866425 BATT_idSOCLimiting_3 0;
BA_ "GenSigType" SG_ 2566866426 BATT_sohcMod_4 0;
BA_ "GenSigType" SG_ 2566866426 BATT_socMod_4 0;
BA_ "GenSigType" SG_ 2566866426 BATT_socLimiting_4 0;
BA_ "GenSigType" SG_ 2566866426 BATT_idSOCLimiting_4 0;
BA_ "GenSigType" SG_ 2566866427 BATT_sohcMod_5 0;
BA_ "GenSigType" SG_ 2566866427 BATT_socMod_5 0;
BA_ "GenSigType" SG_ 2566866427 BATT_socLimiting_5 0;
BA_ "GenSigType" SG_ 2566866427 BATT_idSOCLimiting_5 0;
BA_ "GenSigType" SG_ 2566866428 BATT_sohcMod_6 0;
BA_ "GenSigType" SG_ 2566866428 BATT_socMod_6 0;
BA_ "GenSigType" SG_ 2566866428 BATT_socLimiting_6 0;
BA_ "GenSigType" SG_ 2566866428 BATT_idSOCLimiting_6 0;
BA_ "GenSigType" SG_ 2566866429 BATT_sohcMod_7 0;
BA_ "GenSigType" SG_ 2566866429 BATT_socMod_7 0;
BA_ "GenSigType" SG_ 2566866429 BATT_socLimiting_7 0;
BA_ "GenSigType" SG_ 2566866429 BATT_idSOCLimiting_7 0;
BA_ "GenSigType" SG_ 2566866430 BATT_sohcMod_8 0;
BA_ "GenSigType" SG_ 2566866430 BATT_socMod_8 0;
BA_ "GenSigType" SG_ 2566866430 BATT_socLimiting_8 0;
BA_ "GenSigType" SG_ 2566866430 BATT_idSOCLimiting_8 0;
BA_ "GenSigType" SG_ 2566866431 BATT_sohcMod_9 0;
BA_ "GenSigType" SG_ 2566866431 BATT_socMod_9 0;
BA_ "GenSigType" SG_ 2566866431 BATT_socLimiting_9 0;
BA_ "GenSigType" SG_ 2566866431 BATT_idSOCLimiting_9 0;
BA_ "GenSigType" SG_ 2566867445 BATT_chargeError 0;
BA_ "GenSigType" SG_ 2566867445 BATT_chargeStatus 0;
BA_ "GenSigType" SG_ 2566867445 BATT_chargeMode 0;
BA_ "GenSigType" SG_ 2566867445 BATT_chargerMode 0;
BA_ "GenSigType" SG_ 2566867445 BATT_chargeEnable 0;
BA_ "GenSigType" SG_ 2566867701 BATT_fetPackChgWelded 0;
BA_ "GenSigType" SG_ 2566867701 BATT_fetPackDsgWelded 0;
BA_ "GenSigType" SG_ 2566867701 BATT_packState 0;
BA_ "GenSigType" SG_ 2566870774 BATT_vBrick02_0 1;
BA_ "GenSigType" SG_ 2566870774 BATT_vBrick03_0 1;
BA_ "GenSigType" SG_ 2566870774 BATT_vBrick01_0 1;
BA_ "GenSigType" SG_ 2566870774 BATT_vBrick04_0 1;
BA_ "GenSigType" SG_ 2566870775 BATT_vBrick02_1 1;
BA_ "GenSigType" SG_ 2566870775 BATT_vBrick03_1 1;
BA_ "GenSigType" SG_ 2566870775 BATT_vBrick01_1 1;
BA_ "GenSigType" SG_ 2566870775 BATT_vBrick04_1 1;
BA_ "GenSigType" SG_ 2566870776 BATT_vBrick02_2 1;
BA_ "GenSigType" SG_ 2566870776 BATT_vBrick03_2 1;
BA_ "GenSigType" SG_ 2566870776 BATT_vBrick01_2 1;
BA_ "GenSigType" SG_ 2566870776 BATT_vBrick04_2 1;
BA_ "GenSigType" SG_ 2566870777 BATT_vBrick02_3 1;
BA_ "GenSigType" SG_ 2566870777 BATT_vBrick03_3 1;
BA_ "GenSigType" SG_ 2566870777 BATT_vBrick01_3 1;
BA_ "GenSigType" SG_ 2566870777 BATT_vBrick04_3 1;
BA_ "GenSigType" SG_ 2566870778 BATT_vBrick02_4 1;
BA_ "GenSigType" SG_ 2566870778 BATT_vBrick03_4 1;
BA_ "GenSigType" SG_ 2566870778 BATT_vBrick01_4 1;
BA_ "GenSigType" SG_ 2566870778 BATT_vBrick04_4 1;
BA_ "GenSigType" SG_ 2566870779 BATT_vBrick02_5 1;
BA_ "GenSigType" SG_ 2566870779 BATT_vBrick03_5 1;
BA_ "GenSigType" SG_ 2566870779 BATT_vBrick01_5 1;
BA_ "GenSigType" SG_ 2566870779 BATT_vBrick04_5 1;
BA_ "GenSigType" SG_ 2566870780 BATT_vBrick02_6 1;
BA_ "GenSigType" SG_ 2566870780 BATT_vBrick03_6 1;
BA_ "GenSigType" SG_ 2566870780 BATT_vBrick01_6 1;
BA_ "GenSigType" SG_ 2566870780 BATT_vBrick04_6 1;
BA_ "GenSigType" SG_ 2566870781 BATT_vBrick02_7 1;
BA_ "GenSigType" SG_ 2566870781 BATT_vBrick03_7 1;
BA_ "GenSigType" SG_ 2566870781 BATT_vBrick01_7 1;
BA_ "GenSigType" SG_ 2566870781 BATT_vBrick04_7 1;
BA_ "GenSigType" SG_ 2566870782 BATT_vBrick02_8 1;
BA_ "GenSigType" SG_ 2566870782 BATT_vBrick03_8 1;
BA_ "GenSigType" SG_ 2566870782 BATT_vBrick01_8 1;
BA_ "GenSigType" SG_ 2566870782 BATT_vBrick04_8 1;
BA_ "GenSigType" SG_ 2566870783 BATT_vBrick02_9 1;
BA_ "GenSigType" SG_ 2566870783 BATT_vBrick03_9 1;
BA_ "GenSigType" SG_ 2566870783 BATT_vBrick01_9 1;
BA_ "GenSigType" SG_ 2566870783 BATT_vBrick04_9 1;
BA_ "GenSigType" SG_ 2566871376 CHRG_chargingCurrent 0;
BA_ "GenSigType" SG_ 2566871376 CHRG_chargerEnabled 0;
BA_ "GenSigType" SG_ 2566871376 CHRG_chargingVoltage 0;
BA_ "GenSigType" SG_ 2566874870 BATT_IGNLO_Status_0 1;
BA_ "GenSigType" SG_ 2566874871 BATT_IGNLO_Status_1 1;
BA_ "GenSigType" SG_ 2566874872 BATT_IGNLO_Status_2 1;
BA_ "GenSigType" SG_ 2566874873 BATT_IGNLO_Status_3 1;
BA_ "GenSigType" SG_ 2566874874 BATT_IGNLO_Status_4 1;
BA_ "GenSigType" SG_ 2566874875 BATT_IGNLO_Status_5 1;
BA_ "GenSigType" SG_ 2566874876 BATT_IGNLO_Status_6 1;
BA_ "GenSigType" SG_ 2566874877 BATT_IGNLO_Status_7 1;
BA_ "GenSigType" SG_ 2566874878 BATT_IGNLO_Status_8 1;
BA_ "GenSigType" SG_ 2566874879 BATT_IGNLO_Status_9 1;
BA_ "GenSigType" SG_ 2566878966 BATT_ahChgTotal_0 1;
BA_ "GenSigType" SG_ 2566878966 BATT_ahDchTotal_0 1;
BA_ "GenSigType" SG_ 2566878967 BATT_ahChgTotal_1 1;
BA_ "GenSigType" SG_ 2566878967 BATT_ahDchTotal_1 1;
BA_ "GenSigType" SG_ 2566878968 BATT_ahDchTotal_2 1;
BA_ "GenSigType" SG_ 2566878968 BATT_ahChgTotal_2 1;
BA_ "GenSigType" SG_ 2566878969 BATT_ahChgTotal_3 1;
BA_ "GenSigType" SG_ 2566878969 BATT_ahDchTotal_3 1;
BA_ "GenSigType" SG_ 2566878970 BATT_ahChgTotal_4 1;
BA_ "GenSigType" SG_ 2566878970 BATT_ahDchTotal_4 1;
BA_ "GenSigType" SG_ 2566878971 BATT_ahDchTotal_5 1;
BA_ "GenSigType" SG_ 2566878971 BATT_ahChgTotal_5 1;
BA_ "GenSigType" SG_ 2566878972 BATT_ahDchTotal_6 1;
BA_ "GenSigType" SG_ 2566878972 BATT_ahChgTotal_6 1;
BA_ "GenSigType" SG_ 2566878973 BATT_ahDchTotal_7 1;
BA_ "GenSigType" SG_ 2566878973 BATT_ahChgTotal_7 1;
BA_ "GenSigType" SG_ 2566878974 BATT_ahDchTotal_8 1;
BA_ "GenSigType" SG_ 2566878974 BATT_ahChgTotal_8 1;
BA_ "GenSigType" SG_ 2566878975 BATT_ahDchTotal_9 1;
BA_ "GenSigType" SG_ 2566878975 BATT_ahChgTotal_9 1;
BA_ "GenSigType" SG_ 2566879265 HOST_dbgInhibitFullPower 0;
BA_ "GenSigType" SG_ 2566879265 HOST_dbgInhibitRegen 0;
BA_ "GenSigType" SG_ 2566879265 HOST_stateRequest 0;
BA_ "GenSigType" SG_ 2566879265 HOST_dbgInhibitContDrivePower 0;
BA_ "GenSigType" SG_ 2566879265 HOST_dbgResetEep 0;
BA_ "GenSigType" SG_ 2566879265 HOST_standbyModConnectRequest 0;
BA_ "GenSigType" SG_ 2566881313 HOST_securityKey 0;
BA_ "GenSigType" SG_ 2566881313 HOST_startNodeId 0;
BA_ "GenSigType" SG_ 2566883062 BATT_capBrick04_0 1;
BA_ "GenSigType" SG_ 2566883062 BATT_capBrick03_0 1;
BA_ "GenSigType" SG_ 2566883062 BATT_capBrick02_0 1;
BA_ "GenSigType" SG_ 2566883062 BATT_capBrick01_0 1;
BA_ "GenSigType" SG_ 2566883063 BATT_capBrick04_1 1;
BA_ "GenSigType" SG_ 2566883063 BATT_capBrick03_1 1;
BA_ "GenSigType" SG_ 2566883063 BATT_capBrick02_1 1;
BA_ "GenSigType" SG_ 2566883063 BATT_capBrick01_1 1;
BA_ "GenSigType" SG_ 2566883064 BATT_capBrick04_2 1;
BA_ "GenSigType" SG_ 2566883064 BATT_capBrick03_2 1;
BA_ "GenSigType" SG_ 2566883064 BATT_capBrick02_2 1;
BA_ "GenSigType" SG_ 2566883064 BATT_capBrick01_2 1;
BA_ "GenSigType" SG_ 2566883065 BATT_capBrick04_3 1;
BA_ "GenSigType" SG_ 2566883065 BATT_capBrick03_3 1;
BA_ "GenSigType" SG_ 2566883065 BATT_capBrick02_3 1;
BA_ "GenSigType" SG_ 2566883065 BATT_capBrick01_3 1;
BA_ "GenSigType" SG_ 2566883066 BATT_capBrick04_4 1;
BA_ "GenSigType" SG_ 2566883066 BATT_capBrick03_4 1;
BA_ "GenSigType" SG_ 2566883066 BATT_capBrick02_4 1;
BA_ "GenSigType" SG_ 2566883066 BATT_capBrick01_4 1;
BA_ "GenSigType" SG_ 2566883067 BATT_capBrick04_5 1;
BA_ "GenSigType" SG_ 2566883067 BATT_capBrick03_5 1;
BA_ "GenSigType" SG_ 2566883067 BATT_capBrick02_5 1;
BA_ "GenSigType" SG_ 2566883067 BATT_capBrick01_5 1;
BA_ "GenSigType" SG_ 2566883068 BATT_capBrick04_6 1;
BA_ "GenSigType" SG_ 2566883068 BATT_capBrick03_6 1;
BA_ "GenSigType" SG_ 2566883068 BATT_capBrick02_6 1;
BA_ "GenSigType" SG_ 2566883068 BATT_capBrick01_6 1;
BA_ "GenSigType" SG_ 2566883069 BATT_capBrick04_7 1;
BA_ "GenSigType" SG_ 2566883069 BATT_capBrick03_7 1;
BA_ "GenSigType" SG_ 2566883069 BATT_capBrick02_7 1;
BA_ "GenSigType" SG_ 2566883069 BATT_capBrick01_7 1;
BA_ "GenSigType" SG_ 2566883070 BATT_capBrick04_8 1;
BA_ "GenSigType" SG_ 2566883070 BATT_capBrick03_8 1;
BA_ "GenSigType" SG_ 2566883070 BATT_capBrick02_8 1;
BA_ "GenSigType" SG_ 2566883070 BATT_capBrick01_8 1;
BA_ "GenSigType" SG_ 2566883071 BATT_capBrick04_9 1;
BA_ "GenSigType" SG_ 2566883071 BATT_capBrick03_9 1;
BA_ "GenSigType" SG_ 2566883071 BATT_capBrick02_9 1;
BA_ "GenSigType" SG_ 2566883071 BATT_capBrick01_9 1;
BA_ "GenSigType" SG_ 2566885622 BATT_resMod_0 0;
BA_ "GenSigType" SG_ 2566885622 BATT_voirMod_0 0;
BA_ "GenSigType" SG_ 2566885622 BATT_vModLoad_0 0;
BA_ "GenSigType" SG_ 2566885623 BATT_resMod_1 0;
BA_ "GenSigType" SG_ 2566885623 BATT_voirMod_1 0;
BA_ "GenSigType" SG_ 2566885623 BATT_vModLoad_1 0;
BA_ "GenSigType" SG_ 2566885624 BATT_resMod_2 0;
BA_ "GenSigType" SG_ 2566885624 BATT_voirMod_2 0;
BA_ "GenSigType" SG_ 2566885624 BATT_vModLoad_2 0;
BA_ "GenSigType" SG_ 2566885625 BATT_resMod_3 0;
BA_ "GenSigType" SG_ 2566885625 BATT_voirMod_3 0;
BA_ "GenSigType" SG_ 2566885625 BATT_vModLoad_3 0;
BA_ "GenSigType" SG_ 2566885626 BATT_resMod_4 0;
BA_ "GenSigType" SG_ 2566885626 BATT_voirMod_4 0;
BA_ "GenSigType" SG_ 2566885626 BATT_vModLoad_4 0;
BA_ "GenSigType" SG_ 2566885627 BATT_resMod_5 0;
BA_ "GenSigType" SG_ 2566885627 BATT_voirMod_5 0;
BA_ "GenSigType" SG_ 2566885627 BATT_vModLoad_5 0;
BA_ "GenSigType" SG_ 2566885628 BATT_resMod_6 0;
BA_ "GenSigType" SG_ 2566885628 BATT_voirMod_6 0;
BA_ "GenSigType" SG_ 2566885628 BATT_vModLoad_6 0;
BA_ "GenSigType" SG_ 2566885629 BATT_resMod_7 0;
BA_ "GenSigType" SG_ 2566885629 BATT_voirMod_7 0;
BA_ "GenSigType" SG_ 2566885629 BATT_vModLoad_7 0;
BA_ "GenSigType" SG_ 2566885630 BATT_resMod_8 0;
BA_ "GenSigType" SG_ 2566885630 BATT_voirMod_8 0;
BA_ "GenSigType" SG_ 2566885630 BATT_vModLoad_8 0;
BA_ "GenSigType" SG_ 2566885631 BATT_resMod_9 0;
BA_ "GenSigType" SG_ 2566885631 BATT_voirMod_9 0;
BA_ "GenSigType" SG_ 2566885631 BATT_vModLoad_9 0;
BA_ "GenSigType" SG_ 2566889718 BATT_tModuleMin_0 0;
BA_ "GenSigType" SG_ 2566889718 BATT_vBrickMinID_0 0;
BA_ "GenSigType" SG_ 2566889718 BATT_tModuleMaxID_0 0;
BA_ "GenSigType" SG_ 2566889718 BATT_vBrickMin_0 0;
BA_ "GenSigType" SG_ 2566889718 BATT_tModuleMinID_0 0;
BA_ "GenSigType" SG_ 2566889718 BATT_vBrickMaxID_0 0;
BA_ "GenSigType" SG_ 2566889718 BATT_tModuleMax_0 0;
BA_ "GenSigType" SG_ 2566889718 BATT_vBrickMax_0 0;
BA_ "GenSigType" SG_ 2566889719 BATT_vBrickMax_1 0;
BA_ "GenSigType" SG_ 2566889719 BATT_tModuleMinID_1 0;
BA_ "GenSigType" SG_ 2566889719 BATT_tModuleMin_1 0;
BA_ "GenSigType" SG_ 2566889719 BATT_vBrickMaxID_1 0;
BA_ "GenSigType" SG_ 2566889719 BATT_vBrickMin_1 0;
BA_ "GenSigType" SG_ 2566889719 BATT_tModuleMaxID_1 0;
BA_ "GenSigType" SG_ 2566889719 BATT_vBrickMinID_1 0;
BA_ "GenSigType" SG_ 2566889719 BATT_tModuleMax_1 0;
BA_ "GenSigType" SG_ 2566889720 BATT_vBrickMax_2 0;
BA_ "GenSigType" SG_ 2566889720 BATT_tModuleMin_2 0;
BA_ "GenSigType" SG_ 2566889720 BATT_vBrickMin_2 0;
BA_ "GenSigType" SG_ 2566889720 BATT_vBrickMinID_2 0;
BA_ "GenSigType" SG_ 2566889720 BATT_tModuleMax_2 0;
BA_ "GenSigType" SG_ 2566889720 BATT_tModuleMinID_2 0;
BA_ "GenSigType" SG_ 2566889720 BATT_vBrickMaxID_2 0;
BA_ "GenSigType" SG_ 2566889720 BATT_tModuleMaxID_2 0;
BA_ "GenSigType" SG_ 2566889721 BATT_tModuleMaxID_3 0;
BA_ "GenSigType" SG_ 2566889721 BATT_vBrickMaxID_3 0;
BA_ "GenSigType" SG_ 2566889721 BATT_tModuleMinID_3 0;
BA_ "GenSigType" SG_ 2566889721 BATT_vBrickMinID_3 0;
BA_ "GenSigType" SG_ 2566889721 BATT_tModuleMax_3 0;
BA_ "GenSigType" SG_ 2566889721 BATT_tModuleMin_3 0;
BA_ "GenSigType" SG_ 2566889721 BATT_vBrickMin_3 0;
BA_ "GenSigType" SG_ 2566889721 BATT_vBrickMax_3 0;
BA_ "GenSigType" SG_ 2566889722 BATT_tModuleMinID_4 0;
BA_ "GenSigType" SG_ 2566889722 BATT_tModuleMaxID_4 0;
BA_ "GenSigType" SG_ 2566889722 BATT_vBrickMin_4 0;
BA_ "GenSigType" SG_ 2566889722 BATT_vBrickMax_4 0;
BA_ "GenSigType" SG_ 2566889722 BATT_tModuleMax_4 0;
BA_ "GenSigType" SG_ 2566889722 BATT_tModuleMin_4 0;
BA_ "GenSigType" SG_ 2566889722 BATT_vBrickMinID_4 0;
BA_ "GenSigType" SG_ 2566889722 BATT_vBrickMaxID_4 0;
BA_ "GenSigType" SG_ 2566889723 BATT_vBrickMax_5 0;
BA_ "GenSigType" SG_ 2566889723 BATT_vBrickMin_5 0;
BA_ "GenSigType" SG_ 2566889723 BATT_tModuleMin_5 0;
BA_ "GenSigType" SG_ 2566889723 BATT_tModuleMaxID_5 0;
BA_ "GenSigType" SG_ 2566889723 BATT_tModuleMinID_5 0;
BA_ "GenSigType" SG_ 2566889723 BATT_vBrickMaxID_5 0;
BA_ "GenSigType" SG_ 2566889723 BATT_vBrickMinID_5 0;
BA_ "GenSigType" SG_ 2566889723 BATT_tModuleMax_5 0;
BA_ "GenSigType" SG_ 2566889724 BATT_tModuleMax_6 0;
BA_ "GenSigType" SG_ 2566889724 BATT_vBrickMinID_6 0;
BA_ "GenSigType" SG_ 2566889724 BATT_tModuleMinID_6 0;
BA_ "GenSigType" SG_ 2566889724 BATT_vBrickMaxID_6 0;
BA_ "GenSigType" SG_ 2566889724 BATT_vBrickMax_6 0;
BA_ "GenSigType" SG_ 2566889724 BATT_tModuleMaxID_6 0;
BA_ "GenSigType" SG_ 2566889724 BATT_tModuleMin_6 0;
BA_ "GenSigType" SG_ 2566889724 BATT_vBrickMin_6 0;
BA_ "GenSigType" SG_ 2566889725 BATT_tModuleMax_7 0;
BA_ "GenSigType" SG_ 2566889725 BATT_tModuleMin_7 0;
BA_ "GenSigType" SG_ 2566889725 BATT_tModuleMinID_7 0;
BA_ "GenSigType" SG_ 2566889725 BATT_vBrickMaxID_7 0;
BA_ "GenSigType" SG_ 2566889725 BATT_vBrickMax_7 0;
BA_ "GenSigType" SG_ 2566889725 BATT_vBrickMinID_7 0;
BA_ "GenSigType" SG_ 2566889725 BATT_vBrickMin_7 0;
BA_ "GenSigType" SG_ 2566889725 BATT_tModuleMaxID_7 0;
BA_ "GenSigType" SG_ 2566889726 BATT_tModuleMinID_8 0;
BA_ "GenSigType" SG_ 2566889726 BATT_tModuleMaxID_8 0;
BA_ "GenSigType" SG_ 2566889726 BATT_vBrickMaxID_8 0;
BA_ "GenSigType" SG_ 2566889726 BATT_vBrickMin_8 0;
BA_ "GenSigType" SG_ 2566889726 BATT_vBrickMax_8 0;
BA_ "GenSigType" SG_ 2566889726 BATT_tModuleMax_8 0;
BA_ "GenSigType" SG_ 2566889726 BATT_tModuleMin_8 0;
BA_ "GenSigType" SG_ 2566889726 BATT_vBrickMinID_8 0;
BA_ "GenSigType" SG_ 2566889727 BATT_vBrickMax_9 0;
BA_ "GenSigType" SG_ 2566889727 BATT_tModuleMin_9 0;
BA_ "GenSigType" SG_ 2566889727 BATT_vBrickMin_9 0;
BA_ "GenSigType" SG_ 2566889727 BATT_vBrickMinID_9 0;
BA_ "GenSigType" SG_ 2566889727 BATT_tModuleMax_9 0;
BA_ "GenSigType" SG_ 2566889727 BATT_tModuleMinID_9 0;
BA_ "GenSigType" SG_ 2566889727 BATT_vBrickMaxID_9 0;
BA_ "GenSigType" SG_ 2566889727 BATT_tModuleMaxID_9 0;
BA_ "GenSigType" SG_ 2566893814 BATT_pwrModChgLimit_0 0;
BA_ "GenSigType" SG_ 2566893814 BATT_pwrModDchLimit_0 0;
BA_ "GenSigType" SG_ 2566893815 BATT_pwrModChgLimit_1 0;
BA_ "GenSigType" SG_ 2566893815 BATT_pwrModDchLimit_1 0;
BA_ "GenSigType" SG_ 2566893816 BATT_pwrModChgLimit_2 0;
BA_ "GenSigType" SG_ 2566893816 BATT_pwrModDchLimit_2 0;
BA_ "GenSigType" SG_ 2566893817 BATT_pwrModDchLimit_3 0;
BA_ "GenSigType" SG_ 2566893817 BATT_pwrModChgLimit_3 0;
BA_ "GenSigType" SG_ 2566893818 BATT_pwrModChgLimit_4 0;
BA_ "GenSigType" SG_ 2566893818 BATT_pwrModDchLimit_4 0;
BA_ "GenSigType" SG_ 2566893819 BATT_pwrModChgLimit_5 0;
BA_ "GenSigType" SG_ 2566893819 BATT_pwrModDchLimit_5 0;
BA_ "GenSigType" SG_ 2566893820 BATT_pwrModChgLimit_6 0;
BA_ "GenSigType" SG_ 2566893820 BATT_pwrModDchLimit_6 0;
BA_ "GenSigType" SG_ 2566893821 BATT_pwrModChgLimit_7 0;
BA_ "GenSigType" SG_ 2566893821 BATT_pwrModDchLimit_7 0;
BA_ "GenSigType" SG_ 2566893822 BATT_pwrModDchLimit_8 0;
BA_ "GenSigType" SG_ 2566893822 BATT_pwrModChgLimit_8 0;
BA_ "GenSigType" SG_ 2566893823 BATT_pwrModChgLimit_9 0;
BA_ "GenSigType" SG_ 2566893823 BATT_pwrModDchLimit_9 0;
BA_ "GenSigType" SG_ 2566906102 BATT_vModChgLimit_0 0;
BA_ "GenSigType" SG_ 2566906102 BATT_iModChgLimit30s_0 0;
BA_ "GenSigType" SG_ 2566906102 BATT_iModChgLimit10s_0 0;
BA_ "GenSigType" SG_ 2566906102 BATT_iModChgLimitCont_0 0;
BA_ "GenSigType" SG_ 2566906103 BATT_vModChgLimit_1 0;
BA_ "GenSigType" SG_ 2566906103 BATT_iModChgLimit30s_1 0;
BA_ "GenSigType" SG_ 2566906103 BATT_iModChgLimit10s_1 0;
BA_ "GenSigType" SG_ 2566906103 BATT_iModChgLimitCont_1 0;
BA_ "GenSigType" SG_ 2566906104 BATT_vModChgLimit_2 0;
BA_ "GenSigType" SG_ 2566906104 BATT_iModChgLimit30s_2 0;
BA_ "GenSigType" SG_ 2566906104 BATT_iModChgLimit10s_2 0;
BA_ "GenSigType" SG_ 2566906104 BATT_iModChgLimitCont_2 0;
BA_ "GenSigType" SG_ 2566906105 BATT_vModChgLimit_3 0;
BA_ "GenSigType" SG_ 2566906105 BATT_iModChgLimit30s_3 0;
BA_ "GenSigType" SG_ 2566906105 BATT_iModChgLimit10s_3 0;
BA_ "GenSigType" SG_ 2566906105 BATT_iModChgLimitCont_3 0;
BA_ "GenSigType" SG_ 2566906106 BATT_vModChgLimit_4 0;
BA_ "GenSigType" SG_ 2566906106 BATT_iModChgLimit30s_4 0;
BA_ "GenSigType" SG_ 2566906106 BATT_iModChgLimit10s_4 0;
BA_ "GenSigType" SG_ 2566906106 BATT_iModChgLimitCont_4 0;
BA_ "GenSigType" SG_ 2566906107 BATT_vModChgLimit_5 0;
BA_ "GenSigType" SG_ 2566906107 BATT_iModChgLimit30s_5 0;
BA_ "GenSigType" SG_ 2566906107 BATT_iModChgLimit10s_5 0;
BA_ "GenSigType" SG_ 2566906107 BATT_iModChgLimitCont_5 0;
BA_ "GenSigType" SG_ 2566906108 BATT_vModChgLimit_6 0;
BA_ "GenSigType" SG_ 2566906108 BATT_iModChgLimit30s_6 0;
BA_ "GenSigType" SG_ 2566906108 BATT_iModChgLimit10s_6 0;
BA_ "GenSigType" SG_ 2566906108 BATT_iModChgLimitCont_6 0;
BA_ "GenSigType" SG_ 2566906109 BATT_vModChgLimit_7 0;
BA_ "GenSigType" SG_ 2566906109 BATT_iModChgLimit30s_7 0;
BA_ "GenSigType" SG_ 2566906109 BATT_iModChgLimit10s_7 0;
BA_ "GenSigType" SG_ 2566906109 BATT_iModChgLimitCont_7 0;
BA_ "GenSigType" SG_ 2566906110 BATT_vModChgLimit_8 0;
BA_ "GenSigType" SG_ 2566906110 BATT_iModChgLimit30s_8 0;
BA_ "GenSigType" SG_ 2566906110 BATT_iModChgLimit10s_8 0;
BA_ "GenSigType" SG_ 2566906110 BATT_iModChgLimitCont_8 0;
BA_ "GenSigType" SG_ 2566906111 BATT_vModChgLimit_9 0;
BA_ "GenSigType" SG_ 2566906111 BATT_iModChgLimit30s_9 0;
BA_ "GenSigType" SG_ 2566906111 BATT_iModChgLimit10s_9 0;
BA_ "GenSigType" SG_ 2566906111 BATT_iModChgLimitCont_9 0;
BA_ "GenSigSNA" SG_ 2566862841 BATT_vBrick14_3 65535;
BA_ "GenSigSNA" SG_ 2566862841 BATT_vBrick13_3 65535;
BA_ "GenSigSNA" SG_ 2566862842 BATT_vBrick13_4 65535;
BA_ "GenSigSNA" SG_ 2566862842 BATT_vBrick14_4 65535;
BA_ "GenSigSNA" SG_ 2566862843 BATT_vBrick14_5 65535;
BA_ "GenSigSNA" SG_ 2566862843 BATT_vBrick13_5 65535;
BA_ "GenSigSNA" SG_ 2566862844 BATT_vBrick14_6 65535;
BA_ "GenSigSNA" SG_ 2566862844 BATT_vBrick13_6 65535;
BA_ "GenSigSNA" SG_ 2566862845 BATT_vBrick13_7 65535;
BA_ "GenSigSNA" SG_ 2566862845 BATT_vBrick14_7 65535;
BA_ "GenSigSNA" SG_ 2566862846 BATT_vBrick13_8 65535;
BA_ "GenSigSNA" SG_ 2566862846 BATT_vBrick14_8 65535;
BA_ "GenSigSNA" SG_ 2566862847 BATT_vBrick14_9 65535;
BA_ "GenSigSNA" SG_ 2566862847 BATT_vBrick13_9 65535;
BA_ "GenSigSNA" SG_ 2566865397 BATT_vPack 65535;
BA_ "GenSigSNA" SG_ 2566865397 BATT_iPackFiltered 32767;
BA_ "GenSigSNA" SG_ 2566865397 BATT_iPack 32767;
BA_ "GenSigSNA" SG_ 2566865397 BATT_vPackLoad 65535;
BA_ "GenSigSNA" SG_ 2566866165 BATT_vPackModuleMinID 15;
BA_ "GenSigSNA" SG_ 2566866165 BATT_vPackBrickMin 4095;
BA_ "GenSigSNA" SG_ 2566866165 BATT_tPackModuleMaxID 15;
BA_ "GenSigSNA" SG_ 2566866165 BATT_tPackModuleMinID 15;
BA_ "GenSigSNA" SG_ 2566866165 BATT_vPackModuleMaxID 15;
BA_ "GenSigSNA" SG_ 2566866165 BATT_tPackModuleMin 2047;
BA_ "GenSigSNA" SG_ 2566866165 BATT_tPackModuleMax 2047;
BA_ "GenSigSNA" SG_ 2566866165 BATT_vPackBrickMax 4095;
BA_ "GenSigSNA" SG_ 2566866422 BATT_sohcMod_0 65535;
BA_ "GenSigSNA" SG_ 2566866422 BATT_socMod_0 65535;
BA_ "GenSigSNA" SG_ 2566866422 BATT_socLimiting_0 65535;
BA_ "GenSigSNA" SG_ 2566866422 BATT_idSOCLimiting_0 15;
BA_ "GenSigSNA" SG_ 2566866423 BATT_sohcMod_1 65535;
BA_ "GenSigSNA" SG_ 2566866423 BATT_socMod_1 65535;
BA_ "GenSigSNA" SG_ 2566866423 BATT_socLimiting_1 65535;
BA_ "GenSigSNA" SG_ 2566866423 BATT_idSOCLimiting_1 15;
BA_ "GenSigSNA" SG_ 2566866424 BATT_sohcMod_2 65535;
BA_ "GenSigSNA" SG_ 2566866424 BATT_socMod_2 65535;
BA_ "GenSigSNA" SG_ 2566866424 BATT_socLimiting_2 65535;
BA_ "GenSigSNA" SG_ 2566866424 BATT_idSOCLimiting_2 15;
BA_ "GenSigSNA" SG_ 2566866425 BATT_sohcMod_3 65535;
BA_ "GenSigSNA" SG_ 2566866425 BATT_socMod_3 65535;
BA_ "GenSigSNA" SG_ 2566866425 BATT_socLimiting_3 65535;
BA_ "GenSigSNA" SG_ 2566866425 BATT_idSOCLimiting_3 15;
BA_ "GenSigSNA" SG_ 2566866426 BATT_sohcMod_4 65535;
BA_ "GenSigSNA" SG_ 2566866426 BATT_socMod_4 65535;
BA_ "GenSigSNA" SG_ 2566866426 BATT_socLimiting_4 65535;
BA_ "GenSigSNA" SG_ 2566866426 BATT_idSOCLimiting_4 15;
BA_ "GenSigSNA" SG_ 2566866427 BATT_sohcMod_5 65535;
BA_ "GenSigSNA" SG_ 2566866427 BATT_socMod_5 65535;
BA_ "GenSigSNA" SG_ 2566866427 BATT_socLimiting_5 65535;
BA_ "GenSigSNA" SG_ 2566866427 BATT_idSOCLimiting_5 15;
BA_ "GenSigSNA" SG_ 2566866428 BATT_sohcMod_6 65535;
BA_ "GenSigSNA" SG_ 2566866428 BATT_socMod_6 65535;
BA_ "GenSigSNA" SG_ 2566866428 BATT_socLimiting_6 65535;
BA_ "GenSigSNA" SG_ 2566866428 BATT_idSOCLimiting_6 15;
BA_ "GenSigSNA" SG_ 2566866429 BATT_sohcMod_7 65535;
BA_ "GenSigSNA" SG_ 2566866429 BATT_socMod_7 65535;
BA_ "GenSigSNA" SG_ 2566866429 BATT_socLimiting_7 65535;
BA_ "GenSigSNA" SG_ 2566866429 BATT_idSOCLimiting_7 15;
BA_ "GenSigSNA" SG_ 2566866430 BATT_sohcMod_8 65535;
BA_ "GenSigSNA" SG_ 2566866430 BATT_socMod_8 65535;
BA_ "GenSigSNA" SG_ 2566866430 BATT_socLimiting_8 65535;
BA_ "GenSigSNA" SG_ 2566866430 BATT_idSOCLimiting_8 15;
BA_ "GenSigSNA" SG_ 2566866431 BATT_sohcMod_9 65535;
BA_ "GenSigSNA" SG_ 2566866431 BATT_socMod_9 65535;
BA_ "GenSigSNA" SG_ 2566866431 BATT_socLimiting_9 65535;
BA_ "GenSigSNA" SG_ 2566866431 BATT_idSOCLimiting_9 15;
BA_ "GenSigSNA" SG_ 2566866677 BATT_packUserSOC 65535;
BA_ "GenSigSNA" SG_ 2566866677 BATT_packSOC 65535;
BA_ "GenSigSNA" SG_ 2566867189 BATT_vBusMin 65535;
BA_ "GenSigSNA" SG_ 2566867189 BATT_iPackDchLimit10s 32767;
BA_ "GenSigSNA" SG_ 2566867189 BATT_iPackDchLimitCont 32767;
BA_ "GenSigSNA" SG_ 2566870005 BATT_packRemainingCap_Ah 65535;
BA_ "GenSigSNA" SG_ 2566870005 BATT_packFullChargeCap_Ah 65535;
BA_ "GenSigSNA" SG_ 2566870774 BATT_vBrick02_0 65535;
BA_ "GenSigSNA" SG_ 2566870774 BATT_vBrick03_0 65535;
BA_ "GenSigSNA" SG_ 2566870774 BATT_vBrick01_0 65535;
BA_ "GenSigSNA" SG_ 2566870774 BATT_vBrick04_0 65535;
BA_ "GenSigSNA" SG_ 2566870775 BATT_vBrick02_1 65535;
BA_ "GenSigSNA" SG_ 2566870775 BATT_vBrick03_1 65535;
BA_ "GenSigSNA" SG_ 2566870775 BATT_vBrick01_1 65535;
BA_ "GenSigSNA" SG_ 2566870775 BATT_vBrick04_1 65535;
BA_ "GenSigSNA" SG_ 2566870776 BATT_vBrick02_2 65535;
BA_ "GenSigSNA" SG_ 2566870776 BATT_vBrick03_2 65535;
BA_ "GenSigSNA" SG_ 2566870776 BATT_vBrick01_2 65535;
BA_ "GenSigSNA" SG_ 2566870776 BATT_vBrick04_2 65535;
BA_ "GenSigSNA" SG_ 2566870777 BATT_vBrick02_3 65535;
BA_ "GenSigSNA" SG_ 2566870777 BATT_vBrick03_3 65535;
BA_ "GenSigSNA" SG_ 2566870777 BATT_vBrick01_3 65535;
BA_ "GenSigSNA" SG_ 2566870777 BATT_vBrick04_3 65535;
BA_ "GenSigSNA" SG_ 2566870778 BATT_vBrick02_4 65535;
BA_ "GenSigSNA" SG_ 2566870778 BATT_vBrick03_4 65535;
BA_ "GenSigSNA" SG_ 2566870778 BATT_vBrick01_4 65535;
BA_ "GenSigSNA" SG_ 2566870778 BATT_vBrick04_4 65535;
BA_ "GenSigSNA" SG_ 2566870779 BATT_vBrick02_5 65535;
BA_ "GenSigSNA" SG_ 2566870779 BATT_vBrick03_5 65535;
BA_ "GenSigSNA" SG_ 2566870779 BATT_vBrick01_5 65535;
BA_ "GenSigSNA" SG_ 2566870779 BATT_vBrick04_5 65535;
BA_ "GenSigSNA" SG_ 2566870780 BATT_vBrick02_6 65535;
BA_ "GenSigSNA" SG_ 2566870780 BATT_vBrick03_6 65535;
BA_ "GenSigSNA" SG_ 2566870780 BATT_vBrick01_6 65535;
BA_ "GenSigSNA" SG_ 2566870780 BATT_vBrick04_6 65535;
BA_ "GenSigSNA" SG_ 2566870781 BATT_vBrick02_7 65535;
BA_ "GenSigSNA" SG_ 2566870781 BATT_vBrick03_7 65535;
BA_ "GenSigSNA" SG_ 2566870781 BATT_vBrick01_7 65535;
BA_ "GenSigSNA" SG_ 2566870781 BATT_vBrick04_7 65535;
BA_ "GenSigSNA" SG_ 2566870782 BATT_vBrick02_8 65535;
BA_ "GenSigSNA" SG_ 2566870782 BATT_vBrick03_8 65535;
BA_ "GenSigSNA" SG_ 2566870782 BATT_vBrick01_8 65535;
BA_ "GenSigSNA" SG_ 2566870782 BATT_vBrick04_8 65535;
BA_ "GenSigSNA" SG_ 2566870783 BATT_vBrick02_9 65535;
BA_ "GenSigSNA" SG_ 2566870783 BATT_vBrick03_9 65535;
BA_ "GenSigSNA" SG_ 2566870783 BATT_vBrick01_9 65535;
BA_ "GenSigSNA" SG_ 2566870783 BATT_vBrick04_9 65535;
BA_ "GenSigSNA" SG_ 2566881525 BATT_iPackChgLimit10s 65535;
BA_ "GenSigSNA" SG_ 2566881525 BATT_iPackChgLimitCont 65535;
BA_ "GenSigSNA" SG_ 2566881525 BATT_vBusMax 65535;
BA_ "GenSigSNA" SG_ 2566883062 BATT_capBrick04_0 65535;
BA_ "GenSigSNA" SG_ 2566883062 BATT_capBrick03_0 65535;
BA_ "GenSigSNA" SG_ 2566883062 BATT_capBrick02_0 65535;
BA_ "GenSigSNA" SG_ 2566883062 BATT_capBrick01_0 65535;
BA_ "GenSigSNA" SG_ 2566883063 BATT_capBrick04_1 65535;
BA_ "GenSigSNA" SG_ 2566883063 BATT_capBrick03_1 65535;
BA_ "GenSigSNA" SG_ 2566883063 BATT_capBrick02_1 65535;
BA_ "GenSigSNA" SG_ 2566883063 BATT_capBrick01_1 65535;
BA_ "GenSigSNA" SG_ 2566883064 BATT_capBrick04_2 65535;
BA_ "GenSigSNA" SG_ 2566883064 BATT_capBrick03_2 65535;
BA_ "GenSigSNA" SG_ 2566883064 BATT_capBrick02_2 65535;
BA_ "GenSigSNA" SG_ 2566883064 BATT_capBrick01_2 65535;
BA_ "GenSigSNA" SG_ 2566883065 BATT_capBrick04_3 65535;
BA_ "GenSigSNA" SG_ 2566883065 BATT_capBrick03_3 65535;
BA_ "GenSigSNA" SG_ 2566883065 BATT_capBrick02_3 65535;
BA_ "GenSigSNA" SG_ 2566883065 BATT_capBrick01_3 65535;
BA_ "GenSigSNA" SG_ 2566883066 BATT_capBrick04_4 65535;
BA_ "GenSigSNA" SG_ 2566883066 BATT_capBrick03_4 65535;
BA_ "GenSigSNA" SG_ 2566883066 BATT_capBrick02_4 65535;
BA_ "GenSigSNA" SG_ 2566883066 BATT_capBrick01_4 65535;
BA_ "GenSigSNA" SG_ 2566883067 BATT_capBrick04_5 65535;
BA_ "GenSigSNA" SG_ 2566883067 BATT_capBrick03_5 65535;
BA_ "GenSigSNA" SG_ 2566883067 BATT_capBrick02_5 65535;
BA_ "GenSigSNA" SG_ 2566883067 BATT_capBrick01_5 65535;
BA_ "GenSigSNA" SG_ 2566883068 BATT_capBrick04_6 65535;
BA_ "GenSigSNA" SG_ 2566883068 BATT_capBrick03_6 65535;
BA_ "GenSigSNA" SG_ 2566883068 BATT_capBrick02_6 65535;
BA_ "GenSigSNA" SG_ 2566883068 BATT_capBrick01_6 65535;
BA_ "GenSigSNA" SG_ 2566883069 BATT_capBrick04_7 65535;
BA_ "GenSigSNA" SG_ 2566883069 BATT_capBrick03_7 65535;
BA_ "GenSigSNA" SG_ 2566883069 BATT_capBrick02_7 65535;
BA_ "GenSigSNA" SG_ 2566883069 BATT_capBrick01_7 65535;
BA_ "GenSigSNA" SG_ 2566883070 BATT_capBrick04_8 65535;
BA_ "GenSigSNA" SG_ 2566883070 BATT_capBrick03_8 65535;
BA_ "GenSigSNA" SG_ 2566883070 BATT_capBrick02_8 65535;
BA_ "GenSigSNA" SG_ 2566883070 BATT_capBrick01_8 65535;
BA_ "GenSigSNA" SG_ 2566883071 BATT_capBrick04_9 65535;
BA_ "GenSigSNA" SG_ 2566883071 BATT_capBrick03_9 65535;
BA_ "GenSigSNA" SG_ 2566883071 BATT_capBrick02_9 65535;
BA_ "GenSigSNA" SG_ 2566883071 BATT_capBrick01_9 65535;
BA_ "GenSigSNA" SG_ 2566885622 BATT_resMod_0 65535;
BA_ "GenSigSNA" SG_ 2566885622 BATT_voirMod_0 65535;
BA_ "GenSigSNA" SG_ 2566885622 BATT_vModLoad_0 65535;
BA_ "GenSigSNA" SG_ 2566885623 BATT_resMod_1 65535;
BA_ "GenSigSNA" SG_ 2566885623 BATT_voirMod_1 65535;
BA_ "GenSigSNA" SG_ 2566885623 BATT_vModLoad_1 65535;
BA_ "GenSigSNA" SG_ 2566885624 BATT_resMod_2 65535;
BA_ "GenSigSNA" SG_ 2566885624 BATT_voirMod_2 65535;
BA_ "GenSigSNA" SG_ 2566885624 BATT_vModLoad_2 65535;
BA_ "GenSigSNA" SG_ 2566885625 BATT_resMod_3 65535;
BA_ "GenSigSNA" SG_ 2566885625 BATT_voirMod_3 65535;
BA_ "GenSigSNA" SG_ 2566885625 BATT_vModLoad_3 65535;
BA_ "GenSigSNA" SG_ 2566885626 BATT_resMod_4 65535;
BA_ "GenSigSNA" SG_ 2566885626 BATT_voirMod_4 65535;
BA_ "GenSigSNA" SG_ 2566885626 BATT_vModLoad_4 65535;
BA_ "GenSigSNA" SG_ 2566885627 BATT_resMod_5 65535;
BA_ "GenSigSNA" SG_ 2566885627 BATT_voirMod_5 65535;
BA_ "GenSigSNA" SG_ 2566885627 BATT_vModLoad_5 65535;
BA_ "GenSigSNA" SG_ 2566885628 BATT_resMod_6 65535;
BA_ "GenSigSNA" SG_ 2566885628 BATT_voirMod_6 65535;
BA_ "GenSigSNA" SG_ 2566885628 BATT_vModLoad_6 65535;
BA_ "GenSigSNA" SG_ 2566885629 BATT_resMod_7 65535;
BA_ "GenSigSNA" SG_ 2566885629 BATT_voirMod_7 65535;
BA_ "GenSigSNA" SG_ 2566885629 BATT_vModLoad_7 65535;
BA_ "GenSigSNA" SG_ 2566885630 BATT_resMod_8 65535;
BA_ "GenSigSNA" SG_ 2566885630 BATT_voirMod_8 65535;
BA_ "GenSigSNA" SG_ 2566885630 BATT_vModLoad_8 65535;
BA_ "GenSigSNA" SG_ 2566885631 BATT_resMod_9 65535;
BA_ "GenSigSNA" SG_ 2566885631 BATT_voirMod_9 65535;
BA_ "GenSigSNA" SG_ 2566885631 BATT_vModLoad_9 65535;
BA_ "GenSigSNA" SG_ 2566889718 BATT_tModuleMin_0 2047;
BA_ "GenSigSNA" SG_ 2566889718 BATT_vBrickMinID_0 15;
BA_ "GenSigSNA" SG_ 2566889718 BATT_tModuleMaxID_0 15;
BA_ "GenSigSNA" SG_ 2566889718 BATT_vBrickMin_0 4095;
BA_ "GenSigSNA" SG_ 2566889718 BATT_tModuleMinID_0 15;
BA_ "GenSigSNA" SG_ 2566889718 BATT_vBrickMaxID_0 15;
BA_ "GenSigSNA" SG_ 2566889718 BATT_tModuleMax_0 2047;
BA_ "GenSigSNA" SG_ 2566889718 BATT_vBrickMax_0 4095;
BA_ "GenSigSNA" SG_ 2566889719 BATT_vBrickMax_1 4095;
BA_ "GenSigSNA" SG_ 2566889719 BATT_tModuleMinID_1 15;
BA_ "GenSigSNA" SG_ 2566889719 BATT_tModuleMin_1 2047;
BA_ "GenSigSNA" SG_ 2566889719 BATT_vBrickMaxID_1 15;
BA_ "GenSigSNA" SG_ 2566889719 BATT_vBrickMin_1 4095;
BA_ "GenSigSNA" SG_ 2566889719 BATT_tModuleMaxID_1 15;
BA_ "GenSigSNA" SG_ 2566889719 BATT_vBrickMinID_1 15;
BA_ "GenSigSNA" SG_ 2566889719 BATT_tModuleMax_1 2047;
BA_ "GenSigSNA" SG_ 2566889720 BATT_vBrickMax_2 4095;
BA_ "GenSigSNA" SG_ 2566889720 BATT_tModuleMin_2 2047;
BA_ "GenSigSNA" SG_ 2566889720 BATT_vBrickMin_2 4095;
BA_ "GenSigSNA" SG_ 2566889720 BATT_vBrickMinID_2 15;
BA_ "GenSigSNA" SG_ 2566889720 BATT_tModuleMax_2 2047;
BA_ "GenSigSNA" SG_ 2566889720 BATT_tModuleMinID_2 15;
BA_ "GenSigSNA" SG_ 2566889720 BATT_vBrickMaxID_2 15;
BA_ "GenSigSNA" SG_ 2566889720 BATT_tModuleMaxID_2 15;
BA_ "GenSigSNA" SG_ 2566889721 BATT_tModuleMaxID_3 15;
BA_ "GenSigSNA" SG_ 2566889721 BATT_vBrickMaxID_3 15;
BA_ "GenSigSNA" SG_ 2566889721 BATT_tModuleMinID_3 15;
BA_ "GenSigSNA" SG_ 2566889721 BATT_vBrickMinID_3 15;
BA_ "GenSigSNA" SG_ 2566889721 BATT_tModuleMax_3 2047;
BA_ "GenSigSNA" SG_ 2566889721 BATT_tModuleMin_3 2047;
BA_ "GenSigSNA" SG_ 2566889721 BATT_vBrickMin_3 4095;
BA_ "GenSigSNA" SG_ 2566889721 BATT_vBrickMax_3 4095;
BA_ "GenSigSNA" SG_ 2566889722 BATT_tModuleMinID_4 15;
BA_ "GenSigSNA" SG_ 2566889722 BATT_tModuleMaxID_4 15;
BA_ "GenSigSNA" SG_ 2566889722 BATT_vBrickMin_4 4095;
BA_ "GenSigSNA" SG_ 2566889722 BATT_vBrickMax_4 4095;
BA_ "GenSigSNA" SG_ 2566889722 BATT_tModuleMax_4 2047;
BA_ "GenSigSNA" SG_ 2566889722 BATT_tModuleMin_4 2047;
BA_ "GenSigSNA" SG_ 2566889722 BATT_vBrickMinID_4 15;
BA_ "GenSigSNA" SG_ 2566889722 BATT_vBrickMaxID_4 15;
BA_ "GenSigSNA" SG_ 2566889723 BATT_vBrickMax_5 4095;
BA_ "GenSigSNA" SG_ 2566889723 BATT_vBrickMin_5 4095;
BA_ "GenSigSNA" SG_ 2566889723 BATT_tModuleMin_5 2047;
BA_ "GenSigSNA" SG_ 2566889723 BATT_tModuleMaxID_5 15;
BA_ "GenSigSNA" SG_ 2566889723 BATT_tModuleMinID_5 15;
BA_ "GenSigSNA" SG_ 2566889723 BATT_vBrickMaxID_5 15;
BA_ "GenSigSNA" SG_ 2566889723 BATT_vBrickMinID_5 15;
BA_ "GenSigSNA" SG_ 2566889723 BATT_tModuleMax_5 2047;
BA_ "GenSigSNA" SG_ 2566889724 BATT_tModuleMax_6 2047;
BA_ "GenSigSNA" SG_ 2566889724 BATT_vBrickMinID_6 15;
BA_ "GenSigSNA" SG_ 2566889724 BATT_tModuleMinID_6 15;
BA_ "GenSigSNA" SG_ 2566889724 BATT_vBrickMaxID_6 15;
BA_ "GenSigSNA" SG_ 2566889724 BATT_vBrickMax_6 4095;
BA_ "GenSigSNA" SG_ 2566889724 BATT_tModuleMaxID_6 15;
BA_ "GenSigSNA" SG_ 2566889724 BATT_tModuleMin_6 2047;
BA_ "GenSigSNA" SG_ 2566889724 BATT_vBrickMin_6 4095;
BA_ "GenSigSNA" SG_ 2566889725 BATT_tModuleMax_7 2047;
BA_ "GenSigSNA" SG_ 2566889725 BATT_tModuleMin_7 2047;
BA_ "GenSigSNA" SG_ 2566889725 BATT_tModuleMinID_7 15;
BA_ "GenSigSNA" SG_ 2566889725 BATT_vBrickMaxID_7 15;
BA_ "GenSigSNA" SG_ 2566889725 BATT_vBrickMax_7 4095;
BA_ "GenSigSNA" SG_ 2566889725 BATT_vBrickMinID_7 15;
BA_ "GenSigSNA" SG_ 2566889725 BATT_vBrickMin_7 4095;
BA_ "GenSigSNA" SG_ 2566889725 BATT_tModuleMaxID_7 15;
BA_ "GenSigSNA" SG_ 2566889726 BATT_tModuleMinID_8 15;
BA_ "GenSigSNA" SG_ 2566889726 BATT_tModuleMaxID_8 15;
BA_ "GenSigSNA" SG_ 2566889726 BATT_vBrickMaxID_8 15;
BA_ "GenSigSNA" SG_ 2566889726 BATT_vBrickMin_8 4095;
BA_ "GenSigSNA" SG_ 2566889726 BATT_vBrickMax_8 4095;
BA_ "GenSigSNA" SG_ 2566889726 BATT_tModuleMax_8 2047;
BA_ "GenSigSNA" SG_ 2566889726 BATT_tModuleMin_8 2047;
BA_ "GenSigSNA" SG_ 2566889726 BATT_vBrickMinID_8 15;
BA_ "GenSigSNA" SG_ 2566889727 BATT_vBrickMax_9 4095;
BA_ "GenSigSNA" SG_ 2566889727 BATT_tModuleMin_9 2047;
BA_ "GenSigSNA" SG_ 2566889727 BATT_vBrickMin_9 4095;
BA_ "GenSigSNA" SG_ 2566889727 BATT_vBrickMinID_9 15;
BA_ "GenSigSNA" SG_ 2566889727 BATT_tModuleMax_9 2047;
BA_ "GenSigSNA" SG_ 2566889727 BATT_tModuleMinID_9 15;
BA_ "GenSigSNA" SG_ 2566889727 BATT_vBrickMaxID_9 15;
BA_ "GenSigSNA" SG_ 2566889727 BATT_tModuleMaxID_9 15;
BA_ "GenSigSNA" SG_ 2566893814 BATT_pwrModChgLimit_0 65535;
BA_ "GenSigSNA" SG_ 2566893814 BATT_pwrModDchLimit_0 32767;
BA_ "GenSigSNA" SG_ 2566893815 BATT_pwrModChgLimit_1 65535;
BA_ "GenSigSNA" SG_ 2566893815 BATT_pwrModDchLimit_1 32767;
BA_ "GenSigSNA" SG_ 2566893816 BATT_pwrModChgLimit_2 65535;
BA_ "GenSigSNA" SG_ 2566893816 BATT_pwrModDchLimit_2 32767;
BA_ "GenSigSNA" SG_ 2566893817 BATT_pwrModDchLimit_3 32767;
BA_ "GenSigSNA" SG_ 2566893817 BATT_pwrModChgLimit_3 65535;
BA_ "GenSigSNA" SG_ 2566893818 BATT_pwrModChgLimit_4 65535;
BA_ "GenSigSNA" SG_ 2566893818 BATT_pwrModDchLimit_4 32767;
BA_ "GenSigSNA" SG_ 2566893819 BATT_pwrModChgLimit_5 65535;
BA_ "GenSigSNA" SG_ 2566893819 BATT_pwrModDchLimit_5 32767;
BA_ "GenSigSNA" SG_ 2566893820 BATT_pwrModChgLimit_6 65535;
BA_ "GenSigSNA" SG_ 2566893820 BATT_pwrModDchLimit_6 32767;
BA_ "GenSigSNA" SG_ 2566893821 BATT_pwrModChgLimit_7 65535;
BA_ "GenSigSNA" SG_ 2566893821 BATT_pwrModDchLimit_7 32767;
BA_ "GenSigSNA" SG_ 2566893822 BATT_pwrModDchLimit_8 32767;
BA_ "GenSigSNA" SG_ 2566893822 BATT_pwrModChgLimit_8 65535;
BA_ "GenSigSNA" SG_ 2566893823 BATT_pwrModChgLimit_9 65535;
BA_ "GenSigSNA" SG_ 2566893823 BATT_pwrModDchLimit_9 32767;
BA_ "GenSigSNA" SG_ 2566902006 BATT_modFullChargeCap_Ah_0 65535;
BA_ "GenSigSNA" SG_ 2566902006 BATT_modRemainingCap_Ah_0 65535;
BA_ "GenSigSNA" SG_ 2566902007 BATT_modFullChargeCap_Ah_1 65535;
BA_ "GenSigSNA" SG_ 2566902007 BATT_modRemainingCap_Ah_1 65535;
BA_ "GenSigSNA" SG_ 2566902008 BATT_modFullChargeCap_Ah_2 65535;
BA_ "GenSigSNA" SG_ 2566902008 BATT_modRemainingCap_Ah_2 65535;
BA_ "GenSigSNA" SG_ 2566902009 BATT_modFullChargeCap_Ah_3 65535;
BA_ "GenSigSNA" SG_ 2566902009 BATT_modRemainingCap_Ah_3 65535;
BA_ "GenSigSNA" SG_ 2566902010 BATT_modFullChargeCap_Ah_4 65535;
BA_ "GenSigSNA" SG_ 2566902010 BATT_modRemainingCap_Ah_4 65535;
BA_ "GenSigSNA" SG_ 2566902011 BATT_modFullChargeCap_Ah_5 65535;
BA_ "GenSigSNA" SG_ 2566902011 BATT_modRemainingCap_Ah_5 65535;
BA_ "GenSigSNA" SG_ 2566902012 BATT_modFullChargeCap_Ah_6 65535;
BA_ "GenSigSNA" SG_ 2566902012 BATT_modRemainingCap_Ah_6 65535;
BA_ "GenSigSNA" SG_ 2566902013 BATT_modFullChargeCap_Ah_7 65535;
BA_ "GenSigSNA" SG_ 2566902013 BATT_modRemainingCap_Ah_7 65535;
BA_ "GenSigSNA" SG_ 2566902014 BATT_modFullChargeCap_Ah_8 65535;
BA_ "GenSigSNA" SG_ 2566902014 BATT_modRemainingCap_Ah_8 65535;
BA_ "GenSigSNA" SG_ 2566902015 BATT_modFullChargeCap_Ah_9 65535;
BA_ "GenSigSNA" SG_ 2566902015 BATT_modRemainingCap_Ah_9 65535;
BA_ "GenSigSNA" SG_ 2566906102 BATT_vModChgLimit_0 65535;
BA_ "GenSigSNA" SG_ 2566906102 BATT_iModChgLimit30s_0 65535;
BA_ "GenSigSNA" SG_ 2566906102 BATT_iModChgLimit10s_0 65535;
BA_ "GenSigSNA" SG_ 2566906102 BATT_iModChgLimitCont_0 65535;
BA_ "GenSigSNA" SG_ 2566906103 BATT_vModChgLimit_1 65535;
BA_ "GenSigSNA" SG_ 2566906103 BATT_iModChgLimit30s_1 65535;
BA_ "GenSigSNA" SG_ 2566906103 BATT_iModChgLimit10s_1 65535;
BA_ "GenSigSNA" SG_ 2566906103 BATT_iModChgLimitCont_1 65535;
BA_ "GenSigSNA" SG_ 2566906104 BATT_vModChgLimit_2 65535;
BA_ "GenSigSNA" SG_ 2566906104 BATT_iModChgLimit30s_2 65535;
BA_ "GenSigSNA" SG_ 2566906104 BATT_iModChgLimit10s_2 65535;
BA_ "GenSigSNA" SG_ 2566906104 BATT_iModChgLimitCont_2 65535;
BA_ "GenSigSNA" SG_ 2566906105 BATT_vModChgLimit_3 65535;
BA_ "GenSigSNA" SG_ 2566906105 BATT_iModChgLimit30s_3 65535;
BA_ "GenSigSNA" SG_ 2566906105 BATT_iModChgLimit10s_3 65535;
BA_ "GenSigSNA" SG_ 2566906105 BATT_iModChgLimitCont_3 65535;
BA_ "GenSigSNA" SG_ 2566906106 BATT_vModChgLimit_4 65535;
BA_ "GenSigSNA" SG_ 2566906106 BATT_iModChgLimit30s_4 65535;
BA_ "GenSigSNA" SG_ 2566906106 BATT_iModChgLimit10s_4 65535;
BA_ "GenSigSNA" SG_ 2566906106 BATT_iModChgLimitCont_4 65535;
BA_ "GenSigSNA" SG_ 2566906107 BATT_vModChgLimit_5 65535;
BA_ "GenSigSNA" SG_ 2566906107 BATT_iModChgLimit30s_5 65535;
BA_ "GenSigSNA" SG_ 2566906107 BATT_iModChgLimit10s_5 65535;
BA_ "GenSigSNA" SG_ 2566906107 BATT_iModChgLimitCont_5 65535;
BA_ "GenSigSNA" SG_ 2566906108 BATT_vModChgLimit_6 65535;
BA_ "GenSigSNA" SG_ 2566906108 BATT_iModChgLimit30s_6 65535;
BA_ "GenSigSNA" SG_ 2566906108 BATT_iModChgLimit10s_6 65535;
BA_ "GenSigSNA" SG_ 2566906108 BATT_iModChgLimitCont_6 65535;
BA_ "GenSigSNA" SG_ 2566906109 BATT_vModChgLimit_7 65535;
BA_ "GenSigSNA" SG_ 2566906109 BATT_iModChgLimit30s_7 65535;
BA_ "GenSigSNA" SG_ 2566906109 BATT_iModChgLimit10s_7 65535;
BA_ "GenSigSNA" SG_ 2566906109 BATT_iModChgLimitCont_7 65535;
BA_ "GenSigSNA" SG_ 2566906110 BATT_vModChgLimit_8 65535;
BA_ "GenSigSNA" SG_ 2566906110 BATT_iModChgLimit30s_8 65535;
BA_ "GenSigSNA" SG_ 2566906110 BATT_iModChgLimit10s_8 65535;
BA_ "GenSigSNA" SG_ 2566906110 BATT_iModChgLimitCont_8 65535;
BA_ "GenSigSNA" SG_ 2566906111 BATT_vModChgLimit_9 65535;
BA_ "GenSigSNA" SG_ 2566906111 BATT_iModChgLimit30s_9 65535;
BA_ "GenSigSNA" SG_ 2566906111 BATT_iModChgLimit10s_9 65535;
BA_ "GenSigSNA" SG_ 2566906111 BATT_iModChgLimitCont_9 65535;
BA_ "Access" SG_ 2566867445 BATT_chargingCurrent 1;
BA_ "Access" SG_ 2566867445 BATT_chargingVoltage 1;
BA_ "Access" SG_ 2566873333 NODE_ID_CLAIM_RND 1;
BA_ "Access" SG_ 2566873333 NODE_ID_CLAIM_SN 1;
BA_ "Access" SG_ 2566874870 BATT_serialNumber_0 1;
BA_ "Access" SG_ 2566874871 BATT_serialNumber_1 1;
BA_ "Access" SG_ 2566874872 BATT_serialNumber_2 1;
BA_ "Access" SG_ 2566874873 BATT_serialNumber_3 1;
BA_ "Access" SG_ 2566874874 BATT_serialNumber_4 1;
BA_ "Access" SG_ 2566874875 BATT_serialNumber_5 1;
BA_ "Access" SG_ 2566874876 BATT_serialNumber_6 1;
BA_ "Access" SG_ 2566874877 BATT_serialNumber_7 1;
BA_ "Access" SG_ 2566874878 BATT_serialNumber_8 1;
BA_ "Access" SG_ 2566874879 BATT_serialNumber_9 1;
BA_ "Access" SG_ 2566897910 BATT_manufacturerAccess_0 1;
BA_ "Access" SG_ 2566897911 BATT_manufacturerAccess_1 1;
BA_ "Access" SG_ 2566897912 BATT_manufacturerAccess_2 1;
BA_ "Access" SG_ 2566897913 BATT_manufacturerAccess_3 1;
BA_ "Access" SG_ 2566897914 BATT_manufacturerAccess_4 1;
BA_ "Access" SG_ 2566897915 BATT_manufacturerAccess_5 1;
BA_ "Access" SG_ 2566897916 BATT_manufacturerAccess_6 1;
BA_ "Access" SG_ 2566897917 BATT_manufacturerAccess_7 1;
BA_ "Access" SG_ 2566897918 BATT_manufacturerAccess_8 1;
BA_ "Access" SG_ 2566897919 BATT_manufacturerAccess_9 1;
VAL_ 2566862841 BATT_vBrick14_3  65535 "SNA"  ;
VAL_ 2566862841 BATT_vBrick13_3  65535 "SNA"  ;
VAL_ 2566862842 BATT_vBrick13_4  65535 "SNA"  ;
VAL_ 2566862842 BATT_vBrick14_4  65535 "SNA"  ;
VAL_ 2566862843 BATT_vBrick14_5  65535 "SNA"  ;
VAL_ 2566862843 BATT_vBrick13_5  65535 "SNA"  ;
VAL_ 2566862844 BATT_vBrick14_6  65535 "SNA"  ;
VAL_ 2566862844 BATT_vBrick13_6  65535 "SNA"  ;
VAL_ 2566862845 BATT_vBrick13_7  65535 "SNA"  ;
VAL_ 2566862845 BATT_vBrick14_7  65535 "SNA"  ;
VAL_ 2566862846 BATT_vBrick13_8  65535 "SNA"  ;
VAL_ 2566862846 BATT_vBrick14_8  65535 "SNA"  ;
VAL_ 2566862847 BATT_vBrick14_9  65535 "SNA"  ;
VAL_ 2566862847 BATT_vBrick13_9  65535 "SNA"  ;
VAL_ 2566865397 BATT_vPack  65535 "SNA"  ;
VAL_ 2566865397 BATT_iPackFiltered  32767 "SNA"  ;
VAL_ 2566865397 BATT_iPack  32767 "SNA"  ;
VAL_ 2566865397 BATT_vPackLoad  65535 "SNA"  ;
VAL_ 2566866165 BATT_vPackModuleMinID  15 "SNA"  ;
VAL_ 2566866165 BATT_vPackBrickMin  4095 "SNA"  ;
VAL_ 2566866165 BATT_tPackModuleMaxID  15 "SNA"  ;
VAL_ 2566866165 BATT_tPackModuleMinID  15 "SNA"  ;
VAL_ 2566866165 BATT_vPackModuleMaxID  15 "SNA"  ;
VAL_ 2566866165 BATT_tPackModuleMin  2047 "SNA"  ;
VAL_ 2566866165 BATT_tPackModuleMax  2047 "SNA"  ;
VAL_ 2566866165 BATT_vPackBrickMax  4095 "SNA"  ;
VAL_ 2566866422 BATT_sohcMod_0  65535 "SNA"  ;
VAL_ 2566866422 BATT_socMod_0  65535 "SNA"  ;
VAL_ 2566866422 BATT_socLimiting_0  65535 "SNA"  ;
VAL_ 2566866422 BATT_idSOCLimiting_0  15 "SNA"  ;
VAL_ 2566866423 BATT_sohcMod_1  65535 "SNA"  ;
VAL_ 2566866423 BATT_socMod_1  65535 "SNA"  ;
VAL_ 2566866423 BATT_socLimiting_1  65535 "SNA"  ;
VAL_ 2566866423 BATT_idSOCLimiting_1  15 "SNA"  ;
VAL_ 2566866424 BATT_sohcMod_2  65535 "SNA"  ;
VAL_ 2566866424 BATT_socMod_2  65535 "SNA"  ;
VAL_ 2566866424 BATT_socLimiting_2  65535 "SNA"  ;
VAL_ 2566866424 BATT_idSOCLimiting_2  15 "SNA"  ;
VAL_ 2566866425 BATT_sohcMod_3  65535 "SNA"  ;
VAL_ 2566866425 BATT_socMod_3  65535 "SNA"  ;
VAL_ 2566866425 BATT_socLimiting_3  65535 "SNA"  ;
VAL_ 2566866425 BATT_idSOCLimiting_3  15 "SNA"  ;
VAL_ 2566866426 BATT_sohcMod_4  65535 "SNA"  ;
VAL_ 2566866426 BATT_socMod_4  65535 "SNA"  ;
VAL_ 2566866426 BATT_socLimiting_4  65535 "SNA"  ;
VAL_ 2566866426 BATT_idSOCLimiting_4  15 "SNA"  ;
VAL_ 2566866427 BATT_sohcMod_5  65535 "SNA"  ;
VAL_ 2566866427 BATT_socMod_5  65535 "SNA"  ;
VAL_ 2566866427 BATT_socLimiting_5  65535 "SNA"  ;
VAL_ 2566866427 BATT_idSOCLimiting_5  15 "SNA"  ;
VAL_ 2566866428 BATT_sohcMod_6  65535 "SNA"  ;
VAL_ 2566866428 BATT_socMod_6  65535 "SNA"  ;
VAL_ 2566866428 BATT_socLimiting_6  65535 "SNA"  ;
VAL_ 2566866428 BATT_idSOCLimiting_6  15 "SNA"  ;
VAL_ 2566866429 BATT_sohcMod_7  65535 "SNA"  ;
VAL_ 2566866429 BATT_socMod_7  65535 "SNA"  ;
VAL_ 2566866429 BATT_socLimiting_7  65535 "SNA"  ;
VAL_ 2566866429 BATT_idSOCLimiting_7  15 "SNA"  ;
VAL_ 2566866430 BATT_sohcMod_8  65535 "SNA"  ;
VAL_ 2566866430 BATT_socMod_8  65535 "SNA"  ;
VAL_ 2566866430 BATT_socLimiting_8  65535 "SNA"  ;
VAL_ 2566866430 BATT_idSOCLimiting_8  15 "SNA"  ;
VAL_ 2566866431 BATT_sohcMod_9  65535 "SNA"  ;
VAL_ 2566866431 BATT_socMod_9  65535 "SNA"  ;
VAL_ 2566866431 BATT_socLimiting_9  65535 "SNA"  ;
VAL_ 2566866431 BATT_idSOCLimiting_9  15 "SNA"  ;
VAL_ 2566866677 BATT_packUserSOC  65535 "SNA"  ;
VAL_ 2566866677 BATT_packSOC  65535 "SNA"  ;
VAL_ 2566867189 BATT_vBusMin  65535 "SNA"  ;
VAL_ 2566867189 BATT_iPackDchLimit10s  32767 "SNA"  ;
VAL_ 2566867189 BATT_iPackDchLimitCont  32767 "SNA"  ;
VAL_ 2566867445 BATT_chargeStatus  5 "Error"  4 "Complete"  3 "In Progress"  2 "Charge Needed"  1 "Charge Not Needed"  0 "Unknown"  ;
VAL_ 2566867445 BATT_chargeMode  2 "CV"  1 "CC"  0 "Not Active"  ;
VAL_ 2566867445 BATT_chargerMode  1 "Generic"  0 "Delta Q"  ;
VAL_ 2566867701 BATT_packState  10 "Disconnect"  9 "ConnectCharge"  8 "ConnectDrive"  7 "SelectCharge"  6 "SelectDrive"  5 "ChargeStandbyConnect"  4 "Reserved"  3 "Charge"  2 "Drive"  1 "StandbyReady"  0 "StandbyNotReady"  ;
VAL_ 2566870005 BATT_packRemainingCap_Ah  65535 "SNA"  ;
VAL_ 2566870005 BATT_packFullChargeCap_Ah  65535 "SNA"  ;
VAL_ 2566870774 BATT_vBrick02_0  65535 "SNA"  ;
VAL_ 2566870774 BATT_vBrick03_0  65535 "SNA"  ;
VAL_ 2566870774 BATT_vBrick01_0  65535 "SNA"  ;
VAL_ 2566870774 BATT_vBrick04_0  65535 "SNA"  ;
VAL_ 2566870775 BATT_vBrick02_1  65535 "SNA"  ;
VAL_ 2566870775 BATT_vBrick03_1  65535 "SNA"  ;
VAL_ 2566870775 BATT_vBrick01_1  65535 "SNA"  ;
VAL_ 2566870775 BATT_vBrick04_1  65535 "SNA"  ;
VAL_ 2566870776 BATT_vBrick02_2  65535 "SNA"  ;
VAL_ 2566870776 BATT_vBrick03_2  65535 "SNA"  ;
VAL_ 2566870776 BATT_vBrick01_2  65535 "SNA"  ;
VAL_ 2566870776 BATT_vBrick04_2  65535 "SNA"  ;
VAL_ 2566870777 BATT_vBrick02_3  65535 "SNA"  ;
VAL_ 2566870777 BATT_vBrick03_3  65535 "SNA"  ;
VAL_ 2566870777 BATT_vBrick01_3  65535 "SNA"  ;
VAL_ 2566870777 BATT_vBrick04_3  65535 "SNA"  ;
VAL_ 2566870778 BATT_vBrick02_4  65535 "SNA"  ;
VAL_ 2566870778 BATT_vBrick03_4  65535 "SNA"  ;
VAL_ 2566870778 BATT_vBrick01_4  65535 "SNA"  ;
VAL_ 2566870778 BATT_vBrick04_4  65535 "SNA"  ;
VAL_ 2566870779 BATT_vBrick02_5  65535 "SNA"  ;
VAL_ 2566870779 BATT_vBrick03_5  65535 "SNA"  ;
VAL_ 2566870779 BATT_vBrick01_5  65535 "SNA"  ;
VAL_ 2566870779 BATT_vBrick04_5  65535 "SNA"  ;
VAL_ 2566870780 BATT_vBrick02_6  65535 "SNA"  ;
VAL_ 2566870780 BATT_vBrick03_6  65535 "SNA"  ;
VAL_ 2566870780 BATT_vBrick01_6  65535 "SNA"  ;
VAL_ 2566870780 BATT_vBrick04_6  65535 "SNA"  ;
VAL_ 2566870781 BATT_vBrick02_7  65535 "SNA"  ;
VAL_ 2566870781 BATT_vBrick03_7  65535 "SNA"  ;
VAL_ 2566870781 BATT_vBrick01_7  65535 "SNA"  ;
VAL_ 2566870781 BATT_vBrick04_7  65535 "SNA"  ;
VAL_ 2566870782 BATT_vBrick02_8  65535 "SNA"  ;
VAL_ 2566870782 BATT_vBrick03_8  65535 "SNA"  ;
VAL_ 2566870782 BATT_vBrick01_8  65535 "SNA"  ;
VAL_ 2566870782 BATT_vBrick04_8  65535 "SNA"  ;
VAL_ 2566870783 BATT_vBrick02_9  65535 "SNA"  ;
VAL_ 2566870783 BATT_vBrick03_9  65535 "SNA"  ;
VAL_ 2566870783 BATT_vBrick01_9  65535 "SNA"  ;
VAL_ 2566870783 BATT_vBrick04_9  65535 "SNA"  ;
VAL_ 2566874870 BATT_deviceChemistry_0  7 "LiP"  6 "ZnAr"  5 "RAM"  4 "NiZn"  3 "NiMH"  2 "NiCd"  1 "LION"  0 "PbAc"  ;
VAL_ 2566874871 BATT_deviceChemistry_1  7 "LiP"  6 "ZnAr"  5 "RAM"  4 "NiZn"  3 "NiMH"  2 "NiCd"  1 "LION"  0 "PbAc"  ;
VAL_ 2566874872 BATT_deviceChemistry_2  7 "LiP"  6 "ZnAr"  5 "RAM"  4 "NiZn"  3 "NiMH"  2 "NiCd"  1 "LION"  0 "PbAc"  ;
VAL_ 2566874873 BATT_deviceChemistry_3  7 "LiP"  6 "ZnAr"  5 "RAM"  4 "NiZn"  3 "NiMH"  2 "NiCd"  1 "LION"  0 "PbAc"  ;
VAL_ 2566874874 BATT_deviceChemistry_4  7 "LiP"  6 "ZnAr"  5 "RAM"  4 "NiZn"  3 "NiMH"  2 "NiCd"  1 "LION"  0 "PbAc"  ;
VAL_ 2566874875 BATT_deviceChemistry_5  7 "LiP"  6 "ZnAr"  5 "RAM"  4 "NiZn"  3 "NiMH"  2 "NiCd"  1 "LION"  0 "PbAc"  ;
VAL_ 2566874876 BATT_deviceChemistry_6  7 "LiP"  6 "ZnAr"  5 "RAM"  4 "NiZn"  3 "NiMH"  2 "NiCd"  1 "LION"  0 "PbAc"  ;
VAL_ 2566874877 BATT_deviceChemistry_7  7 "LiP"  6 "ZnAr"  5 "RAM"  4 "NiZn"  3 "NiMH"  2 "NiCd"  1 "LION"  0 "PbAc"  ;
VAL_ 2566874878 BATT_deviceChemistry_8  7 "LiP"  6 "ZnAr"  5 "RAM"  4 "NiZn"  3 "NiMH"  2 "NiCd"  1 "LION"  0 "PbAc"  ;
VAL_ 2566874879 BATT_deviceChemistry_9  7 "LiP"  6 "ZnAr"  5 "RAM"  4 "NiZn"  3 "NiMH"  2 "NiCd"  1 "LION"  0 "PbAc"  ;
VAL_ 2566879265 HOST_stateRequest  3 "Sleep"  2 "Charge"  1 "Drive"  0 "None"  ;
VAL_ 2566881525 BATT_iPackChgLimit10s  65535 "SNA"  ;
VAL_ 2566881525 BATT_iPackChgLimitCont  65535 "SNA"  ;
VAL_ 2566881525 BATT_vBusMax  65535 "SNA"  ;
VAL_ 2566883062 BATT_capBrick04_0  65535 "SNA"  ;
VAL_ 2566883062 BATT_capBrick03_0  65535 "SNA"  ;
VAL_ 2566883062 BATT_capBrick02_0  65535 "SNA"  ;
VAL_ 2566883062 BATT_capBrick01_0  65535 "SNA"  ;
VAL_ 2566883063 BATT_capBrick04_1  65535 "SNA"  ;
VAL_ 2566883063 BATT_capBrick03_1  65535 "SNA"  ;
VAL_ 2566883063 BATT_capBrick02_1  65535 "SNA"  ;
VAL_ 2566883063 BATT_capBrick01_1  65535 "SNA"  ;
VAL_ 2566883064 BATT_capBrick04_2  65535 "SNA"  ;
VAL_ 2566883064 BATT_capBrick03_2  65535 "SNA"  ;
VAL_ 2566883064 BATT_capBrick02_2  65535 "SNA"  ;
VAL_ 2566883064 BATT_capBrick01_2  65535 "SNA"  ;
VAL_ 2566883065 BATT_capBrick04_3  65535 "SNA"  ;
VAL_ 2566883065 BATT_capBrick03_3  65535 "SNA"  ;
VAL_ 2566883065 BATT_capBrick02_3  65535 "SNA"  ;
VAL_ 2566883065 BATT_capBrick01_3  65535 "SNA"  ;
VAL_ 2566883066 BATT_capBrick04_4  65535 "SNA"  ;
VAL_ 2566883066 BATT_capBrick03_4  65535 "SNA"  ;
VAL_ 2566883066 BATT_capBrick02_4  65535 "SNA"  ;
VAL_ 2566883066 BATT_capBrick01_4  65535 "SNA"  ;
VAL_ 2566883067 BATT_capBrick04_5  65535 "SNA"  ;
VAL_ 2566883067 BATT_capBrick03_5  65535 "SNA"  ;
VAL_ 2566883067 BATT_capBrick02_5  65535 "SNA"  ;
VAL_ 2566883067 BATT_capBrick01_5  65535 "SNA"  ;
VAL_ 2566883068 BATT_capBrick04_6  65535 "SNA"  ;
VAL_ 2566883068 BATT_capBrick03_6  65535 "SNA"  ;
VAL_ 2566883068 BATT_capBrick02_6  65535 "SNA"  ;
VAL_ 2566883068 BATT_capBrick01_6  65535 "SNA"  ;
VAL_ 2566883069 BATT_capBrick04_7  65535 "SNA"  ;
VAL_ 2566883069 BATT_capBrick03_7  65535 "SNA"  ;
VAL_ 2566883069 BATT_capBrick02_7  65535 "SNA"  ;
VAL_ 2566883069 BATT_capBrick01_7  65535 "SNA"  ;
VAL_ 2566883070 BATT_capBrick04_8  65535 "SNA"  ;
VAL_ 2566883070 BATT_capBrick03_8  65535 "SNA"  ;
VAL_ 2566883070 BATT_capBrick02_8  65535 "SNA"  ;
VAL_ 2566883070 BATT_capBrick01_8  65535 "SNA"  ;
VAL_ 2566883071 BATT_capBrick04_9  65535 "SNA"  ;
VAL_ 2566883071 BATT_capBrick03_9  65535 "SNA"  ;
VAL_ 2566883071 BATT_capBrick02_9  65535 "SNA"  ;
VAL_ 2566883071 BATT_capBrick01_9  65535 "SNA"  ;
VAL_ 2566885622 BATT_resMod_0  65535 "SNA"  ;
VAL_ 2566885622 BATT_voirMod_0  65535 "SNA"  ;
VAL_ 2566885622 BATT_vModLoad_0  65535 "SNA"  ;
VAL_ 2566885623 BATT_resMod_1  65535 "SNA"  ;
VAL_ 2566885623 BATT_voirMod_1  65535 "SNA"  ;
VAL_ 2566885623 BATT_vModLoad_1  65535 "SNA"  ;
VAL_ 2566885624 BATT_resMod_2  65535 "SNA"  ;
VAL_ 2566885624 BATT_voirMod_2  65535 "SNA"  ;
VAL_ 2566885624 BATT_vModLoad_2  65535 "SNA"  ;
VAL_ 2566885625 BATT_resMod_3  65535 "SNA"  ;
VAL_ 2566885625 BATT_voirMod_3  65535 "SNA"  ;
VAL_ 2566885625 BATT_vModLoad_3  65535 "SNA"  ;
VAL_ 2566885626 BATT_resMod_4  65535 "SNA"  ;
VAL_ 2566885626 BATT_voirMod_4  65535 "SNA"  ;
VAL_ 2566885626 BATT_vModLoad_4  65535 "SNA"  ;
VAL_ 2566885627 BATT_resMod_5  65535 "SNA"  ;
VAL_ 2566885627 BATT_voirMod_5  65535 "SNA"  ;
VAL_ 2566885627 BATT_vModLoad_5  65535 "SNA"  ;
VAL_ 2566885628 BATT_resMod_6  65535 "SNA"  ;
VAL_ 2566885628 BATT_voirMod_6  65535 "SNA"  ;
VAL_ 2566885628 BATT_vModLoad_6  65535 "SNA"  ;
VAL_ 2566885629 BATT_resMod_7  65535 "SNA"  ;
VAL_ 2566885629 BATT_voirMod_7  65535 "SNA"  ;
VAL_ 2566885629 BATT_vModLoad_7  65535 "SNA"  ;
VAL_ 2566885630 BATT_resMod_8  65535 "SNA"  ;
VAL_ 2566885630 BATT_voirMod_8  65535 "SNA"  ;
VAL_ 2566885630 BATT_vModLoad_8  65535 "SNA"  ;
VAL_ 2566885631 BATT_resMod_9  65535 "SNA"  ;
VAL_ 2566885631 BATT_voirMod_9  65535 "SNA"  ;
VAL_ 2566885631 BATT_vModLoad_9  65535 "SNA"  ;
VAL_ 2566889718 BATT_tModuleMin_0  2047 "SNA"  ;
VAL_ 2566889718 BATT_vBrickMinID_0  15 "SNA"  ;
VAL_ 2566889718 BATT_tModuleMaxID_0  15 "SNA"  ;
VAL_ 2566889718 BATT_vBrickMin_0  4095 "SNA"  ;
VAL_ 2566889718 BATT_tModuleMinID_0  15 "SNA"  ;
VAL_ 2566889718 BATT_vBrickMaxID_0  15 "SNA"  ;
VAL_ 2566889718 BATT_tModuleMax_0  2047 "SNA"  ;
VAL_ 2566889718 BATT_vBrickMax_0  4095 "SNA"  ;
VAL_ 2566889719 BATT_vBrickMax_1  4095 "SNA"  ;
VAL_ 2566889719 BATT_tModuleMinID_1  15 "SNA"  ;
VAL_ 2566889719 BATT_tModuleMin_1  2047 "SNA"  ;
VAL_ 2566889719 BATT_vBrickMaxID_1  15 "SNA"  ;
VAL_ 2566889719 BATT_vBrickMin_1  4095 "SNA"  ;
VAL_ 2566889719 BATT_tModuleMaxID_1  15 "SNA"  ;
VAL_ 2566889719 BATT_vBrickMinID_1  15 "SNA"  ;
VAL_ 2566889719 BATT_tModuleMax_1  2047 "SNA"  ;
VAL_ 2566889720 BATT_vBrickMax_2  4095 "SNA"  ;
VAL_ 2566889720 BATT_tModuleMin_2  2047 "SNA"  ;
VAL_ 2566889720 BATT_vBrickMin_2  4095 "SNA"  ;
VAL_ 2566889720 BATT_vBrickMinID_2  15 "SNA"  ;
VAL_ 2566889720 BATT_tModuleMax_2  2047 "SNA"  ;
VAL_ 2566889720 BATT_tModuleMinID_2  15 "SNA"  ;
VAL_ 2566889720 BATT_vBrickMaxID_2  15 "SNA"  ;
VAL_ 2566889720 BATT_tModuleMaxID_2  15 "SNA"  ;
VAL_ 2566889721 BATT_tModuleMaxID_3  15 "SNA"  ;
VAL_ 2566889721 BATT_vBrickMaxID_3  15 "SNA"  ;
VAL_ 2566889721 BATT_tModuleMinID_3  15 "SNA"  ;
VAL_ 2566889721 BATT_vBrickMinID_3  15 "SNA"  ;
VAL_ 2566889721 BATT_tModuleMax_3  2047 "SNA"  ;
VAL_ 2566889721 BATT_tModuleMin_3  2047 "SNA"  ;
VAL_ 2566889721 BATT_vBrickMin_3  4095 "SNA"  ;
VAL_ 2566889721 BATT_vBrickMax_3  4095 "SNA"  ;
VAL_ 2566889722 BATT_tModuleMinID_4  15 "SNA"  ;
VAL_ 2566889722 BATT_tModuleMaxID_4  15 "SNA"  ;
VAL_ 2566889722 BATT_vBrickMin_4  4095 "SNA"  ;
VAL_ 2566889722 BATT_vBrickMax_4  4095 "SNA"  ;
VAL_ 2566889722 BATT_tModuleMax_4  2047 "SNA"  ;
VAL_ 2566889722 BATT_tModuleMin_4  2047 "SNA"  ;
VAL_ 2566889722 BATT_vBrickMinID_4  15 "SNA"  ;
VAL_ 2566889722 BATT_vBrickMaxID_4  15 "SNA"  ;
VAL_ 2566889723 BATT_vBrickMax_5  4095 "SNA"  ;
VAL_ 2566889723 BATT_vBrickMin_5  4095 "SNA"  ;
VAL_ 2566889723 BATT_tModuleMin_5  2047 "SNA"  ;
VAL_ 2566889723 BATT_tModuleMaxID_5  15 "SNA"  ;
VAL_ 2566889723 BATT_tModuleMinID_5  15 "SNA"  ;
VAL_ 2566889723 BATT_vBrickMaxID_5  15 "SNA"  ;
VAL_ 2566889723 BATT_vBrickMinID_5  15 "SNA"  ;
VAL_ 2566889723 BATT_tModuleMax_5  2047 "SNA"  ;
VAL_ 2566889724 BATT_tModuleMax_6  2047 "SNA"  ;
VAL_ 2566889724 BATT_vBrickMinID_6  15 "SNA"  ;
VAL_ 2566889724 BATT_tModuleMinID_6  15 "SNA"  ;
VAL_ 2566889724 BATT_vBrickMaxID_6  15 "SNA"  ;
VAL_ 2566889724 BATT_vBrickMax_6  4095 "SNA"  ;
VAL_ 2566889724 BATT_tModuleMaxID_6  15 "SNA"  ;
VAL_ 2566889724 BATT_tModuleMin_6  2047 "SNA"  ;
VAL_ 2566889724 BATT_vBrickMin_6  4095 "SNA"  ;
VAL_ 2566889725 BATT_tModuleMax_7  2047 "SNA"  ;
VAL_ 2566889725 BATT_tModuleMin_7  2047 "SNA"  ;
VAL_ 2566889725 BATT_tModuleMinID_7  15 "SNA"  ;
VAL_ 2566889725 BATT_vBrickMaxID_7  15 "SNA"  ;
VAL_ 2566889725 BATT_vBrickMax_7  4095 "SNA"  ;
VAL_ 2566889725 BATT_vBrickMinID_7  15 "SNA"  ;
VAL_ 2566889725 BATT_vBrickMin_7  4095 "SNA"  ;
VAL_ 2566889725 BATT_tModuleMaxID_7  15 "SNA"  ;
VAL_ 2566889726 BATT_tModuleMinID_8  15 "SNA"  ;
VAL_ 2566889726 BATT_tModuleMaxID_8  15 "SNA"  ;
VAL_ 2566889726 BATT_vBrickMaxID_8  15 "SNA"  ;
VAL_ 2566889726 BATT_vBrickMin_8  4095 "SNA"  ;
VAL_ 2566889726 BATT_vBrickMax_8  4095 "SNA"  ;
VAL_ 2566889726 BATT_tModuleMax_8  2047 "SNA"  ;
VAL_ 2566889726 BATT_tModuleMin_8  2047 "SNA"  ;
VAL_ 2566889726 BATT_vBrickMinID_8  15 "SNA"  ;
VAL_ 2566889727 BATT_vBrickMax_9  4095 "SNA"  ;
VAL_ 2566889727 BATT_tModuleMin_9  2047 "SNA"  ;
VAL_ 2566889727 BATT_vBrickMin_9  4095 "SNA"  ;
VAL_ 2566889727 BATT_vBrickMinID_9  15 "SNA"  ;
VAL_ 2566889727 BATT_tModuleMax_9  2047 "SNA"  ;
VAL_ 2566889727 BATT_tModuleMinID_9  15 "SNA"  ;
VAL_ 2566889727 BATT_vBrickMaxID_9  15 "SNA"  ;
VAL_ 2566889727 BATT_tModuleMaxID_9  15 "SNA"  ;
VAL_ 2566893814 BATT_pwrModChgLimit_0  65535 "SNA"  ;
VAL_ 2566893814 BATT_pwrModDchLimit_0  32767 "SNA"  ;
VAL_ 2566893815 BATT_pwrModChgLimit_1  65535 "SNA"  ;
VAL_ 2566893815 BATT_pwrModDchLimit_1  32767 "SNA"  ;
VAL_ 2566893816 BATT_pwrModChgLimit_2  65535 "SNA"  ;
VAL_ 2566893816 BATT_pwrModDchLimit_2  32767 "SNA"  ;
VAL_ 2566893817 BATT_pwrModDchLimit_3  32767 "SNA"  ;
VAL_ 2566893817 BATT_pwrModChgLimit_3  65535 "SNA"  ;
VAL_ 2566893818 BATT_pwrModChgLimit_4  65535 "SNA"  ;
VAL_ 2566893818 BATT_pwrModDchLimit_4  32767 "SNA"  ;
VAL_ 2566893819 BATT_pwrModChgLimit_5  65535 "SNA"  ;
VAL_ 2566893819 BATT_pwrModDchLimit_5  32767 "SNA"  ;
VAL_ 2566893820 BATT_pwrModChgLimit_6  65535 "SNA"  ;
VAL_ 2566893820 BATT_pwrModDchLimit_6  32767 "SNA"  ;
VAL_ 2566893821 BATT_pwrModChgLimit_7  65535 "SNA"  ;
VAL_ 2566893821 BATT_pwrModDchLimit_7  32767 "SNA"  ;
VAL_ 2566893822 BATT_pwrModDchLimit_8  32767 "SNA"  ;
VAL_ 2566893822 BATT_pwrModChgLimit_8  65535 "SNA"  ;
VAL_ 2566893823 BATT_pwrModChgLimit_9  65535 "SNA"  ;
VAL_ 2566893823 BATT_pwrModDchLimit_9  32767 "SNA"  ;
VAL_ 2566902006 BATT_modFullChargeCap_Ah_0  65535 "SNA"  ;
VAL_ 2566902006 BATT_modRemainingCap_Ah_0  65535 "SNA"  ;
VAL_ 2566902007 BATT_modFullChargeCap_Ah_1  65535 "SNA"  ;
VAL_ 2566902007 BATT_modRemainingCap_Ah_1  65535 "SNA"  ;
VAL_ 2566902008 BATT_modFullChargeCap_Ah_2  65535 "SNA"  ;
VAL_ 2566902008 BATT_modRemainingCap_Ah_2  65535 "SNA"  ;
VAL_ 2566902009 BATT_modFullChargeCap_Ah_3  65535 "SNA"  ;
VAL_ 2566902009 BATT_modRemainingCap_Ah_3  65535 "SNA"  ;
VAL_ 2566902010 BATT_modFullChargeCap_Ah_4  65535 "SNA"  ;
VAL_ 2566902010 BATT_modRemainingCap_Ah_4  65535 "SNA"  ;
VAL_ 2566902011 BATT_modFullChargeCap_Ah_5  65535 "SNA"  ;
VAL_ 2566902011 BATT_modRemainingCap_Ah_5  65535 "SNA"  ;
VAL_ 2566902012 BATT_modFullChargeCap_Ah_6  65535 "SNA"  ;
VAL_ 2566902012 BATT_modRemainingCap_Ah_6  65535 "SNA"  ;
VAL_ 2566902013 BATT_modFullChargeCap_Ah_7  65535 "SNA"  ;
VAL_ 2566902013 BATT_modRemainingCap_Ah_7  65535 "SNA"  ;
VAL_ 2566902014 BATT_modFullChargeCap_Ah_8  65535 "SNA"  ;
VAL_ 2566902014 BATT_modRemainingCap_Ah_8  65535 "SNA"  ;
VAL_ 2566902015 BATT_modFullChargeCap_Ah_9  65535 "SNA"  ;
VAL_ 2566902015 BATT_modRemainingCap_Ah_9  65535 "SNA"  ;
VAL_ 2566906102 BATT_vModChgLimit_0  65535 "SNA"  ;
VAL_ 2566906102 BATT_iModChgLimit30s_0  65535 "SNA"  ;
VAL_ 2566906102 BATT_iModChgLimit10s_0  65535 "SNA"  ;
VAL_ 2566906102 BATT_iModChgLimitCont_0  65535 "SNA"  ;
VAL_ 2566906103 BATT_vModChgLimit_1  65535 "SNA"  ;
VAL_ 2566906103 BATT_iModChgLimit30s_1  65535 "SNA"  ;
VAL_ 2566906103 BATT_iModChgLimit10s_1  65535 "SNA"  ;
VAL_ 2566906103 BATT_iModChgLimitCont_1  65535 "SNA"  ;
VAL_ 2566906104 BATT_vModChgLimit_2  65535 "SNA"  ;
VAL_ 2566906104 BATT_iModChgLimit30s_2  65535 "SNA"  ;
VAL_ 2566906104 BATT_iModChgLimit10s_2  65535 "SNA"  ;
VAL_ 2566906104 BATT_iModChgLimitCont_2  65535 "SNA"  ;
VAL_ 2566906105 BATT_vModChgLimit_3  65535 "SNA"  ;
VAL_ 2566906105 BATT_iModChgLimit30s_3  65535 "SNA"  ;
VAL_ 2566906105 BATT_iModChgLimit10s_3  65535 "SNA"  ;
VAL_ 2566906105 BATT_iModChgLimitCont_3  65535 "SNA"  ;
VAL_ 2566906106 BATT_vModChgLimit_4  65535 "SNA"  ;
VAL_ 2566906106 BATT_iModChgLimit30s_4  65535 "SNA"  ;
VAL_ 2566906106 BATT_iModChgLimit10s_4  65535 "SNA"  ;
VAL_ 2566906106 BATT_iModChgLimitCont_4  65535 "SNA"  ;
VAL_ 2566906107 BATT_vModChgLimit_5  65535 "SNA"  ;
VAL_ 2566906107 BATT_iModChgLimit30s_5  65535 "SNA"  ;
VAL_ 2566906107 BATT_iModChgLimit10s_5  65535 "SNA"  ;
VAL_ 2566906107 BATT_iModChgLimitCont_5  65535 "SNA"  ;
VAL_ 2566906108 BATT_vModChgLimit_6  65535 "SNA"  ;
VAL_ 2566906108 BATT_iModChgLimit30s_6  65535 "SNA"  ;
VAL_ 2566906108 BATT_iModChgLimit10s_6  65535 "SNA"  ;
VAL_ 2566906108 BATT_iModChgLimitCont_6  65535 "SNA"  ;
VAL_ 2566906109 BATT_vModChgLimit_7  65535 "SNA"  ;
VAL_ 2566906109 BATT_iModChgLimit30s_7  65535 "SNA"  ;
VAL_ 2566906109 BATT_iModChgLimit10s_7  65535 "SNA"  ;
VAL_ 2566906109 BATT_iModChgLimitCont_7  65535 "SNA"  ;
VAL_ 2566906110 BATT_vModChgLimit_8  65535 "SNA"  ;
VAL_ 2566906110 BATT_iModChgLimit30s_8  65535 "SNA"  ;
VAL_ 2566906110 BATT_iModChgLimit10s_8  65535 "SNA"  ;
VAL_ 2566906110 BATT_iModChgLimitCont_8  65535 "SNA"  ;
VAL_ 2566906111 BATT_vModChgLimit_9  65535 "SNA"  ;
VAL_ 2566906111 BATT_iModChgLimit30s_9  65535 "SNA"  ;
VAL_ 2566906111 BATT_iModChgLimit10s_9  65535 "SNA"  ;
VAL_ 2566906111 BATT_iModChgLimitCont_9  65535 "SNA"  ;
